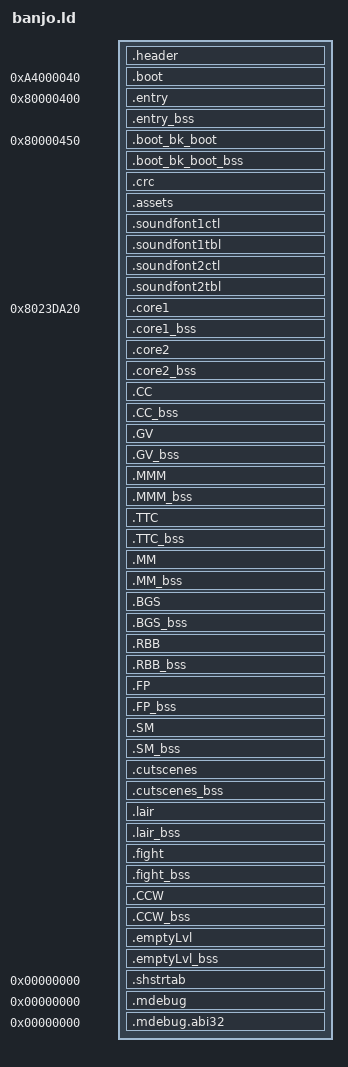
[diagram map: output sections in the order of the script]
SECTIONS
{
    __romPos = 0;
    header_ROM_START = __romPos;
    header_VRAM = ADDR(.header);
    .header : AT(header_ROM_START) SUBALIGN(16)
    {
        FILL(0x00000000);
        header_DATA_START = .;
        build/us.v10/asm/header.s.o(.data);
        header_DATA_END = .;
        header_DATA_SIZE = ABSOLUTE(header_DATA_END - header_DATA_START);
    }
    __romPos += SIZEOF(.header);
    header_ROM_END = __romPos;
    header_VRAM_END = .;

    boot_ROM_START = __romPos;
    boot_VRAM = ADDR(.boot);
    .boot 0xA4000040 : AT(boot_ROM_START) SUBALIGN(16)
    {
        FILL(0x00000000);
        boot_DATA_START = .;
        build/us.v10/bin/ipl3.bin.o(.data);
        build/us.v10/bin/ipl3font.bin.o(.data);
        . = ALIGN(., 16);
        boot_DATA_END = .;
        boot_DATA_SIZE = ABSOLUTE(boot_DATA_END - boot_DATA_START);
    }
    __romPos += SIZEOF(.boot);
    __romPos = ALIGN(__romPos, 16);
    . = ALIGN(., 16);
    boot_ROM_END = __romPos;
    boot_VRAM_END = .;

    entry_ROM_START = __romPos;
    entry_VRAM = ADDR(.entry);
    .entry 0x80000400 : AT(entry_ROM_START) SUBALIGN(16)
    {
        FILL(0x00000000);
        entry_TEXT_START = .;
        build/us.v10/asm/entry.s.o(.text);
        . = ALIGN(., 16);
        entry_TEXT_END = .;
        entry_TEXT_SIZE = ABSOLUTE(entry_TEXT_END - entry_TEXT_START);
        entry_DATA_START = .;
        build/us.v10/asm/entry.s.o(.data);
        . = ALIGN(., 16);
        entry_DATA_END = .;
        entry_DATA_SIZE = ABSOLUTE(entry_DATA_END - entry_DATA_START);
        entry_RODATA_START = .;
        build/us.v10/asm/entry.s.o(.rodata);
        . = ALIGN(., 16);
        entry_RODATA_END = .;
        entry_RODATA_SIZE = ABSOLUTE(entry_RODATA_END - entry_RODATA_START);
    }
    entry_bss_VRAM = ADDR(.entry_bss);
    .entry_bss (NOLOAD) : SUBALIGN(16)
    {
        FILL(0x00000000);
        entry_BSS_START = .;
        build/us.v10/asm/entry.s.o(.bss);
        . = ALIGN(., 16);
        entry_BSS_END = .;
        entry_BSS_SIZE = ABSOLUTE(entry_BSS_END - entry_BSS_START);
    }
    __romPos += SIZEOF(.entry);
    __romPos = ALIGN(__romPos, 16);
    . = ALIGN(., 16);
    entry_ROM_END = __romPos;
    entry_VRAM_END = .;

    boot_bk_boot_ROM_START = __romPos;
    boot_bk_boot_VRAM = ADDR(.boot_bk_boot);
    .boot_bk_boot 0x80000450 : AT(boot_bk_boot_ROM_START) SUBALIGN(16)
    {
        FILL(0x00000000);
        boot_bk_boot_TEXT_START = .;
        build/us.v10/src/boot/bk_boot_1050.c.o(.text);
        build/us.v10/src/boot/rarezip.c.o(.text);
        build/us.v10/src/boot/inflate.c.o(.text);
        build/us.v10/src/boot/overlaytable.c.o(.text);
        build/us.v10/libultra_rom_boot.a:initialize.o(.text);
        build/us.v10/libultra_rom_boot.a:pirawdma.o(.text);
        build/us.v10/libultra_rom_boot.a:pigetstat.o(.text);
        build/us.v10/libultra_rom_boot.a:bzero.o(.text);
        build/us.v10/libultra_rom_boot.a:setsr.o(.text);
        build/us.v10/libultra_rom_boot.a:getsr.o(.text);
        build/us.v10/libultra_rom_boot.a:setfpccsr.o(.text);
        build/us.v10/libultra_rom_boot.a:sirawread.o(.text);
        build/us.v10/libultra_rom_boot.a:sirawwrite.o(.text);
        build/us.v10/libultra_rom_boot.a:exceptasm.o(.text);
        build/us.v10/libultra_rom_boot.a:writebackdcache.o(.text);
        build/us.v10/libultra_rom_boot.a:invalicache.o(.text);
        build/us.v10/libultra_rom_boot.a:maptlbrdb.o(.text);
        build/us.v10/libultra_rom_boot.a:pirawread.o(.text);
        build/us.v10/libultra_rom_boot.a:ll.o(.text);
        build/us.v10/libultra_rom_boot.a:parameters.o(.text);
        build/us.v10/libultra_rom_boot.a:virtualtophysical.o(.text);
        build/us.v10/libultra_rom_boot.a:si.o(.text);
        build/us.v10/libultra_rom_boot.a:thread.o(.text);
        build/us.v10/libultra_rom_boot.a:leointerrupt.o(.text);
        build/us.v10/libultra_rom_boot.a:seteventmesg.o(.text);
        build/us.v10/libultra_rom_boot.a:setintmask.o(.text);
        build/us.v10/libultra_rom_boot.a:destroythread.o(.text);
        build/us.v10/libultra_rom_boot.a:probetlb.o(.text);
        build/us.v10/libultra_rom_boot.a:leodiskinit.o(.text);
        build/us.v10/libultra_rom_boot.a:epirawdma.o(.text);
        build/us.v10/libultra_rom_boot.a:interrupt.o(.text);
        build/us.v10/libultra_rom_boot.a:pimgr.o(.text);
        build/us.v10/libultra_rom_boot.a:cartrominit.o(.text);
        build/us.v10/libultra_rom_boot.a:createmesgqueue.o(.text);
        build/us.v10/libultra_rom_boot.a:piacs.o(.text);
        build/us.v10/libultra_rom_boot.a:getthreadpri.o(.text);
        build/us.v10/libultra_rom_boot.a:setthreadpri.o(.text);
        build/us.v10/libultra_rom_boot.a:createthread.o(.text);
        build/us.v10/libultra_rom_boot.a:devmgr.o(.text);
        build/us.v10/libultra_rom_boot.a:startthread.o(.text);
        build/us.v10/libultra_rom_boot.a:sendmesg.o(.text);
        build/us.v10/libultra_rom_boot.a:recvmesg.o(.text);
        build/us.v10/libultra_rom_boot.a:resetglobalintmask.o(.text);
        build/us.v10/libultra_rom_boot.a:epirawwrite.o(.text);
        build/us.v10/libultra_rom_boot.a:epirawread.o(.text);
        build/us.v10/libultra_rom_boot.a:setglobalintmask.o(.text);
        build/us.v10/libultra_rom_boot.a:yieldthread.o(.text);
        build/us.v10/libultra_rom_boot.a:kdebugserver.o(.text);
        . = ALIGN(., 16);
        boot_bk_boot_TEXT_END = .;
        boot_bk_boot_TEXT_SIZE = ABSOLUTE(boot_bk_boot_TEXT_END - boot_bk_boot_TEXT_START);
        boot_bk_boot_DATA_START = .;
        build/us.v10/src/boot/bk_boot_1050.c.o(.data);
        build/us.v10/src/boot/rarezip.c.o(.data);
        build/us.v10/src/boot/inflate.c.o(.data);
        build/us.v10/src/boot/overlaytable.c.o(.data);
        build/us.v10/libultra_rom_boot.a:initialize.o(.data);
        build/us.v10/libultra_rom_boot.a:exceptasm.o(.data);
        build/us.v10/libultra_rom_boot.a:thread.o(.data);
        build/us.v10/libultra_rom_boot.a:pimgr.o(.data);
        build/us.v10/libultra_rom_boot.a:piacs.o(.data);
        . = ALIGN(., 16);
        boot_bk_boot_DATA_END = .;
        boot_bk_boot_DATA_SIZE = ABSOLUTE(boot_bk_boot_DATA_END - boot_bk_boot_DATA_START);
        boot_bk_boot_RODATA_START = .;
        build/us.v10/src/boot/bk_boot_1050.c.o(.rodata);
        build/us.v10/src/boot/rarezip.c.o(.rodata);
        build/us.v10/src/boot/inflate.c.o(.rodata);
        build/us.v10/src/boot/overlaytable.c.o(.rodata);
        build/us.v10/libultra_rom_boot.a:exceptasm.o(.rodata);
        build/us.v10/libultra_rom_boot.a:setintmask.o(.rodata);
        build/us.v10/libultra_rom_boot.a:devmgr.o(.rodata);
        . = ALIGN(., 16);
        boot_bk_boot_RODATA_END = .;
        boot_bk_boot_RODATA_SIZE = ABSOLUTE(boot_bk_boot_RODATA_END - boot_bk_boot_RODATA_START);
    }
    boot_bk_boot_bss_VRAM = ADDR(.boot_bk_boot_bss);
    .boot_bk_boot_bss (NOLOAD) : SUBALIGN(16)
    {
        FILL(0x00000000);
        boot_bk_boot_BSS_START = .;
        build/us.v10/src/boot/bk_boot_1050.c.o(.bss);
        build/us.v10/src/boot/rarezip.c.o(.bss);
        build/us.v10/src/boot/inflate.c.o(.bss);
        build/us.v10/src/boot/overlaytable.c.o(.bss);
        build/us.v10/libultra_rom_boot.a:initialize.o(.bss);
        build/us.v10/libultra_rom_boot.a:kdebugserver.o(.bss);
        build/us.v10/libultra_rom_boot.a:leointerrupt.o(.bss);
        build/us.v10/libultra_rom_boot.a:seteventmesg.o(.bss);
        build/us.v10/libultra_rom_boot.a:leodiskinit.o(.bss);
        build/us.v10/libultra_rom_boot.a:pimgr.o(.bss);
        build/us.v10/libultra_rom_boot.a:cartrominit.o(.bss);
        build/us.v10/libultra_rom_boot.a:piacs.o(.bss);
        . = ALIGN(., 16);
        boot_bk_boot_BSS_END = .;
        boot_bk_boot_BSS_SIZE = ABSOLUTE(boot_bk_boot_BSS_END - boot_bk_boot_BSS_START);
    }
    __romPos += SIZEOF(.boot_bk_boot);
    __romPos = ALIGN(__romPos, 16);
    . = ALIGN(., 16);
    boot_bk_boot_ROM_END = __romPos;
    boot_bk_boot_VRAM_END = .;

    crc_ROM_START = __romPos;
    crc_VRAM = ADDR(.crc);
    .crc : AT(crc_ROM_START) SUBALIGN(16)
    {
        FILL(0x00000000);
        crc_DATA_START = .;
        build/us.v10/bin/crc.bin.o(.data);
        . = ALIGN(., 16);
        crc_DATA_END = .;
        crc_DATA_SIZE = ABSOLUTE(crc_DATA_END - crc_DATA_START);
    }
    __romPos += SIZEOF(.crc);
    __romPos = ALIGN(__romPos, 16);
    . = ALIGN(., 16);
    crc_ROM_END = __romPos;
    crc_VRAM_END = .;

    assets_ROM_START = __romPos;
    assets_VRAM = ADDR(.assets);
    .assets : AT(assets_ROM_START) SUBALIGN(16)
    {
        FILL(0x00000000);
        assets_DATA_START = .;
        build/us.v10/bin/assets.bin.o(.data);
        assets_DATA_END = .;
        assets_DATA_SIZE = ABSOLUTE(assets_DATA_END - assets_DATA_START);
    }
    __romPos += SIZEOF(.assets);
    assets_ROM_END = __romPos;
    assets_VRAM_END = .;

    soundfont1ctl_ROM_START = __romPos;
    soundfont1ctl_VRAM = ADDR(.soundfont1ctl);
    .soundfont1ctl : AT(soundfont1ctl_ROM_START) SUBALIGN(16)
    {
        FILL(0x00000000);
        soundfont1ctl_DATA_START = .;
        build/us.v10/bin/soundfont1ctl.bin.o(.data);
        soundfont1ctl_DATA_END = .;
        soundfont1ctl_DATA_SIZE = ABSOLUTE(soundfont1ctl_DATA_END - soundfont1ctl_DATA_START);
    }
    __romPos += SIZEOF(.soundfont1ctl);
    soundfont1ctl_ROM_END = __romPos;
    soundfont1ctl_VRAM_END = .;

    soundfont1tbl_ROM_START = __romPos;
    soundfont1tbl_VRAM = ADDR(.soundfont1tbl);
    .soundfont1tbl : AT(soundfont1tbl_ROM_START) SUBALIGN(16)
    {
        FILL(0x00000000);
        soundfont1tbl_DATA_START = .;
        build/us.v10/bin/soundfont1tbl.bin.o(.data);
        soundfont1tbl_DATA_END = .;
        soundfont1tbl_DATA_SIZE = ABSOLUTE(soundfont1tbl_DATA_END - soundfont1tbl_DATA_START);
    }
    __romPos += SIZEOF(.soundfont1tbl);
    soundfont1tbl_ROM_END = __romPos;
    soundfont1tbl_VRAM_END = .;

    soundfont2ctl_ROM_START = __romPos;
    soundfont2ctl_VRAM = ADDR(.soundfont2ctl);
    .soundfont2ctl : AT(soundfont2ctl_ROM_START) SUBALIGN(16)
    {
        FILL(0x00000000);
        soundfont2ctl_DATA_START = .;
        build/us.v10/bin/soundfont2ctl.bin.o(.data);
        soundfont2ctl_DATA_END = .;
        soundfont2ctl_DATA_SIZE = ABSOLUTE(soundfont2ctl_DATA_END - soundfont2ctl_DATA_START);
    }
    __romPos += SIZEOF(.soundfont2ctl);
    soundfont2ctl_ROM_END = __romPos;
    soundfont2ctl_VRAM_END = .;

    soundfont2tbl_ROM_START = __romPos;
    soundfont2tbl_VRAM = ADDR(.soundfont2tbl);
    .soundfont2tbl : AT(soundfont2tbl_ROM_START) SUBALIGN(16)
    {
        FILL(0x00000000);
        soundfont2tbl_DATA_START = .;
        build/us.v10/bin/soundfont2tbl.bin.o(.data);
        soundfont2tbl_DATA_END = .;
        soundfont2tbl_DATA_SIZE = ABSOLUTE(soundfont2tbl_DATA_END - soundfont2tbl_DATA_START);
    }
    __romPos += SIZEOF(.soundfont2tbl);
    soundfont2tbl_ROM_END = __romPos;
    soundfont2tbl_VRAM_END = .;

    core1_ROM_START = __romPos;
    core1_VRAM = ADDR(.core1);
    .core1 0x8023DA20 : AT(core1_ROM_START) SUBALIGN(4)
    {
        FILL(0x00000000);
        core1_TEXT_START = .;
        build/us.v10/src/core1/code_0.c.o(.text);
        build/us.v10/src/core1/code_660.c.o(.text);
        build/us.v10/src/core1/inflate.c.o(.text);
        build/us.v10/src/core1/code_1D00.c.o(.text);
        build/us.v10/src/core1/pimanager.c.o(.text);
        build/us.v10/src/core1/defragmanager.c.o(.text);
        build/us.v10/src/core1/stub_2FA0.c.o(.text);
        build/us.v10/src/core1/initthread.c.o(.text);
        build/us.v10/src/core1/code_3250.c.o(.text);
        build/us.v10/src/core1/stub_3A70.c.o(.text);
        build/us.v10/src/core1/code_5650.c.o(.text);
        build/us.v10/src/core1/code_7090.c.o(.text);
        build/us.v10/src/core1/code_72B0.c.o(.text);
        build/us.v10/src/core1/code_7F60.c.o(.text);
        build/us.v10/src/core1/code_8C50.c.o(.text);
        build/us.v10/src/core1/debugtext.c.o(.text);
        build/us.v10/src/core1/framebufferdraw.c.o(.text);
        build/us.v10/src/core1/code_CE60.c.o(.text);
        build/us.v10/src/core1/vimgr.c.o(.text);
        build/us.v10/src/core1/viewport.c.o(.text);
        build/us.v10/src/core1/joy.c.o(.text);
        build/us.v10/src/core1/code_11AC0.c.o(.text);
        build/us.v10/src/core1/bamotor.c.o(.text);
        build/us.v10/src/core1/stub_13640.c.o(.text);
        build/us.v10/src/core1/sprite.c.o(.text);
        build/us.v10/src/core1/overlaymanager.c.o(.text);
        build/us.v10/src/core1/mlmtx.c.o(.text);
        build/us.v10/asm/core1/bkmemops64.s.o(.text);
        build/us.v10/src/core1/overlay.c.o(.text);
        build/us.v10/src/core1/depthbuffer.c.o(.text);
        build/us.v10/src/core1/code_15B30.c.o(.text);
        build/us.v10/src/core1/memory.c.o(.text);
        build/us.v10/src/core1/eeprom.c.o(.text);
        build/us.v10/src/core1/ucode.c.o(.text);
        build/us.v10/src/core1/lookup.c.o(.text);
        build/us.v10/src/core1/ml.c.o(.text);
        build/us.v10/src/core1/musicplayer.c.o(.text);
        build/us.v10/src/core1/stub_1D590.c.o(.text);
        build/us.v10/asm/core1/bkgetsr.s.o(.text);
        build/us.v10/src/core1/code_1D5D0.c.o(.text);
        build/us.v10/src/core1/sns.c.o(.text);
        build/us.v10/src/core1/glcrc.c.o(.text);
        build/us.v10/asm/core1/code_1E820.s.o(.text);
        build/us.v10/src/core1/n_audio/n_sl.c.o(.text);
        build/us.v10/src/core1/n_audio/n_synthesizer.c.o(.text);
        build/us.v10/libultra_rom.a:event.o(.text);
        build/us.v10/src/core1/n_audio/n_synaddplayer.c.o(.text);
        build/us.v10/src/core1/n_audio/n_synallocvoice.c.o(.text);
        build/us.v10/src/core1/n_audio/n_synsetvol.c.o(.text);
        build/us.v10/src/core1/n_audio/n_synstartvoice.c.o(.text);
        build/us.v10/src/core1/n_audio/n_synsetpan.c.o(.text);
        build/us.v10/src/core1/n_audio/n_synsetpitch.c.o(.text);
        build/us.v10/src/core1/n_audio/n_synsetfxmix.c.o(.text);
        build/us.v10/src/core1/n_audio/n_synstopvoice.c.o(.text);
        build/us.v10/src/core1/n_audio/n_synfreevoice.c.o(.text);
        build/us.v10/src/core1/n_audio/n_csplayer.c.o(.text);
        build/us.v10/libultra_rom.a:cspsetbank.o(.text);
        build/us.v10/libultra_rom.a:cspstop.o(.text);
        build/us.v10/src/core1/n_audio/n_csq.c.o(.text);
        build/us.v10/libultra_rom.a:cspsetseq.o(.text);
        build/us.v10/libultra_rom.a:cspplay.o(.text);
        build/us.v10/libultra_rom.a:cspsetvol.o(.text);
        build/us.v10/src/core1/ultra/audio/code_219D0.c.o(.text);
        build/us.v10/libultra_rom.a:cspsettempo.o(.text);
        build/us.v10/src/core1/n_audio/code_21A80.c.o(.text);
        build/us.v10/libultra_rom.a:cspgettempo.o(.text);
        build/us.v10/src/core1/ultra/audio/code_21AF0.c.o(.text);
        build/us.v10/src/core1/n_audio/code_21B50.c.o(.text);
        build/us.v10/src/core1/n_audio/n_syndelete.c.o(.text);
        build/us.v10/src/core1/n_audio/n_synallocfx.c.o(.text);
        build/us.v10/src/core1/n_audio/n_reverb.c.o(.text);
        build/us.v10/src/core1/n_audio/n_auxbus.c.o(.text);
        build/us.v10/src/core1/n_audio/n_drvrNew.c.o(.text);
        build/us.v10/src/core1/n_audio/n_save.c.o(.text);
        build/us.v10/src/core1/n_audio/n_envresample.c.o(.text);
        build/us.v10/src/core1/n_audio/n_env.c.o(.text);
        build/us.v10/src/core1/n_audio/n_seqplayer.c.o(.text);
        build/us.v10/src/core1/n_audio/n_synstartvoiceparam.c.o(.text);
        build/us.v10/src/core1/n_audio/n_mainbus.c.o(.text);
        build/us.v10/src/core1/n_audio/n_load.c.o(.text);
        build/us.v10/src/core1/n_audio/n_adpcm.c.o(.text);
        build/us.v10/src/core1/n_audio/n_resample.c.o(.text);
        build/us.v10/src/core1/n_audio/n_seq.c.o(.text);
        build/us.v10/src/core1/n_audio/n_synsetpriority.c.o(.text);
        build/us.v10/libultra_rom.a:bzero.o(.text);
        build/us.v10/libultra_rom.a:writebackdcacheall.o(.text);
        build/us.v10/libultra_rom.a:initialize.o(.text);
        build/us.v10/libultra_rom.a:createthread.o(.text);
        build/us.v10/libultra_rom.a:sinf.o(.text);
        build/us.v10/libultra_rom.a:cents2ratio.o(.text);
        build/us.v10/libultra_rom.a:heapinit.o(.text);
        build/us.v10/libultra_rom.a:parameters.o(.text);
        build/us.v10/libultra_rom.a:createmesgqueue.o(.text);
        build/us.v10/libultra_rom.a:aisetfreq.o(.text);
        build/us.v10/libultra_rom.a:sl.o(.text);
        build/us.v10/libultra_rom.a:heapalloc.o(.text);
        build/us.v10/libultra_rom.a:recvmesg.o(.text);
        build/us.v10/libultra_rom.a:aigetlen.o(.text);
        build/us.v10/libultra_rom.a:virtualtophysical.o(.text);
        build/us.v10/libultra_rom.a:aisetnextbuf.o(.text);
        build/us.v10/libultra_rom.a:pidma.o(.text);
        build/us.v10/libultra_rom.a:stopthread.o(.text);
        build/us.v10/libultra_rom.a:startthread.o(.text);
        build/us.v10/libultra_rom.a:writebackdcache.o(.text);
        build/us.v10/libultra_rom.a:invaldcache.o(.text);
        build/us.v10/libultra_rom.a:pimgr.o(.text);
        build/us.v10/libultra_rom.a:destroythread.o(.text);
        build/us.v10/libultra_rom.a:sendmesg.o(.text);
        build/us.v10/libultra_rom.a:setthreadpri.o(.text);
        build/us.v10/libultra_rom.a:mtxutil.o(.text);
        build/us.v10/libultra_rom.a:sqrtf.o(.text);
        build/us.v10/libultra_rom.a:cosf.o(.text);
        build/us.v10/libultra_rom.a:setintmask.o(.text);
        build/us.v10/libultra_rom.a:dpsetstat.o(.text);
        build/us.v10/libultra_rom.a:sptask.o(.text);
        build/us.v10/libultra_rom.a:dpgetstat.o(.text);
        build/us.v10/libultra_rom.a:vigetcurrframebuf.o(.text);
        build/us.v10/libultra_rom.a:stoptimer.o(.text);
        build/us.v10/libultra_rom.a:settimer.o(.text);
        build/us.v10/libultra_rom.a:ll.o(.text);
        build/us.v10/libultra_rom.a:sptaskyielded.o(.text);
        build/us.v10/libultra_rom.a:sptaskyield.o(.text);
        build/us.v10/libultra_rom.a:visetmode.o(.text);
        build/us.v10/libultra_rom.a:seteventmesg.o(.text);
        build/us.v10/libultra_rom.a:vimgr.o(.text);
        build/us.v10/libultra_rom.a:visetspecial.o(.text);
        build/us.v10/libultra_rom.a:viswapbuf.o(.text);
        build/us.v10/libultra_rom.a:visetevent.o(.text);
        build/us.v10/libultra_rom.a:vigetnextframebuf.o(.text);
        build/us.v10/libultra_rom.a:viblack.o(.text);
        build/us.v10/libultra_rom.a:ortho.o(.text);
        build/us.v10/libultra_rom.a:translate.o(.text);
        build/us.v10/libultra_rom.a:rotate.o(.text);
        build/us.v10/libultra_rom.a:contreaddata.o(.text);
        build/us.v10/libultra_rom.a:controller.o(.text);
        build/us.v10/libultra_rom.a:contsetch.o(.text);
        build/us.v10/libultra_rom.a:bnkf.o(.text);
        build/us.v10/libultra_rom.a:gettime.o(.text);
        build/us.v10/libultra_rom.a:cseq.o(.text);
        build/us.v10/libultra_rom.a:motor.o(.text);
        build/us.v10/libultra_rom.a:pfsinit.o(.text);
        build/us.v10/libultra_rom.a:invalicache.o(.text);
        build/us.v10/libultra_rom.a:conteeplongwrite.o(.text);
        build/us.v10/libultra_rom.a:conteeplongread.o(.text);
        build/us.v10/libultra_rom.a:piread.o(.text);
        build/us.v10/libultra_rom.a:copy.o(.text);
        build/us.v10/libultra_rom.a:drvrnew.o(.text);
        build/us.v10/libultra_rom.a:reverb.o(.text);
        build/us.v10/libultra_rom.a:syncprintf.o(.text);
        build/us.v10/libultra_rom.a:seq.o(.text);
        build/us.v10/libultra_rom.a:setsr.o(.text);
        build/us.v10/libultra_rom.a:getsr.o(.text);
        build/us.v10/libultra_rom.a:setfpccsr.o(.text);
        build/us.v10/libultra_rom.a:sirawread.o(.text);
        build/us.v10/libultra_rom.a:sirawwrite.o(.text);
        build/us.v10/libultra_rom.a:exceptasm.o(.text);
        build/us.v10/libultra_rom.a:maptlbrdb.o(.text);
        build/us.v10/libultra_rom.a:pirawread.o(.text);
        build/us.v10/libultra_rom.a:interrupt.o(.text);
        build/us.v10/libultra_rom.a:thread.o(.text);
        build/us.v10/libultra_rom.a:synthesizer.o(.text);
        build/us.v10/libultra_rom.a:syndelete.o(.text);
        build/us.v10/libultra_rom.a:probetlb.o(.text);
        build/us.v10/libultra_rom.a:ai.o(.text);
        build/us.v10/libultra_rom.a:jammesg.o(.text);
        build/us.v10/libultra_rom.a:pigetcmdq.o(.text);
        build/us.v10/libultra_rom.a:cartrominit.o(.text);
        build/us.v10/libultra_rom.a:leodiskinit.o(.text);
        build/us.v10/libultra_rom.a:piacs.o(.text);
        build/us.v10/libultra_rom.a:getthreadpri.o(.text);
        build/us.v10/libultra_rom.a:pirawdma.o(.text);
        build/us.v10/libultra_rom.a:epirawdma.o(.text);
        build/us.v10/libultra_rom.a:devmgr.o(.text);
        build/us.v10/libultra_rom.a:bcopy.o(.text);
        build/us.v10/libultra_rom.a:spsetstat.o(.text);
        build/us.v10/libultra_rom.a:spsetpc.o(.text);
        build/us.v10/libultra_rom.a:sprawdma.o(.text);
        build/us.v10/libultra_rom.a:sp.o(.text);
        build/us.v10/libultra_rom.a:vi.o(.text);
        build/us.v10/libultra_rom.a:timerintr.o(.text);
        build/us.v10/libultra_rom.a:setcompare.o(.text);
        build/us.v10/libultra_rom.a:spgetstat.o(.text);
        build/us.v10/libultra_rom.a:vigetcurrcontext.o(.text);
        build/us.v10/libultra_rom.a:viswapcontext.o(.text);
        build/us.v10/libultra_rom.a:getcount.o(.text);
        build/us.v10/libultra_rom.a:normalize.o(.text);
        build/us.v10/libultra_rom.a:siacs.o(.text);
        build/us.v10/libultra_rom.a:sirawdma.o(.text);
        build/us.v10/libultra_rom.a:pfsisplug.o(.text);
        build/us.v10/libultra_rom.a:crc.o(.text);
        build/us.v10/libultra_rom.a:contramwrite.o(.text);
        build/us.v10/libultra_rom.a:contramread.o(.text);
        build/us.v10/libultra_rom.a:pfsgetstatus.o(.text);
        build/us.v10/libultra_rom.a:contpfs.o(.text);
        build/us.v10/libultra_rom.a:pfschecker.o(.text);
        build/us.v10/libultra_rom.a:conteepwrite.o(.text);
        build/us.v10/libultra_rom.a:conteepread.o(.text);
        build/us.v10/libultra_rom.a:filter.o(.text);
        build/us.v10/libultra_rom.a:env.o(.text);
        build/us.v10/libultra_rom.a:load.o(.text);
        build/us.v10/libultra_rom.a:resample.o(.text);
        build/us.v10/libultra_rom.a:auxbus.o(.text);
        build/us.v10/libultra_rom.a:mainbus.o(.text);
        build/us.v10/libultra_rom.a:save.o(.text);
        build/us.v10/libultra_rom.a:si.o(.text);
        build/us.v10/libultra_rom.a:leointerrupt.o(.text);
        build/us.v10/libultra_rom.a:synallocfx.o(.text);
        build/us.v10/libultra_rom.a:resetglobalintmask.o(.text);
        build/us.v10/libultra_rom.a:epirawwrite.o(.text);
        build/us.v10/libultra_rom.a:epirawread.o(.text);
        build/us.v10/libultra_rom.a:setglobalintmask.o(.text);
        build/us.v10/libultra_rom.a:yieldthread.o(.text);
        build/us.v10/asm/data/core1/n_aspMain.s.o(.text);
        build/us.v10/asm/data/core1/gSPF3DEX_fifo.s.o(.text);
        build/us.v10/asm/data/core1/gSPL3DEX_fifo.s.o(.text);
        core1_DATA_START_OFFSET = .;
        . = ALIGN(., 16);
        core1_TEXT_END = .;
        core1_TEXT_SIZE = ABSOLUTE(core1_TEXT_END - core1_TEXT_START);
        core1_DATA_START = .;
        build/us.v10/src/core1/code_0.c.o(.data);
        build/us.v10/src/core1/code_660.c.o(.data);
        build/us.v10/src/core1/inflate.c.o(.data);
        build/us.v10/src/core1/code_1D00.c.o(.data);
        build/us.v10/src/core1/pimanager.c.o(.data);
        build/us.v10/src/core1/defragmanager.c.o(.data);
        build/us.v10/src/core1/stub_2FA0.c.o(.data);
        build/us.v10/src/core1/initthread.c.o(.data);
        build/us.v10/src/core1/code_3250.c.o(.data);
        build/us.v10/src/core1/stub_3A70.c.o(.data);
        build/us.v10/src/core1/code_5650.c.o(.data);
        build/us.v10/src/core1/code_7090.c.o(.data);
        build/us.v10/src/core1/code_72B0.c.o(.data);
        build/us.v10/src/core1/code_7F60.c.o(.data);
        build/us.v10/src/core1/code_8C50.c.o(.data);
        build/us.v10/src/core1/debugtext.c.o(.data);
        build/us.v10/src/core1/framebufferdraw.c.o(.data);
        build/us.v10/src/core1/code_CE60.c.o(.data);
        build/us.v10/src/core1/vimgr.c.o(.data);
        build/us.v10/src/core1/viewport.c.o(.data);
        build/us.v10/src/core1/joy.c.o(.data);
        build/us.v10/src/core1/code_11AC0.c.o(.data);
        build/us.v10/src/core1/bamotor.c.o(.data);
        build/us.v10/src/core1/stub_13640.c.o(.data);
        build/us.v10/src/core1/sprite.c.o(.data);
        build/us.v10/src/core1/overlaymanager.c.o(.data);
        build/us.v10/src/core1/mlmtx.c.o(.data);
        build/us.v10/asm/core1/bkmemops64.s.o(.data);
        build/us.v10/src/core1/overlay.c.o(.data);
        build/us.v10/src/core1/depthbuffer.c.o(.data);
        build/us.v10/src/core1/code_15B30.c.o(.data);
        build/us.v10/src/core1/memory.c.o(.data);
        build/us.v10/src/core1/eeprom.c.o(.data);
        build/us.v10/src/core1/ucode.c.o(.data);
        build/us.v10/src/core1/lookup.c.o(.data);
        build/us.v10/src/core1/ml.c.o(.data);
        build/us.v10/src/core1/musicplayer.c.o(.data);
        build/us.v10/src/core1/stub_1D590.c.o(.data);
        build/us.v10/asm/core1/bkgetsr.s.o(.data);
        build/us.v10/src/core1/code_1D5D0.c.o(.data);
        build/us.v10/src/core1/sns.c.o(.data);
        build/us.v10/src/core1/glcrc.c.o(.data);
        build/us.v10/asm/core1/code_1E820.s.o(.data);
        build/us.v10/src/core1/data_1E820.c.o(.data);
        build/us.v10/src/core1/n_audio/n_sl.c.o(.data);
        build/us.v10/src/core1/n_audio/n_synthesizer.c.o(.data);
        build/us.v10/src/core1/n_audio/n_synaddplayer.c.o(.data);
        build/us.v10/src/core1/n_audio/n_synallocvoice.c.o(.data);
        build/us.v10/src/core1/n_audio/n_synsetvol.c.o(.data);
        build/us.v10/src/core1/n_audio/n_synstartvoice.c.o(.data);
        build/us.v10/src/core1/n_audio/n_synsetpan.c.o(.data);
        build/us.v10/src/core1/n_audio/n_synsetpitch.c.o(.data);
        build/us.v10/src/core1/n_audio/n_synsetfxmix.c.o(.data);
        build/us.v10/src/core1/n_audio/n_synstopvoice.c.o(.data);
        build/us.v10/src/core1/n_audio/n_synfreevoice.c.o(.data);
        build/us.v10/src/core1/n_audio/n_csplayer.c.o(.data);
        build/us.v10/src/core1/n_audio/n_csq.c.o(.data);
        build/us.v10/src/core1/ultra/audio/code_219D0.c.o(.data);
        build/us.v10/src/core1/n_audio/code_21A80.c.o(.data);
        build/us.v10/src/core1/ultra/audio/code_21AF0.c.o(.data);
        build/us.v10/src/core1/n_audio/code_21B50.c.o(.data);
        build/us.v10/src/core1/n_audio/n_syndelete.c.o(.data);
        build/us.v10/src/core1/n_audio/n_synallocfx.c.o(.data);
        build/us.v10/src/core1/n_audio/n_reverb.c.o(.data);
        build/us.v10/src/core1/n_audio/n_auxbus.c.o(.data);
        build/us.v10/src/core1/n_audio/n_drvrNew.c.o(.data);
        build/us.v10/src/core1/n_audio/n_save.c.o(.data);
        build/us.v10/src/core1/n_audio/n_envresample.c.o(.data);
        build/us.v10/src/core1/n_audio/n_env.c.o(.data);
        build/us.v10/src/core1/n_audio/n_seqplayer.c.o(.data);
        build/us.v10/src/core1/n_audio/n_synstartvoiceparam.c.o(.data);
        build/us.v10/src/core1/n_audio/n_mainbus.c.o(.data);
        build/us.v10/src/core1/n_audio/n_load.c.o(.data);
        build/us.v10/src/core1/n_audio/n_adpcm.c.o(.data);
        build/us.v10/src/core1/n_audio/n_resample.c.o(.data);
        build/us.v10/src/core1/n_audio/n_seq.c.o(.data);
        build/us.v10/src/core1/n_audio/n_synsetpriority.c.o(.data);
        build/us.v10/asm/data/core1/n_aspMain.s.o(.data);
        build/us.v10/asm/data/core1/gSPF3DEX_fifo.s.o(.data);
        build/us.v10/asm/data/core1/gSPL3DEX_fifo.s.o(.data);
        build/us.v10/libultra_rom.a:initialize.o(.data);
        build/us.v10/libultra_rom.a:sl.o(.data);
        build/us.v10/libultra_rom.a:aisetnextbuf.o(.data);
        build/us.v10/libultra_rom.a:pimgr.o(.data);
        build/us.v10/libultra_rom.a:vimgr.o(.data);
        build/us.v10/libultra_rom.a:controller.o(.data);
        build/us.v10/libultra_rom.a:drvrnew.o(.data);
        build/us.v10/libultra_rom.a:exceptasm.o(.data);
        build/us.v10/libultra_rom.a:thread.o(.data);
        build/us.v10/libultra_rom.a:piacs.o(.data);
        build/us.v10/libultra_rom.a:vi.o(.data);
        build/us.v10/libultra_rom.a:timerintr.o(.data);
        build/us.v10/libultra_rom.a:siacs.o(.data);
        build/us.v10/libultra_rom.a:env.o(.data);
        build/us.v10/libultra_rom.a:vimodepallan1.o(.data);
        build/us.v10/libultra_rom.a:vimodempallan1.o(.data);
        build/us.v10/libultra_rom.a:vimodentsclan1.o(.data);
        . = ALIGN(., 16);
        core1_DATA_END = .;
        core1_DATA_SIZE = ABSOLUTE(core1_DATA_END - core1_DATA_START);
        core1_RODATA_START = .;
        build/us.v10/src/core1/code_0.c.o(.rodata);
        build/us.v10/src/core1/code_660.c.o(.rodata);
        build/us.v10/src/core1/inflate.c.o(.rodata);
        build/us.v10/src/core1/code_1D00.c.o(.rodata);
        build/us.v10/src/core1/pimanager.c.o(.rodata);
        build/us.v10/src/core1/defragmanager.c.o(.rodata);
        build/us.v10/src/core1/stub_2FA0.c.o(.rodata);
        build/us.v10/src/core1/initthread.c.o(.rodata);
        build/us.v10/src/core1/code_3250.c.o(.rodata);
        build/us.v10/src/core1/stub_3A70.c.o(.rodata);
        build/us.v10/src/core1/code_5650.c.o(.rodata);
        build/us.v10/src/core1/code_7090.c.o(.rodata);
        build/us.v10/src/core1/code_72B0.c.o(.rodata);
        build/us.v10/src/core1/code_7F60.c.o(.rodata);
        build/us.v10/src/core1/code_8C50.c.o(.rodata);
        build/us.v10/src/core1/debugtext.c.o(.rodata);
        build/us.v10/src/core1/framebufferdraw.c.o(.rodata);
        build/us.v10/src/core1/code_CE60.c.o(.rodata);
        build/us.v10/src/core1/vimgr.c.o(.rodata);
        build/us.v10/src/core1/viewport.c.o(.rodata);
        build/us.v10/src/core1/joy.c.o(.rodata);
        build/us.v10/src/core1/code_11AC0.c.o(.rodata);
        build/us.v10/src/core1/bamotor.c.o(.rodata);
        build/us.v10/src/core1/stub_13640.c.o(.rodata);
        build/us.v10/src/core1/sprite.c.o(.rodata);
        build/us.v10/src/core1/overlaymanager.c.o(.rodata);
        build/us.v10/src/core1/mlmtx.c.o(.rodata);
        build/us.v10/asm/core1/bkmemops64.s.o(.rodata);
        build/us.v10/src/core1/overlay.c.o(.rodata);
        build/us.v10/src/core1/depthbuffer.c.o(.rodata);
        build/us.v10/src/core1/code_15B30.c.o(.rodata);
        build/us.v10/src/core1/memory.c.o(.rodata);
        build/us.v10/src/core1/eeprom.c.o(.rodata);
        build/us.v10/src/core1/ucode.c.o(.rodata);
        build/us.v10/src/core1/lookup.c.o(.rodata);
        build/us.v10/src/core1/ml.c.o(.rodata);
        build/us.v10/src/core1/musicplayer.c.o(.rodata);
        build/us.v10/src/core1/stub_1D590.c.o(.rodata);
        build/us.v10/asm/core1/bkgetsr.s.o(.rodata);
        build/us.v10/src/core1/code_1D5D0.c.o(.rodata);
        build/us.v10/src/core1/sns.c.o(.rodata);
        build/us.v10/src/core1/glcrc.c.o(.rodata);
        build/us.v10/asm/core1/code_1E820.s.o(.rodata);
        build/us.v10/src/core1/n_audio/n_sl.c.o(.rodata);
        build/us.v10/src/core1/n_audio/n_synthesizer.c.o(.rodata);
        build/us.v10/src/core1/n_audio/n_synaddplayer.c.o(.rodata);
        build/us.v10/src/core1/n_audio/n_synallocvoice.c.o(.rodata);
        build/us.v10/src/core1/n_audio/n_synsetvol.c.o(.rodata);
        build/us.v10/src/core1/n_audio/n_synstartvoice.c.o(.rodata);
        build/us.v10/src/core1/n_audio/n_synsetpan.c.o(.rodata);
        build/us.v10/src/core1/n_audio/n_synsetpitch.c.o(.rodata);
        build/us.v10/src/core1/n_audio/n_synsetfxmix.c.o(.rodata);
        build/us.v10/src/core1/n_audio/n_synstopvoice.c.o(.rodata);
        build/us.v10/src/core1/n_audio/n_synfreevoice.c.o(.rodata);
        build/us.v10/src/core1/n_audio/n_csplayer.c.o(.rodata);
        build/us.v10/src/core1/n_audio/n_csq.c.o(.rodata);
        build/us.v10/src/core1/ultra/audio/code_219D0.c.o(.rodata);
        build/us.v10/src/core1/n_audio/code_21A80.c.o(.rodata);
        build/us.v10/src/core1/ultra/audio/code_21AF0.c.o(.rodata);
        build/us.v10/src/core1/n_audio/code_21B50.c.o(.rodata);
        build/us.v10/src/core1/n_audio/n_syndelete.c.o(.rodata);
        build/us.v10/src/core1/n_audio/n_synallocfx.c.o(.rodata);
        build/us.v10/src/core1/n_audio/n_reverb.c.o(.rodata);
        build/us.v10/src/core1/n_audio/n_auxbus.c.o(.rodata);
        build/us.v10/src/core1/n_audio/n_drvrNew.c.o(.rodata);
        build/us.v10/src/core1/n_audio/n_save.c.o(.rodata);
        build/us.v10/src/core1/n_audio/n_envresample.c.o(.rodata);
        build/us.v10/src/core1/n_audio/n_env.c.o(.rodata);
        build/us.v10/src/core1/n_audio/n_seqplayer.c.o(.rodata);
        build/us.v10/src/core1/n_audio/n_synstartvoiceparam.c.o(.rodata);
        build/us.v10/src/core1/n_audio/n_mainbus.c.o(.rodata);
        build/us.v10/src/core1/n_audio/n_load.c.o(.rodata);
        build/us.v10/src/core1/n_audio/n_adpcm.c.o(.rodata);
        build/us.v10/src/core1/n_audio/n_resample.c.o(.rodata);
        build/us.v10/src/core1/n_audio/n_seq.c.o(.rodata);
        build/us.v10/src/core1/n_audio/n_synsetpriority.c.o(.rodata);
        build/us.v10/libultra_rom.a:sinf.o(.rodata);
        build/us.v10/libultra_rom.a:cents2ratio.o(.rodata);
        build/us.v10/libultra_rom.a:cosf.o(.rodata);
        build/us.v10/libultra_rom.a:setintmask.o(.rodata);
        build/us.v10/libultra_rom.a:rotate.o(.rodata);
        build/us.v10/libultra_rom.a:cseq.o(.rodata);
        build/us.v10/libultra_rom.a:drvrnew.o(.rodata);
        build/us.v10/libultra_rom.a:reverb.o(.rodata);
        build/us.v10/libultra_rom.a:seq.o(.rodata);
        build/us.v10/libultra_rom.a:exceptasm.o(.rodata);
        build/us.v10/libultra_rom.a:libm_vals.o(.rodata);
        build/us.v10/libultra_rom.a:synthesizer.o(.rodata);
        build/us.v10/libultra_rom.a:devmgr.o(.rodata);
        build/us.v10/libultra_rom.a:env.o(.rodata);
        build/us.v10/libultra_rom.a:resample.o(.rodata);
        build/us.v10/asm/data/core1/n_aspMain.s.o(.rodata);
        build/us.v10/asm/data/core1/gSPF3DEX_fifo.s.o(.rodata);
        build/us.v10/asm/data/core1/gSPL3DEX_fifo.s.o(.rodata);
        . = ALIGN(., 16);
        core1_RODATA_END = .;
        core1_RODATA_SIZE = ABSOLUTE(core1_RODATA_END - core1_RODATA_START);
    }
    core1_bss_VRAM = ADDR(.core1_bss);
    .core1_bss (NOLOAD) : SUBALIGN(4)
    {
        FILL(0x00000000);
        core1_BSS_START = .;
        build/us.v10/src/core1/code_0.c.o(.bss);
        build/us.v10/src/core1/code_660.c.o(.bss);
        build/us.v10/src/core1/inflate.c.o(.bss);
        build/us.v10/src/core1/code_1D00.c.o(.bss);
        build/us.v10/src/core1/pimanager.c.o(.bss);
        build/us.v10/src/core1/defragmanager.c.o(.bss);
        build/us.v10/src/core1/stub_2FA0.c.o(.bss);
        build/us.v10/src/core1/initthread.c.o(.bss);
        build/us.v10/src/core1/code_3250.c.o(.bss);
        build/us.v10/src/core1/stub_3A70.c.o(.bss);
        build/us.v10/src/core1/code_5650.c.o(.bss);
        build/us.v10/src/core1/code_7090.c.o(.bss);
        build/us.v10/src/core1/code_72B0.c.o(.bss);
        build/us.v10/src/core1/code_7F60.c.o(.bss);
        build/us.v10/src/core1/code_8C50.c.o(.bss);
        build/us.v10/src/core1/debugtext.c.o(.bss);
        build/us.v10/src/core1/framebufferdraw.c.o(.bss);
        build/us.v10/src/core1/code_CE60.c.o(.bss);
        build/us.v10/src/core1/vimgr.c.o(.bss);
        build/us.v10/src/core1/viewport.c.o(.bss);
        build/us.v10/src/core1/joy.c.o(.bss);
        build/us.v10/src/core1/code_11AC0.c.o(.bss);
        build/us.v10/src/core1/bamotor.c.o(.bss);
        build/us.v10/src/core1/stub_13640.c.o(.bss);
        build/us.v10/src/core1/sprite.c.o(.bss);
        build/us.v10/src/core1/overlaymanager.c.o(.bss);
        build/us.v10/src/core1/mlmtx.c.o(.bss);
        build/us.v10/asm/core1/bkmemops64.s.o(.bss);
        build/us.v10/src/core1/overlay.c.o(.bss);
        build/us.v10/src/core1/depthbuffer.c.o(.bss);
        build/us.v10/src/core1/code_15B30.c.o(.bss);
        build/us.v10/src/core1/memory.c.o(.bss);
        build/us.v10/src/core1/eeprom.c.o(.bss);
        build/us.v10/src/core1/ucode.c.o(.bss);
        build/us.v10/src/core1/lookup.c.o(.bss);
        build/us.v10/src/core1/ml.c.o(.bss);
        build/us.v10/src/core1/musicplayer.c.o(.bss);
        build/us.v10/src/core1/stub_1D590.c.o(.bss);
        build/us.v10/asm/core1/bkgetsr.s.o(.bss);
        build/us.v10/src/core1/code_1D5D0.c.o(.bss);
        build/us.v10/src/core1/sns.c.o(.bss);
        build/us.v10/src/core1/glcrc.c.o(.bss);
        build/us.v10/asm/core1/code_1E820.s.o(.bss);
        build/us.v10/src/core1/n_audio/n_sl.c.o(.bss);
        build/us.v10/src/core1/n_audio/n_synthesizer.c.o(.bss);
        build/us.v10/src/core1/n_audio/n_synaddplayer.c.o(.bss);
        build/us.v10/src/core1/n_audio/n_synallocvoice.c.o(.bss);
        build/us.v10/src/core1/n_audio/n_synsetvol.c.o(.bss);
        build/us.v10/src/core1/n_audio/n_synstartvoice.c.o(.bss);
        build/us.v10/src/core1/n_audio/n_synsetpan.c.o(.bss);
        build/us.v10/src/core1/n_audio/n_synsetpitch.c.o(.bss);
        build/us.v10/src/core1/n_audio/n_synsetfxmix.c.o(.bss);
        build/us.v10/src/core1/n_audio/n_synstopvoice.c.o(.bss);
        build/us.v10/src/core1/n_audio/n_synfreevoice.c.o(.bss);
        build/us.v10/src/core1/n_audio/n_csplayer.c.o(.bss);
        build/us.v10/src/core1/n_audio/n_csq.c.o(.bss);
        build/us.v10/src/core1/ultra/audio/code_219D0.c.o(.bss);
        build/us.v10/src/core1/n_audio/code_21A80.c.o(.bss);
        build/us.v10/src/core1/ultra/audio/code_21AF0.c.o(.bss);
        build/us.v10/src/core1/n_audio/code_21B50.c.o(.bss);
        build/us.v10/src/core1/n_audio/n_syndelete.c.o(.bss);
        build/us.v10/src/core1/n_audio/n_synallocfx.c.o(.bss);
        build/us.v10/src/core1/n_audio/n_reverb.c.o(.bss);
        build/us.v10/src/core1/n_audio/n_auxbus.c.o(.bss);
        build/us.v10/src/core1/n_audio/n_drvrNew.c.o(.bss);
        build/us.v10/src/core1/n_audio/n_save.c.o(.bss);
        build/us.v10/src/core1/n_audio/n_envresample.c.o(.bss);
        build/us.v10/src/core1/n_audio/n_env.c.o(.bss);
        build/us.v10/src/core1/n_audio/n_seqplayer.c.o(.bss);
        build/us.v10/src/core1/n_audio/n_synstartvoiceparam.c.o(.bss);
        build/us.v10/src/core1/n_audio/n_mainbus.c.o(.bss);
        build/us.v10/src/core1/n_audio/n_load.c.o(.bss);
        build/us.v10/src/core1/n_audio/n_adpcm.c.o(.bss);
        build/us.v10/src/core1/n_audio/n_resample.c.o(.bss);
        build/us.v10/src/core1/n_audio/n_seq.c.o(.bss);
        build/us.v10/src/core1/n_audio/n_synsetpriority.c.o(.bss);
        build/us.v10/asm/data/core1/n_aspMain.s.o(.bss);
        build/us.v10/asm/data/core1/gSPF3DEX_fifo.s.o(.bss);
        build/us.v10/asm/data/core1/gSPL3DEX_fifo.s.o(.bss);
        build/us.v10/libultra_rom.a:initialize.o(.bss);
        build/us.v10/libultra_rom.a:pimgr.o(.bss);
        build/us.v10/libultra_rom.a:sptask.o(.bss);
        build/us.v10/libultra_rom.a:seteventmesg.o(.bss);
        build/us.v10/libultra_rom.a:vimgr.o(.bss);
        build/us.v10/libultra_rom.a:rotate.o(.bss);
        build/us.v10/libultra_rom.a:controller.o(.bss);
        build/us.v10/libultra_rom.a:motor.o(.bss);
        build/us.v10/libultra_rom.a:cartrominit.o(.bss);
        build/us.v10/libultra_rom.a:leodiskinit.o(.bss);
        build/us.v10/libultra_rom.a:piacs.o(.bss);
        build/us.v10/libultra_rom.a:timerintr.o(.bss);
        build/us.v10/libultra_rom.a:siacs.o(.bss);
        build/us.v10/libultra_rom.a:pfsisplug.o(.bss);
        build/us.v10/libultra_rom.a:conteepread.o(.bss);
        build/us.v10/libultra_rom.a:kdebugserver.o(.bss);
        build/us.v10/libultra_rom.a:leointerrupt.o(.bss);
        . = ALIGN(., 16);
        core1_BSS_END = .;
        core1_BSS_SIZE = ABSOLUTE(core1_BSS_END - core1_BSS_START);
    }
    __romPos += SIZEOF(.core1);
    __romPos = ALIGN(__romPos, 16);
    . = ALIGN(., 16);
    core1_ROM_END = __romPos;
    core1_VRAM_END = .;

    core2_ROM_START = __romPos;
    core2_VRAM = ADDR(.core2);
    .core2 core1_VRAM_END : AT(core2_ROM_START) SUBALIGN(16)
    {
        FILL(0x00000000);
        core2_TEXT_START = .;
        build/us.v10/src/core2/anctrl.c.o(.text);
        build/us.v10/src/core2/anim/sprite.c.o(.text);
        build/us.v10/src/core2/animcache.c.o(.text);
        build/us.v10/src/core2/code_1550.c.o(.text);
        build/us.v10/src/core2/anseq.c.o(.text);
        build/us.v10/src/core2/code_2240.c.o(.text);
        build/us.v10/src/core2/ba/anim.c.o(.text);
        build/us.v10/src/core2/snackerctl.c.o(.text);
        build/us.v10/src/core2/playerutils.c.o(.text);
        build/us.v10/src/core2/ba/marker.c.o(.text);
        build/us.v10/src/core2/code_6B30.c.o(.text);
        build/us.v10/src/core2/ba/carriedobj.c.o(.text);
        build/us.v10/src/core2/code_7060.c.o(.text);
        build/us.v10/src/core2/ba/flap.c.o(.text);
        build/us.v10/src/core2/code_90E0.c.o(.text);
        build/us.v10/src/core2/code_9290.c.o(.text);
        build/us.v10/src/core2/code_9450.c.o(.text);
        build/us.v10/src/core2/babuzz.c.o(.text);
        build/us.v10/src/core2/code_9BD0.c.o(.text);
        build/us.v10/src/core2/code_A600.c.o(.text);
        build/us.v10/src/core2/statetimer.c.o(.text);
        build/us.v10/src/core2/code_A960.c.o(.text);
        build/us.v10/src/core2/ba/model.c.o(.text);
        build/us.v10/src/core2/ba/drone.c.o(.text);
        build/us.v10/src/core2/code_B850.c.o(.text);
        build/us.v10/src/core2/eggshatter.c.o(.text);
        build/us.v10/src/core2/baeyes.c.o(.text);
        build/us.v10/src/core2/ba/falldamage.c.o(.text);
        build/us.v10/src/core2/baflag.c.o(.text);
        build/us.v10/src/core2/code_C4B0.c.o(.text);
        build/us.v10/src/core2/ba/carry.c.o(.text);
        build/us.v10/src/core2/code_D9B0.c.o(.text);
        build/us.v10/src/core2/bainput.c.o(.text);
        build/us.v10/src/core2/bakey.c.o(.text);
        build/us.v10/src/core2/abilityprogress.c.o(.text);
        build/us.v10/src/core2/bsmethods.c.o(.text);
        build/us.v10/src/core2/babounds.c.o(.text);
        build/us.v10/src/core2/code_EF50.c.o(.text);
        build/us.v10/src/core2/ba/physics.c.o(.text);
        build/us.v10/src/core2/ba/iFrame.c.o(.text);
        build/us.v10/src/core2/pitch.c.o(.text);
        build/us.v10/src/core2/code_11040.c.o(.text);
        build/us.v10/src/core2/climb.c.o(.text);
        build/us.v10/src/core2/playerposition.c.o(.text);
        build/us.v10/src/core2/playermodel.c.o(.text);
        build/us.v10/src/core2/code_117D0.c.o(.text);
        build/us.v10/src/core2/balookat.c.o(.text);
        build/us.v10/src/core2/roll.c.o(.text);
        build/us.v10/src/core2/yaw.c.o(.text);
        build/us.v10/src/core2/code_12360.c.o(.text);
        build/us.v10/src/core2/basfx.c.o(.text);
        build/us.v10/src/core2/code_12F30.c.o(.text);
        build/us.v10/src/core2/bsList.c.o(.text);
        build/us.v10/src/core2/code_13780.c.o(.text);
        build/us.v10/src/core2/bsStoredState.c.o(.text);
        build/us.v10/src/core2/code_13A00.c.o(.text);
        build/us.v10/src/core2/bastick.c.o(.text);
        build/us.v10/src/core2/code_14420.c.o(.text);
        build/us.v10/src/core2/code_15F20.c.o(.text);
        build/us.v10/src/core2/hazards.c.o(.text);
        build/us.v10/src/core2/modelappendages.c.o(.text);
        build/us.v10/src/core2/batimer.c.o(.text);
        build/us.v10/src/core2/bs/ant.c.o(.text);
        build/us.v10/src/core2/bs/bBarge.c.o(.text);
        build/us.v10/src/core2/bs/bbuster.c.o(.text);
        build/us.v10/src/core2/bs/bee.c.o(.text);
        build/us.v10/src/core2/bs/beeFly.c.o(.text);
        build/us.v10/src/core2/bs/beeMain.c.o(.text);
        build/us.v10/src/core2/bs/bEggAss.c.o(.text);
        build/us.v10/src/core2/bs/bEggHead.c.o(.text);
        build/us.v10/src/core2/bs/bFlap.c.o(.text);
        build/us.v10/src/core2/bs/bFlip.c.o(.text);
        build/us.v10/src/core2/bs/bFly.c.o(.text);
        build/us.v10/src/core2/bs/bLongLeg.c.o(.text);
        build/us.v10/src/core2/bs/bPeck.c.o(.text);
        build/us.v10/src/core2/bs/bShock.c.o(.text);
        build/us.v10/src/core2/bs/bSwim.c.o(.text);
        build/us.v10/src/core2/bs/bTrot.c.o(.text);
        build/us.v10/src/core2/bs/bWhirl.c.o(.text);
        build/us.v10/src/core2/bs/carry.c.o(.text);
        build/us.v10/src/core2/bs/claw.c.o(.text);
        build/us.v10/src/core2/bs/climb.c.o(.text);
        build/us.v10/src/core2/bs/croc.c.o(.text);
        build/us.v10/src/core2/bs/crouch.c.o(.text);
        build/us.v10/src/core2/bs/die.c.o(.text);
        build/us.v10/src/core2/bs/drone.c.o(.text);
        build/us.v10/src/core2/bs/droneenter.c.o(.text);
        build/us.v10/src/core2/bs/dronegoto.c.o(.text);
        build/us.v10/src/core2/bs/dronelook.c.o(.text);
        build/us.v10/src/core2/bs/dronevanish.c.o(.text);
        build/us.v10/src/core2/bs/dronexform.c.o(.text);
        build/us.v10/src/core2/bs/jig.c.o(.text);
        build/us.v10/src/core2/bs/jump.c.o(.text);
        build/us.v10/src/core2/bs/ow.c.o(.text);
        build/us.v10/src/core2/bs/pumpkin.c.o(.text);
        build/us.v10/src/core2/bs/rebound.c.o(.text);
        build/us.v10/src/core2/bs/rest.c.o(.text);
        build/us.v10/src/core2/bs/sled.c.o(.text);
        build/us.v10/src/core2/bs/slide.c.o(.text);
        build/us.v10/src/core2/bs/splat.c.o(.text);
        build/us.v10/src/core2/bs/stand.c.o(.text);
        build/us.v10/src/core2/bs/swim.c.o(.text);
        build/us.v10/src/core2/bs/surf.c.o(.text);
        build/us.v10/src/core2/bs/talk.c.o(.text);
        build/us.v10/src/core2/bs/timeout.c.o(.text);
        build/us.v10/src/core2/bs/throw.c.o(.text);
        build/us.v10/src/core2/bs/turn.c.o(.text);
        build/us.v10/src/core2/bs/twirl.c.o(.text);
        build/us.v10/src/core2/bs/walk.c.o(.text);
        build/us.v10/src/core2/bs/walrus.c.o(.text);
        build/us.v10/src/core2/bs/washy.c.o(.text);
        build/us.v10/src/core2/nc/cameranodelist.c.o(.text);
        build/us.v10/src/core2/code_33250.c.o(.text);
        build/us.v10/src/core2/code_33310.c.o(.text);
        build/us.v10/src/core2/code_336F0.c.o(.text);
        build/us.v10/src/core2/code_33AB0.c.o(.text);
        build/us.v10/src/core2/code_33C30.c.o(.text);
        build/us.v10/src/core2/nc/staticCamera.c.o(.text);
        build/us.v10/src/core2/code_33F90.c.o(.text);
        build/us.v10/src/core2/code_34310.c.o(.text);
        build/us.v10/src/core2/code_34790.c.o(.text);
        build/us.v10/src/core2/code_35520.c.o(.text);
        build/us.v10/src/core2/nc/dynamicCamera.c.o(.text);
        build/us.v10/src/core2/code_379B0.c.o(.text);
        build/us.v10/src/core2/nc/randomCamera.c.o(.text);
        build/us.v10/src/core2/code_37E50.c.o(.text);
        build/us.v10/src/core2/nc/dynamicCam10.c.o(.text);
        build/us.v10/src/core2/nc/ba/die.c.o(.text);
        build/us.v10/src/core2/nc/dynamicCam5.c.o(.text);
        build/us.v10/src/core2/nc/dynamicCam11.c.o(.text);
        build/us.v10/src/core2/nc/dynamicCam8.c.o(.text);
        build/us.v10/src/core2/nc/ba/fly.c.o(.text);
        build/us.v10/src/core2/nc/dynamicCamC.c.o(.text);
        build/us.v10/src/core2/code_F8EAF0.c.o(.text);
        build/us.v10/src/core2/nc/dynamicCamB.c.o(.text);
        build/us.v10/src/core2/nc/dynamicCam13.c.o(.text);
        build/us.v10/src/core2/nc/dynamicCam9.c.o(.text);
        build/us.v10/src/core2/nc/dynamicCam12.c.o(.text);
        build/us.v10/src/core2/nc/dynamicCam1.c.o(.text);
        build/us.v10/src/core2/nc/dynamicCam3.c.o(.text);
        build/us.v10/src/core2/nc/dynamicCamA.c.o(.text);
        build/us.v10/src/core2/code_3B2C0.c.o(.text);
        build/us.v10/src/core2/nc/dynamicCamF.c.o(.text);
        build/us.v10/src/core2/nc/ba/1p.c.o(.text);
        build/us.v10/src/core2/spawnqueue.c.o(.text);
        build/us.v10/src/core2/ch/gameSelect.c.o(.text);
        build/us.v10/src/core2/fx/shoesparkle.c.o(.text);
        build/us.v10/src/core2/ch/explosionripple.c.o(.text);
        build/us.v10/src/core2/ch/bubble.c.o(.text);
        build/us.v10/src/core2/ch/bigbutt.c.o(.text);
        build/us.v10/src/core2/code_400F0.c.o(.text);
        build/us.v10/src/core2/ch/jiggy.c.o(.text);
        build/us.v10/src/core2/ch/jigsawdance.c.o(.text);
        build/us.v10/src/core2/code_41460.c.o(.text);
        build/us.v10/src/core2/code_41F30.c.o(.text);
        build/us.v10/src/core2/code_41FB0.c.o(.text);
        build/us.v10/src/core2/ch/musicnote.c.o(.text);
        build/us.v10/src/core2/code_42CB0.c.o(.text);
        build/us.v10/src/core2/code_43250.c.o(.text);
        build/us.v10/src/core2/ch/trainers.c.o(.text);
        build/us.v10/src/core2/code_43800.c.o(.text);
        build/us.v10/src/core2/code_43A40.c.o(.text);
        build/us.v10/src/core2/mapspecificflags.c.o(.text);
        build/us.v10/src/core2/ch/crab.c.o(.text);
        build/us.v10/src/core2/code_45310.c.o(.text);
        build/us.v10/src/core2/ch/code_468E0.c.o(.text);
        build/us.v10/src/core2/ch/jinjo.c.o(.text);
        build/us.v10/src/core2/ch/beehive.c.o(.text);
        build/us.v10/src/core2/ch/beeswarm.c.o(.text);
        build/us.v10/src/core2/ch/soundsource.c.o(.text);
        build/us.v10/src/core2/ch/shrapnel.c.o(.text);
        build/us.v10/src/core2/ch/gloop.c.o(.text);
        build/us.v10/src/core2/ch/mumbo.c.o(.text);
        build/us.v10/src/core2/mumbosign.c.o(.text);
        build/us.v10/src/core2/code_4BE10.c.o(.text);
        build/us.v10/src/core2/code_4C020.c.o(.text);
        build/us.v10/src/core2/ch/wadingboots.c.o(.text);
        build/us.v10/src/core2/ch/badShad.c.o(.text);
        build/us.v10/src/core2/code_50490.c.o(.text);
        build/us.v10/src/core2/ch/climbBase.c.o(.text);
        build/us.v10/src/core2/levelcollectible.c.o(.text);
        build/us.v10/src/core2/ch/piranhaWaterParticles.c.o(.text);
        build/us.v10/src/core2/code_51950.c.o(.text);
        build/us.v10/src/core2/ch/collectible.c.o(.text);
        build/us.v10/src/core2/ch/mole.c.o(.text);
        build/us.v10/src/core2/ch/molehill.c.o(.text);
        build/us.v10/src/core2/code_53A10.c.o(.text);
        build/us.v10/src/core2/code_53C10.c.o(.text);
        build/us.v10/src/core2/code_54D50.c.o(.text);
        build/us.v10/src/core2/code_55180.c.o(.text);
        build/us.v10/src/core2/gc/gameoversign.c.o(.text);
        build/us.v10/src/core2/gc/theendsign.c.o(.text);
        build/us.v10/src/core2/gc/banjokazooiesign.c.o(.text);
        build/us.v10/src/core2/ch/overlaycopyright.c.o(.text);
        build/us.v10/src/core2/ch/overlaypressstart.c.o(.text);
        build/us.v10/src/core2/ch/overlaynocontroller.c.o(.text);
        build/us.v10/src/core2/ch/bottlesbonus.c.o(.text);
        build/us.v10/src/core2/ch/mumboshandwithpicture.c.o(.text);
        build/us.v10/src/core2/code_581D0.c.o(.text);
        build/us.v10/src/core2/ch/bottlesbonuscursor.c.o(.text);
        build/us.v10/src/core2/code_59780.c.o(.text);
        build/us.v10/src/core2/code_599E0.c.o(.text);
        build/us.v10/src/core2/ch/mumbotoken.c.o(.text);
        build/us.v10/src/core2/ch/snacker.c.o(.text);
        build/us.v10/src/core2/ch/snowman.c.o(.text);
        build/us.v10/src/core2/ch/snowball.c.o(.text);
        build/us.v10/src/core2/ch/snowmanhat.c.o(.text);
        build/us.v10/src/core2/mapsavestate.c.o(.text);
        build/us.v10/src/core2/code_5C240.c.o(.text);
        build/us.v10/src/core2/code_5C870.c.o(.text);
        build/us.v10/src/core2/code_5DBC0.c.o(.text);
        build/us.v10/src/core2/code_5FB00.c.o(.text);
        build/us.v10/src/core2/code_5FD80.c.o(.text);
        build/us.v10/src/core2/code_5FD90.c.o(.text);
        build/us.v10/src/core2/code_62FD0.c.o(.text);
        build/us.v10/src/core2/code_630D0.c.o(.text);
        build/us.v10/src/core2/code_63410.c.o(.text);
        build/us.v10/src/core2/code_63690.c.o(.text);
        build/us.v10/src/core2/code_637D0.c.o(.text);
        build/us.v10/src/core2/code_654C0.c.o(.text);
        build/us.v10/src/core2/code_66490.c.o(.text);
        build/us.v10/src/core2/vla.c.o(.text);
        build/us.v10/src/core2/fla.c.o(.text);
        build/us.v10/src/core2/code_66D90.c.o(.text);
        build/us.v10/src/core2/code_66FB0.c.o(.text);
        build/us.v10/src/core2/gc/bound.c.o(.text);
        build/us.v10/src/core2/dustemitter.c.o(.text);
        build/us.v10/src/core2/particle.c.o(.text);
        build/us.v10/src/core2/particleemittermanager.c.o(.text);
        build/us.v10/src/core2/code_6A4B0.c.o(.text);
        build/us.v10/src/core2/code_6AEF0.c.o(.text);
        build/us.v10/src/core2/code_6B030.c.o(.text);
        build/us.v10/src/core2/fx/ripple.c.o(.text);
        build/us.v10/src/core2/fx/sparkle.c.o(.text);
        build/us.v10/src/core2/code_6CD20.c.o(.text);
        build/us.v10/src/core2/code_6CEC0.c.o(.text);
        build/us.v10/src/core2/code_6D030.c.o(.text);
        build/us.v10/src/core2/code_6D270.c.o(.text);
        build/us.v10/src/core2/code_6D490.c.o(.text);
        build/us.v10/src/core2/print.c.o(.text);
        build/us.v10/src/core2/code_70C30.c.o(.text);
        build/us.v10/src/core2/code_70F20.c.o(.text);
        build/us.v10/src/core2/code_71820.c.o(.text);
        build/us.v10/src/core2/code_72060.c.o(.text);
        build/us.v10/src/core2/code_72B10.c.o(.text);
        build/us.v10/src/core2/code_73640.c.o(.text);
        build/us.v10/src/core2/code_74090.c.o(.text);
        build/us.v10/src/core2/code_74290.c.o(.text);
        build/us.v10/src/core2/code_74420.c.o(.text);
        build/us.v10/src/core2/code_74910.c.o(.text);
        build/us.v10/src/core2/code_74ED0.c.o(.text);
        build/us.v10/src/core2/code_75480.c.o(.text);
        build/us.v10/src/core2/code_75930.c.o(.text);
        build/us.v10/src/core2/code_75E90.c.o(.text);
        build/us.v10/src/core2/fx/common1score.c.o(.text);
        build/us.v10/src/core2/fx/common2score.c.o(.text);
        build/us.v10/src/core2/fx/honeycarrierscore.c.o(.text);
        build/us.v10/src/core2/code_77E50.c.o(.text);
        build/us.v10/src/core2/fx/jinjoscore.c.o(.text);
        build/us.v10/src/core2/fx/lifescore.c.o(.text);
        build/us.v10/src/core2/fx/common3score.c.o(.text);
        build/us.v10/src/core2/fx/healthscore.c.o(.text);
        build/us.v10/src/core2/fx/airscore.c.o(.text);
        build/us.v10/src/core2/gccube.c.o(.text);
        build/us.v10/src/core2/mapModel.c.o(.text);
        build/us.v10/src/core2/propModelList.c.o(.text);
        build/us.v10/src/core2/gc/section.c.o(.text);
        build/us.v10/src/core2/gc/sky.c.o(.text);
        build/us.v10/src/core2/gc/transition.c.o(.text);
        build/us.v10/src/core2/code_851D0.c.o(.text);
        build/us.v10/src/core2/code_857B0.c.o(.text);
        build/us.v10/src/core2/code_85800.c.o(.text);
        build/us.v10/src/core2/gc/dialog.c.o(.text);
        build/us.v10/src/core2/gc/pauseMenu.c.o(.text);
        build/us.v10/src/core2/code_8DC20.c.o(.text);
        build/us.v10/src/core2/gc/zoombox.c.o(.text);
        build/us.v10/src/core2/code_91E10.c.o(.text);
        build/us.v10/src/core2/minigame.c.o(.text);
        build/us.v10/src/core2/gc/parade.c.o(.text);
        build/us.v10/src/core2/code_94620.c.o(.text);
        build/us.v10/src/core2/code_94780.c.o(.text);
        build/us.v10/src/core2/code_94A20.c.o(.text);
        build/us.v10/src/core2/code_956B0.c.o(.text);
        build/us.v10/src/core2/code_98CB0.c.o(.text);
        build/us.v10/src/core2/quizquestionaskedbitfield.c.o(.text);
        build/us.v10/src/core2/code_999A0.c.o(.text);
        build/us.v10/src/core2/jiggyscore.c.o(.text);
        build/us.v10/src/core2/honeycombscore.c.o(.text);
        build/us.v10/src/core2/mumboscore.c.o(.text);
        build/us.v10/src/core2/code_9A740.c.o(.text);
        build/us.v10/src/core2/code_9A9D0.c.o(.text);
        build/us.v10/src/core2/levelspecificflags.c.o(.text);
        build/us.v10/src/core2/code_9B180.c.o(.text);
        build/us.v10/src/core2/code_9B650.c.o(.text);
        build/us.v10/src/core2/code_9B990.c.o(.text);
        build/us.v10/src/core2/code_9C170.c.o(.text);
        build/us.v10/src/core2/code_9D640.c.o(.text);
        build/us.v10/src/core2/code_9D760.c.o(.text);
        build/us.v10/src/core2/timedfuncqueue.c.o(.text);
        build/us.v10/src/core2/code_9E370.c.o(.text);
        build/us.v10/src/core2/code_A4D00.c.o(.text);
        build/us.v10/src/core2/code_A5BC0.c.o(.text);
        build/us.v10/src/core2/code_ABC00.c.o(.text);
        build/us.v10/src/core2/gclights.c.o(.text);
        build/us.v10/src/core2/code_AD110.c.o(.text);
        build/us.v10/src/core2/gsworld.c.o(.text);
        build/us.v10/src/core2/code_AE290.c.o(.text);
        build/us.v10/src/core2/skeletalanim.c.o(.text);
        build/us.v10/src/core2/code_AEDA0.c.o(.text);
        build/us.v10/src/core2/modelRender.c.o(.text);
        build/us.v10/src/core2/code_B3580.c.o(.text);
        build/us.v10/src/core2/animationfile.c.o(.text);
        build/us.v10/src/core2/code_B3A80.c.o(.text);
        build/us.v10/src/core2/code_B5040.c.o(.text);
        build/us.v10/src/core2/code_B5E00.c.o(.text);
        build/us.v10/src/core2/code_B62B0.c.o(.text);
        build/us.v10/src/core2/code_B6640.c.o(.text);
        build/us.v10/src/core2/string.c.o(.text);
        build/us.v10/src/core2/code_B6C60.c.o(.text);
        build/us.v10/src/core2/time.c.o(.text);
        build/us.v10/src/core2/commonParticle.c.o(.text);
        build/us.v10/src/core2/coords.c.o(.text);
        build/us.v10/src/core2/code_B7F40.c.o(.text);
        build/us.v10/src/core2/code_B8020.c.o(.text);
        build/us.v10/src/core2/ultra/debug/assert.c.o(.text);
        build/us.v10/src/core2/code_B8080.c.o(.text);
        build/us.v10/src/core2/code_B8860.c.o(.text);
        build/us.v10/src/core2/code_B9090.c.o(.text);
        build/us.v10/src/core2/code_B9770.c.o(.text);
        build/us.v10/src/core2/code_BD100.c.o(.text);
        build/us.v10/src/core2/code_BDCC0.c.o(.text);
        build/us.v10/src/core2/code_BE2C0.c.o(.text);
        build/us.v10/src/core2/code_BEF20.c.o(.text);
        build/us.v10/src/core2/code_C0B80.c.o(.text);
        build/us.v10/src/core2/code_C0CF0.c.o(.text);
        build/us.v10/src/core2/code_C0E60.c.o(.text);
        build/us.v10/src/core2/animtexturecache.c.o(.text);
        build/us.v10/src/core2/demo.c.o(.text);
        build/us.v10/src/core2/code_C31A0.c.o(.text);
        build/us.v10/src/core2/rand.c.o(.text);
        build/us.v10/src/core2/code_C3A40.c.o(.text);
        build/us.v10/src/core2/file.c.o(.text);
        build/us.v10/src/core2/code_C4320.c.o(.text);
        build/us.v10/src/core2/code_C4F40.c.o(.text);
        build/us.v10/src/core2/code_C5440.c.o(.text);
        build/us.v10/src/core2/code_C5AF0.c.o(.text);
        build/us.v10/src/core2/code_C5CC0.c.o(.text);
        build/us.v10/src/core2/code_C5F00.c.o(.text);
        build/us.v10/src/core2/code_C61C0.c.o(.text);
        build/us.v10/src/core2/code_C62B0.c.o(.text);
        build/us.v10/src/core2/code_C76D0.c.o(.text);
        build/us.v10/src/core2/code_C7CC0.c.o(.text);
        build/us.v10/src/core2/code_C8230.c.o(.text);
        build/us.v10/src/core2/code_C8360.c.o(.text);
        build/us.v10/src/core2/code_C8490.c.o(.text);
        build/us.v10/src/core2/code_C8760.c.o(.text);
        build/us.v10/src/core2/code_C89C0.c.o(.text);
        build/us.v10/src/core2/lensflare.c.o(.text);
        build/us.v10/src/core2/code_C9E70.c.o(.text);
        build/us.v10/src/core2/code_C9F00.c.o(.text);
        build/us.v10/src/core2/code_CB050.c.o(.text);
        build/us.v10/src/core2/code_CB610.c.o(.text);
        build/us.v10/src/core2/commonParticleTypeMap.c.o(.text);
        build/us.v10/src/core2/code_CBBF0.c.o(.text);
        build/us.v10/src/core2/code_CBD10.c.o(.text);
        build/us.v10/src/core2/code_CC1E0.c.o(.text);
        build/us.v10/src/core2/code_CD0A0.c.o(.text);
        build/us.v10/src/core2/code_CD3F0.c.o(.text);
        build/us.v10/src/core2/code_CD6E0.c.o(.text);
        build/us.v10/src/core2/code_CECD0.c.o(.text);
        build/us.v10/src/core2/code_CF090.c.o(.text);
        build/us.v10/src/core2/progressDialog.c.o(.text);
        build/us.v10/src/core2/code_CF5F0.c.o(.text);
        build/us.v10/src/core2/ch/clankerwhipcrack.c.o(.text);
        build/us.v10/src/core2/ch/grillechompa.c.o(.text);
        build/us.v10/src/core2/ch/clucker.c.o(.text);
        build/us.v10/src/core2/ch/scarabbeetle.c.o(.text);
        build/us.v10/src/core2/code_D2180.c.o(.text);
        build/us.v10/src/core2/ch/firefx.c.o(.text);
        build/us.v10/src/core2/ch/drips.c.o(.text);
        build/us.v10/src/core2/ch/icecube.c.o(.text);
        build/us.v10/src/core2/ch/ghost.c.o(.text);
        build/us.v10/src/core2/ch/flotsam.c.o(.text);
        build/us.v10/src/core2/ch/skeleton.c.o(.text);
        build/us.v10/src/core2/ch/seamangrublin.c.o(.text);
        build/us.v10/src/core2/ch/mummum.c.o(.text);
        build/us.v10/src/core2/ch/chumpfish.c.o(.text);
        build/us.v10/src/core2/ch/termite.c.o(.text);
        build/us.v10/src/core2/ch/gravestone.c.o(.text);
        build/us.v10/src/core2/ch/bat.c.o(.text);
        build/us.v10/src/core2/ch/whipcrack.c.o(.text);
        build/us.v10/src/core2/ch/betavent.c.o(.text);
        build/us.v10/src/core2/code_DA760.c.o(.text);
        build/us.v10/src/core2/code_DAAA0.c.o(.text);
        build/us.v10/src/core2/code_DB010.c.o(.text);
        build/us.v10/src/core2/code_DC4B0.c.o(.text);
        . = ALIGN(., 16);
        core2_TEXT_END = .;
        core2_TEXT_SIZE = ABSOLUTE(core2_TEXT_END - core2_TEXT_START);
        core2_DATA_START = .;
        build/us.v10/src/core2/anctrl.c.o(.data);
        build/us.v10/src/core2/anim/sprite.c.o(.data);
        build/us.v10/src/core2/animcache.c.o(.data);
        build/us.v10/bin/core2/data_DC600.bin.o(.data);
        build/us.v10/src/core2/code_1550.c.o(.data);
        build/us.v10/src/core2/anseq.c.o(.data);
        build/us.v10/src/core2/code_2240.c.o(.data);
        build/us.v10/src/core2/ba/anim.c.o(.data);
        build/us.v10/src/core2/snackerctl.c.o(.data);
        build/us.v10/src/core2/playerutils.c.o(.data);
        build/us.v10/src/core2/ba/marker.c.o(.data);
        build/us.v10/src/core2/code_6B30.c.o(.data);
        build/us.v10/src/core2/ba/carriedobj.c.o(.data);
        build/us.v10/src/core2/code_7060.c.o(.data);
        build/us.v10/src/core2/ba/flap.c.o(.data);
        build/us.v10/src/core2/code_90E0.c.o(.data);
        build/us.v10/src/core2/code_9290.c.o(.data);
        build/us.v10/src/core2/code_9450.c.o(.data);
        build/us.v10/src/core2/babuzz.c.o(.data);
        build/us.v10/src/core2/code_9BD0.c.o(.data);
        build/us.v10/src/core2/code_A600.c.o(.data);
        build/us.v10/src/core2/statetimer.c.o(.data);
        build/us.v10/src/core2/code_A960.c.o(.data);
        build/us.v10/src/core2/ba/model.c.o(.data);
        build/us.v10/src/core2/ba/drone.c.o(.data);
        build/us.v10/src/core2/code_B850.c.o(.data);
        build/us.v10/src/core2/eggshatter.c.o(.data);
        build/us.v10/src/core2/baeyes.c.o(.data);
        build/us.v10/src/core2/ba/falldamage.c.o(.data);
        build/us.v10/src/core2/baflag.c.o(.data);
        build/us.v10/src/core2/code_C4B0.c.o(.data);
        build/us.v10/src/core2/ba/carry.c.o(.data);
        build/us.v10/src/core2/code_D9B0.c.o(.data);
        build/us.v10/src/core2/bainput.c.o(.data);
        build/us.v10/src/core2/bakey.c.o(.data);
        build/us.v10/src/core2/abilityprogress.c.o(.data);
        build/us.v10/src/core2/bsmethods.c.o(.data);
        build/us.v10/src/core2/babounds.c.o(.data);
        build/us.v10/src/core2/code_EF50.c.o(.data);
        build/us.v10/src/core2/ba/physics.c.o(.data);
        build/us.v10/src/core2/ba/iFrame.c.o(.data);
        build/us.v10/src/core2/pitch.c.o(.data);
        build/us.v10/src/core2/code_11040.c.o(.data);
        build/us.v10/src/core2/climb.c.o(.data);
        build/us.v10/src/core2/playerposition.c.o(.data);
        build/us.v10/src/core2/playermodel.c.o(.data);
        build/us.v10/src/core2/code_117D0.c.o(.data);
        build/us.v10/src/core2/balookat.c.o(.data);
        build/us.v10/src/core2/roll.c.o(.data);
        build/us.v10/src/core2/yaw.c.o(.data);
        build/us.v10/src/core2/code_12360.c.o(.data);
        build/us.v10/src/core2/basfx.c.o(.data);
        build/us.v10/src/core2/code_12F30.c.o(.data);
        build/us.v10/src/core2/bsList.c.o(.data);
        build/us.v10/src/core2/code_13780.c.o(.data);
        build/us.v10/src/core2/bsStoredState.c.o(.data);
        build/us.v10/src/core2/code_13A00.c.o(.data);
        build/us.v10/src/core2/bastick.c.o(.data);
        build/us.v10/src/core2/code_14420.c.o(.data);
        build/us.v10/src/core2/code_15F20.c.o(.data);
        build/us.v10/src/core2/hazards.c.o(.data);
        build/us.v10/src/core2/modelappendages.c.o(.data);
        build/us.v10/src/core2/batimer.c.o(.data);
        build/us.v10/src/core2/bs/ant.c.o(.data);
        build/us.v10/src/core2/bs/bBarge.c.o(.data);
        build/us.v10/src/core2/bs/bbuster.c.o(.data);
        build/us.v10/src/core2/bs/bee.c.o(.data);
        build/us.v10/src/core2/bs/beeFly.c.o(.data);
        build/us.v10/src/core2/bs/beeMain.c.o(.data);
        build/us.v10/src/core2/bs/bEggAss.c.o(.data);
        build/us.v10/src/core2/bs/bEggHead.c.o(.data);
        build/us.v10/src/core2/bs/bFlap.c.o(.data);
        build/us.v10/src/core2/bs/bFlip.c.o(.data);
        build/us.v10/src/core2/bs/bFly.c.o(.data);
        build/us.v10/src/core2/bs/bLongLeg.c.o(.data);
        build/us.v10/src/core2/bs/bPeck.c.o(.data);
        build/us.v10/src/core2/bs/bShock.c.o(.data);
        build/us.v10/src/core2/bs/bSwim.c.o(.data);
        build/us.v10/bin/core2/data_DDAF0.bin.o(.data);
        build/us.v10/src/core2/bs/bTrot.c.o(.data);
        build/us.v10/src/core2/bs/bWhirl.c.o(.data);
        build/us.v10/src/core2/bs/carry.c.o(.data);
        build/us.v10/src/core2/bs/claw.c.o(.data);
        build/us.v10/src/core2/bs/climb.c.o(.data);
        build/us.v10/src/core2/bs/croc.c.o(.data);
        build/us.v10/src/core2/bs/crouch.c.o(.data);
        build/us.v10/src/core2/bs/die.c.o(.data);
        build/us.v10/src/core2/bs/drone.c.o(.data);
        build/us.v10/src/core2/bs/droneenter.c.o(.data);
        build/us.v10/src/core2/bs/dronegoto.c.o(.data);
        build/us.v10/src/core2/bs/dronelook.c.o(.data);
        build/us.v10/src/core2/bs/dronevanish.c.o(.data);
        build/us.v10/src/core2/bs/dronexform.c.o(.data);
        build/us.v10/src/core2/bs/jig.c.o(.data);
        build/us.v10/src/core2/bs/jump.c.o(.data);
        build/us.v10/src/core2/bs/ow.c.o(.data);
        build/us.v10/src/core2/bs/pumpkin.c.o(.data);
        build/us.v10/src/core2/bs/rebound.c.o(.data);
        build/us.v10/src/core2/bs/rest.c.o(.data);
        build/us.v10/src/core2/bs/sled.c.o(.data);
        build/us.v10/src/core2/bs/slide.c.o(.data);
        build/us.v10/src/core2/bs/splat.c.o(.data);
        build/us.v10/src/core2/bs/stand.c.o(.data);
        build/us.v10/src/core2/bs/swim.c.o(.data);
        build/us.v10/src/core2/bs/surf.c.o(.data);
        build/us.v10/src/core2/bs/talk.c.o(.data);
        build/us.v10/src/core2/bs/timeout.c.o(.data);
        build/us.v10/src/core2/bs/throw.c.o(.data);
        build/us.v10/src/core2/bs/turn.c.o(.data);
        build/us.v10/src/core2/bs/twirl.c.o(.data);
        build/us.v10/src/core2/bs/walk.c.o(.data);
        build/us.v10/src/core2/bs/walrus.c.o(.data);
        build/us.v10/src/core2/bs/washy.c.o(.data);
        build/us.v10/src/core2/nc/cameranodelist.c.o(.data);
        build/us.v10/src/core2/code_33250.c.o(.data);
        build/us.v10/src/core2/code_33310.c.o(.data);
        build/us.v10/src/core2/code_336F0.c.o(.data);
        build/us.v10/src/core2/code_33AB0.c.o(.data);
        build/us.v10/src/core2/code_33C30.c.o(.data);
        build/us.v10/src/core2/nc/staticCamera.c.o(.data);
        build/us.v10/src/core2/code_33F90.c.o(.data);
        build/us.v10/src/core2/code_34310.c.o(.data);
        build/us.v10/src/core2/code_34790.c.o(.data);
        build/us.v10/src/core2/code_35520.c.o(.data);
        build/us.v10/src/core2/nc/dynamicCamera.c.o(.data);
        build/us.v10/src/core2/code_379B0.c.o(.data);
        build/us.v10/src/core2/nc/randomCamera.c.o(.data);
        build/us.v10/src/core2/code_37E50.c.o(.data);
        build/us.v10/src/core2/nc/dynamicCam10.c.o(.data);
        build/us.v10/src/core2/nc/ba/die.c.o(.data);
        build/us.v10/src/core2/nc/dynamicCam5.c.o(.data);
        build/us.v10/src/core2/nc/dynamicCam11.c.o(.data);
        build/us.v10/src/core2/nc/dynamicCam8.c.o(.data);
        build/us.v10/src/core2/nc/ba/fly.c.o(.data);
        build/us.v10/src/core2/nc/dynamicCamC.c.o(.data);
        build/us.v10/src/core2/code_F8EAF0.c.o(.data);
        build/us.v10/src/core2/nc/dynamicCamB.c.o(.data);
        build/us.v10/src/core2/nc/dynamicCam13.c.o(.data);
        build/us.v10/src/core2/nc/dynamicCam9.c.o(.data);
        build/us.v10/src/core2/nc/dynamicCam12.c.o(.data);
        build/us.v10/src/core2/nc/dynamicCam1.c.o(.data);
        build/us.v10/src/core2/nc/dynamicCam3.c.o(.data);
        build/us.v10/src/core2/nc/dynamicCamA.c.o(.data);
        build/us.v10/src/core2/code_3B2C0.c.o(.data);
        build/us.v10/src/core2/nc/dynamicCamF.c.o(.data);
        build/us.v10/src/core2/nc/ba/1p.c.o(.data);
        build/us.v10/src/core2/spawnqueue.c.o(.data);
        build/us.v10/src/core2/ch/gameSelect.c.o(.data);
        build/us.v10/src/core2/fx/shoesparkle.c.o(.data);
        build/us.v10/src/core2/ch/explosionripple.c.o(.data);
        build/us.v10/src/core2/ch/bubble.c.o(.data);
        build/us.v10/src/core2/ch/bigbutt.c.o(.data);
        build/us.v10/src/core2/code_400F0.c.o(.data);
        build/us.v10/src/core2/ch/jiggy.c.o(.data);
        build/us.v10/src/core2/ch/jigsawdance.c.o(.data);
        build/us.v10/src/core2/code_41460.c.o(.data);
        build/us.v10/src/core2/code_41F30.c.o(.data);
        build/us.v10/src/core2/code_41FB0.c.o(.data);
        build/us.v10/src/core2/ch/musicnote.c.o(.data);
        build/us.v10/src/core2/code_42CB0.c.o(.data);
        build/us.v10/src/core2/code_43250.c.o(.data);
        build/us.v10/src/core2/ch/trainers.c.o(.data);
        build/us.v10/src/core2/code_43800.c.o(.data);
        build/us.v10/src/core2/code_43A40.c.o(.data);
        build/us.v10/src/core2/mapspecificflags.c.o(.data);
        build/us.v10/src/core2/ch/crab.c.o(.data);
        build/us.v10/src/core2/code_45310.c.o(.data);
        build/us.v10/src/core2/ch/code_468E0.c.o(.data);
        build/us.v10/src/core2/ch/jinjo.c.o(.data);
        build/us.v10/src/core2/ch/beehive.c.o(.data);
        build/us.v10/src/core2/ch/beeswarm.c.o(.data);
        build/us.v10/src/core2/ch/soundsource.c.o(.data);
        build/us.v10/src/core2/ch/shrapnel.c.o(.data);
        build/us.v10/src/core2/ch/gloop.c.o(.data);
        build/us.v10/src/core2/ch/mumbo.c.o(.data);
        build/us.v10/src/core2/mumbosign.c.o(.data);
        build/us.v10/src/core2/code_4BE10.c.o(.data);
        build/us.v10/src/core2/code_4C020.c.o(.data);
        build/us.v10/src/core2/ch/wadingboots.c.o(.data);
        build/us.v10/src/core2/ch/badShad.c.o(.data);
        build/us.v10/src/core2/code_50490.c.o(.data);
        build/us.v10/src/core2/ch/climbBase.c.o(.data);
        build/us.v10/src/core2/levelcollectible.c.o(.data);
        build/us.v10/src/core2/ch/piranhaWaterParticles.c.o(.data);
        build/us.v10/src/core2/code_51950.c.o(.data);
        build/us.v10/src/core2/ch/collectible.c.o(.data);
        build/us.v10/src/core2/ch/mole.c.o(.data);
        build/us.v10/src/core2/ch/molehill.c.o(.data);
        build/us.v10/src/core2/code_53A10.c.o(.data);
        build/us.v10/src/core2/code_53C10.c.o(.data);
        build/us.v10/src/core2/code_54D50.c.o(.data);
        build/us.v10/src/core2/code_55180.c.o(.data);
        build/us.v10/src/core2/gc/gameoversign.c.o(.data);
        build/us.v10/src/core2/gc/theendsign.c.o(.data);
        build/us.v10/src/core2/gc/banjokazooiesign.c.o(.data);
        build/us.v10/src/core2/ch/overlaycopyright.c.o(.data);
        build/us.v10/src/core2/ch/overlaypressstart.c.o(.data);
        build/us.v10/src/core2/ch/overlaynocontroller.c.o(.data);
        build/us.v10/src/core2/ch/bottlesbonus.c.o(.data);
        build/us.v10/src/core2/ch/mumboshandwithpicture.c.o(.data);
        build/us.v10/src/core2/code_581D0.c.o(.data);
        build/us.v10/src/core2/ch/bottlesbonuscursor.c.o(.data);
        build/us.v10/src/core2/code_59780.c.o(.data);
        build/us.v10/src/core2/code_599E0.c.o(.data);
        build/us.v10/src/core2/ch/mumbotoken.c.o(.data);
        build/us.v10/src/core2/ch/snacker.c.o(.data);
        build/us.v10/src/core2/ch/snowman.c.o(.data);
        build/us.v10/src/core2/ch/snowball.c.o(.data);
        build/us.v10/src/core2/ch/snowmanhat.c.o(.data);
        build/us.v10/src/core2/mapsavestate.c.o(.data);
        build/us.v10/src/core2/code_5C240.c.o(.data);
        build/us.v10/src/core2/code_5C870.c.o(.data);
        build/us.v10/src/core2/code_5DBC0.c.o(.data);
        build/us.v10/src/core2/code_5FB00.c.o(.data);
        build/us.v10/src/core2/code_5FD80.c.o(.data);
        build/us.v10/src/core2/code_5FD90.c.o(.data);
        build/us.v10/src/core2/code_62FD0.c.o(.data);
        build/us.v10/src/core2/code_630D0.c.o(.data);
        build/us.v10/src/core2/code_63410.c.o(.data);
        build/us.v10/src/core2/code_63690.c.o(.data);
        build/us.v10/src/core2/code_637D0.c.o(.data);
        build/us.v10/src/core2/code_654C0.c.o(.data);
        build/us.v10/src/core2/code_66490.c.o(.data);
        build/us.v10/src/core2/vla.c.o(.data);
        build/us.v10/src/core2/fla.c.o(.data);
        build/us.v10/src/core2/code_66D90.c.o(.data);
        build/us.v10/src/core2/code_66FB0.c.o(.data);
        build/us.v10/src/core2/gc/bound.c.o(.data);
        build/us.v10/src/core2/dustemitter.c.o(.data);
        build/us.v10/src/core2/particle.c.o(.data);
        build/us.v10/src/core2/particleemittermanager.c.o(.data);
        build/us.v10/src/core2/code_6A4B0.c.o(.data);
        build/us.v10/src/core2/code_6AEF0.c.o(.data);
        build/us.v10/src/core2/code_6B030.c.o(.data);
        build/us.v10/src/core2/fx/ripple.c.o(.data);
        build/us.v10/src/core2/fx/sparkle.c.o(.data);
        build/us.v10/src/core2/code_6CD20.c.o(.data);
        build/us.v10/src/core2/code_6CEC0.c.o(.data);
        build/us.v10/src/core2/code_6D030.c.o(.data);
        build/us.v10/src/core2/code_6D270.c.o(.data);
        build/us.v10/src/core2/code_6D490.c.o(.data);
        build/us.v10/src/core2/print.c.o(.data);
        build/us.v10/src/core2/code_70C30.c.o(.data);
        build/us.v10/src/core2/code_70F20.c.o(.data);
        build/us.v10/src/core2/code_71820.c.o(.data);
        build/us.v10/src/core2/code_72060.c.o(.data);
        build/us.v10/src/core2/code_72B10.c.o(.data);
        build/us.v10/src/core2/code_73640.c.o(.data);
        build/us.v10/src/core2/code_74090.c.o(.data);
        build/us.v10/src/core2/code_74290.c.o(.data);
        build/us.v10/src/core2/code_74420.c.o(.data);
        build/us.v10/src/core2/code_74910.c.o(.data);
        build/us.v10/src/core2/code_74ED0.c.o(.data);
        build/us.v10/src/core2/code_75480.c.o(.data);
        build/us.v10/src/core2/code_75930.c.o(.data);
        build/us.v10/src/core2/code_75E90.c.o(.data);
        build/us.v10/src/core2/fx/common1score.c.o(.data);
        build/us.v10/src/core2/fx/common2score.c.o(.data);
        build/us.v10/src/core2/fx/honeycarrierscore.c.o(.data);
        build/us.v10/src/core2/code_77E50.c.o(.data);
        build/us.v10/src/core2/fx/jinjoscore.c.o(.data);
        build/us.v10/src/core2/fx/lifescore.c.o(.data);
        build/us.v10/src/core2/fx/common3score.c.o(.data);
        build/us.v10/src/core2/fx/healthscore.c.o(.data);
        build/us.v10/src/core2/fx/airscore.c.o(.data);
        build/us.v10/src/core2/gccube.c.o(.data);
        build/us.v10/src/core2/mapModel.c.o(.data);
        build/us.v10/src/core2/propModelList.c.o(.data);
        build/us.v10/src/core2/gc/section.c.o(.data);
        build/us.v10/src/core2/gc/sky.c.o(.data);
        build/us.v10/src/core2/gc/transition.c.o(.data);
        build/us.v10/src/core2/code_851D0.c.o(.data);
        build/us.v10/src/core2/code_857B0.c.o(.data);
        build/us.v10/src/core2/code_85800.c.o(.data);
        build/us.v10/src/core2/gc/dialog.c.o(.data);
        build/us.v10/src/core2/gc/pauseMenu.c.o(.data);
        build/us.v10/src/core2/code_8DC20.c.o(.data);
        build/us.v10/src/core2/gc/zoombox.c.o(.data);
        build/us.v10/src/core2/code_91E10.c.o(.data);
        build/us.v10/src/core2/minigame.c.o(.data);
        build/us.v10/src/core2/gc/parade.c.o(.data);
        build/us.v10/src/core2/code_94620.c.o(.data);
        build/us.v10/src/core2/code_94780.c.o(.data);
        build/us.v10/src/core2/code_94A20.c.o(.data);
        build/us.v10/src/core2/code_956B0.c.o(.data);
        build/us.v10/src/core2/code_98CB0.c.o(.data);
        build/us.v10/src/core2/quizquestionaskedbitfield.c.o(.data);
        build/us.v10/src/core2/code_999A0.c.o(.data);
        build/us.v10/src/core2/jiggyscore.c.o(.data);
        build/us.v10/src/core2/honeycombscore.c.o(.data);
        build/us.v10/src/core2/mumboscore.c.o(.data);
        build/us.v10/src/core2/code_9A740.c.o(.data);
        build/us.v10/src/core2/code_9A9D0.c.o(.data);
        build/us.v10/src/core2/levelspecificflags.c.o(.data);
        build/us.v10/src/core2/code_9B180.c.o(.data);
        build/us.v10/src/core2/code_9B650.c.o(.data);
        build/us.v10/src/core2/code_9B990.c.o(.data);
        build/us.v10/src/core2/code_9C170.c.o(.data);
        build/us.v10/src/core2/code_9D640.c.o(.data);
        build/us.v10/src/core2/code_9D760.c.o(.data);
        build/us.v10/src/core2/timedfuncqueue.c.o(.data);
        build/us.v10/src/core2/code_9E370.c.o(.data);
        build/us.v10/src/core2/code_A4D00.c.o(.data);
        build/us.v10/src/core2/code_A5BC0.c.o(.data);
        build/us.v10/src/core2/code_A5BC0.c.o(.data);
        build/us.v10/src/core2/code_ABC00.c.o(.data);
        build/us.v10/src/core2/gclights.c.o(.data);
        build/us.v10/src/core2/code_AD110.c.o(.data);
        build/us.v10/src/core2/gsworld.c.o(.data);
        build/us.v10/src/core2/code_AE290.c.o(.data);
        build/us.v10/src/core2/skeletalanim.c.o(.data);
        build/us.v10/src/core2/code_AEDA0.c.o(.data);
        build/us.v10/src/core2/modelRender.c.o(.data);
        build/us.v10/src/core2/code_B3580.c.o(.data);
        build/us.v10/src/core2/animationfile.c.o(.data);
        build/us.v10/src/core2/code_B3A80.c.o(.data);
        build/us.v10/src/core2/code_B5040.c.o(.data);
        build/us.v10/src/core2/code_B5E00.c.o(.data);
        build/us.v10/src/core2/code_B62B0.c.o(.data);
        build/us.v10/src/core2/code_B6640.c.o(.data);
        build/us.v10/src/core2/string.c.o(.data);
        build/us.v10/src/core2/code_B6C60.c.o(.data);
        build/us.v10/src/core2/time.c.o(.data);
        build/us.v10/src/core2/commonParticle.c.o(.data);
        build/us.v10/src/core2/coords.c.o(.data);
        build/us.v10/src/core2/code_B7F40.c.o(.data);
        build/us.v10/src/core2/code_B8020.c.o(.data);
        build/us.v10/src/core2/ultra/debug/assert.c.o(.data);
        build/us.v10/src/core2/code_B8080.c.o(.data);
        build/us.v10/src/core2/code_B8860.c.o(.data);
        build/us.v10/src/core2/code_B9090.c.o(.data);
        build/us.v10/src/core2/code_B9770.c.o(.data);
        build/us.v10/src/core2/code_BD100.c.o(.data);
        build/us.v10/src/core2/code_BDCC0.c.o(.data);
        build/us.v10/src/core2/code_BE2C0.c.o(.data);
        build/us.v10/src/core2/code_BEF20.c.o(.data);
        build/us.v10/src/core2/code_C0B80.c.o(.data);
        build/us.v10/src/core2/code_C0CF0.c.o(.data);
        build/us.v10/src/core2/code_C0E60.c.o(.data);
        build/us.v10/src/core2/animtexturecache.c.o(.data);
        build/us.v10/bin/core2/data_EAF40.bin.o(.data);
        build/us.v10/src/core2/demo.c.o(.data);
        build/us.v10/src/core2/code_C31A0.c.o(.data);
        build/us.v10/src/core2/rand.c.o(.data);
        build/us.v10/src/core2/code_C3A40.c.o(.data);
        build/us.v10/src/core2/file.c.o(.data);
        build/us.v10/src/core2/code_C4320.c.o(.data);
        build/us.v10/src/core2/code_C4F40.c.o(.data);
        build/us.v10/src/core2/code_C5440.c.o(.data);
        build/us.v10/src/core2/code_C5AF0.c.o(.data);
        build/us.v10/src/core2/code_C5CC0.c.o(.data);
        build/us.v10/src/core2/code_C5F00.c.o(.data);
        build/us.v10/src/core2/code_C61C0.c.o(.data);
        build/us.v10/src/core2/code_C62B0.c.o(.data);
        build/us.v10/src/core2/code_C76D0.c.o(.data);
        build/us.v10/src/core2/code_C7CC0.c.o(.data);
        build/us.v10/src/core2/code_C8230.c.o(.data);
        build/us.v10/src/core2/code_C8360.c.o(.data);
        build/us.v10/src/core2/code_C8490.c.o(.data);
        build/us.v10/src/core2/code_C8760.c.o(.data);
        build/us.v10/src/core2/code_C89C0.c.o(.data);
        build/us.v10/src/core2/lensflare.c.o(.data);
        build/us.v10/src/core2/code_C9E70.c.o(.data);
        build/us.v10/src/core2/code_C9F00.c.o(.data);
        build/us.v10/src/core2/code_CB050.c.o(.data);
        build/us.v10/src/core2/code_CB610.c.o(.data);
        build/us.v10/src/core2/commonParticleTypeMap.c.o(.data);
        build/us.v10/src/core2/code_CBBF0.c.o(.data);
        build/us.v10/src/core2/code_CBD10.c.o(.data);
        build/us.v10/src/core2/code_CC1E0.c.o(.data);
        build/us.v10/src/core2/code_CD0A0.c.o(.data);
        build/us.v10/src/core2/code_CD3F0.c.o(.data);
        build/us.v10/src/core2/code_CD6E0.c.o(.data);
        build/us.v10/src/core2/code_CECD0.c.o(.data);
        build/us.v10/src/core2/code_CF090.c.o(.data);
        build/us.v10/src/core2/progressDialog.c.o(.data);
        build/us.v10/src/core2/code_CF5F0.c.o(.data);
        build/us.v10/src/core2/ch/clankerwhipcrack.c.o(.data);
        build/us.v10/src/core2/ch/grillechompa.c.o(.data);
        build/us.v10/src/core2/ch/clucker.c.o(.data);
        build/us.v10/src/core2/ch/scarabbeetle.c.o(.data);
        build/us.v10/src/core2/code_D2180.c.o(.data);
        build/us.v10/src/core2/ch/firefx.c.o(.data);
        build/us.v10/src/core2/ch/drips.c.o(.data);
        build/us.v10/src/core2/ch/icecube.c.o(.data);
        build/us.v10/src/core2/ch/ghost.c.o(.data);
        build/us.v10/src/core2/ch/flotsam.c.o(.data);
        build/us.v10/src/core2/ch/skeleton.c.o(.data);
        build/us.v10/src/core2/ch/seamangrublin.c.o(.data);
        build/us.v10/src/core2/ch/mummum.c.o(.data);
        build/us.v10/src/core2/ch/chumpfish.c.o(.data);
        build/us.v10/src/core2/ch/termite.c.o(.data);
        build/us.v10/src/core2/ch/gravestone.c.o(.data);
        build/us.v10/src/core2/ch/bat.c.o(.data);
        build/us.v10/src/core2/ch/whipcrack.c.o(.data);
        build/us.v10/src/core2/ch/betavent.c.o(.data);
        build/us.v10/src/core2/code_DA760.c.o(.data);
        build/us.v10/src/core2/code_DAAA0.c.o(.data);
        build/us.v10/src/core2/code_DB010.c.o(.data);
        build/us.v10/src/core2/code_DC4B0.c.o(.data);
        . = ALIGN(., 16);
        core2_DATA_END = .;
        core2_DATA_SIZE = ABSOLUTE(core2_DATA_END - core2_DATA_START);
        core2_RODATA_START = .;
        build/us.v10/src/core2/anctrl.c.o(.rodata);
        build/us.v10/src/core2/anim/sprite.c.o(.rodata);
        build/us.v10/src/core2/animcache.c.o(.rodata);
        build/us.v10/src/core2/code_1550.c.o(.rodata);
        build/us.v10/src/core2/anseq.c.o(.rodata);
        build/us.v10/src/core2/code_2240.c.o(.rodata);
        build/us.v10/src/core2/ba/anim.c.o(.rodata);
        build/us.v10/src/core2/snackerctl.c.o(.rodata);
        build/us.v10/src/core2/playerutils.c.o(.rodata);
        build/us.v10/src/core2/ba/marker.c.o(.rodata);
        build/us.v10/src/core2/code_6B30.c.o(.rodata);
        build/us.v10/src/core2/ba/carriedobj.c.o(.rodata);
        build/us.v10/src/core2/code_7060.c.o(.rodata);
        build/us.v10/src/core2/ba/flap.c.o(.rodata);
        build/us.v10/src/core2/code_90E0.c.o(.rodata);
        build/us.v10/src/core2/code_9290.c.o(.rodata);
        build/us.v10/src/core2/code_9450.c.o(.rodata);
        build/us.v10/src/core2/babuzz.c.o(.rodata);
        build/us.v10/src/core2/code_9BD0.c.o(.rodata);
        build/us.v10/src/core2/code_A600.c.o(.rodata);
        build/us.v10/src/core2/statetimer.c.o(.rodata);
        build/us.v10/src/core2/code_A960.c.o(.rodata);
        build/us.v10/src/core2/ba/model.c.o(.rodata);
        build/us.v10/src/core2/ba/drone.c.o(.rodata);
        build/us.v10/src/core2/code_B850.c.o(.rodata);
        build/us.v10/src/core2/eggshatter.c.o(.rodata);
        build/us.v10/src/core2/baeyes.c.o(.rodata);
        build/us.v10/src/core2/ba/falldamage.c.o(.rodata);
        build/us.v10/src/core2/baflag.c.o(.rodata);
        build/us.v10/src/core2/code_C4B0.c.o(.rodata);
        build/us.v10/src/core2/ba/carry.c.o(.rodata);
        build/us.v10/src/core2/code_D9B0.c.o(.rodata);
        build/us.v10/src/core2/bainput.c.o(.rodata);
        build/us.v10/src/core2/bakey.c.o(.rodata);
        build/us.v10/src/core2/abilityprogress.c.o(.rodata);
        build/us.v10/src/core2/bsmethods.c.o(.rodata);
        build/us.v10/src/core2/babounds.c.o(.rodata);
        build/us.v10/src/core2/code_EF50.c.o(.rodata);
        build/us.v10/src/core2/ba/physics.c.o(.rodata);
        build/us.v10/src/core2/ba/iFrame.c.o(.rodata);
        build/us.v10/src/core2/pitch.c.o(.rodata);
        build/us.v10/src/core2/code_11040.c.o(.rodata);
        build/us.v10/src/core2/climb.c.o(.rodata);
        build/us.v10/src/core2/playerposition.c.o(.rodata);
        build/us.v10/src/core2/playermodel.c.o(.rodata);
        build/us.v10/src/core2/code_117D0.c.o(.rodata);
        build/us.v10/src/core2/balookat.c.o(.rodata);
        build/us.v10/src/core2/roll.c.o(.rodata);
        build/us.v10/src/core2/yaw.c.o(.rodata);
        build/us.v10/src/core2/code_12360.c.o(.rodata);
        build/us.v10/src/core2/basfx.c.o(.rodata);
        build/us.v10/src/core2/code_12F30.c.o(.rodata);
        build/us.v10/src/core2/bsList.c.o(.rodata);
        build/us.v10/src/core2/code_13780.c.o(.rodata);
        build/us.v10/src/core2/bsStoredState.c.o(.rodata);
        build/us.v10/src/core2/code_13A00.c.o(.rodata);
        build/us.v10/src/core2/bastick.c.o(.rodata);
        build/us.v10/src/core2/code_14420.c.o(.rodata);
        build/us.v10/src/core2/code_15F20.c.o(.rodata);
        build/us.v10/src/core2/hazards.c.o(.rodata);
        build/us.v10/src/core2/modelappendages.c.o(.rodata);
        build/us.v10/src/core2/batimer.c.o(.rodata);
        build/us.v10/src/core2/bs/ant.c.o(.rodata);
        build/us.v10/src/core2/bs/bBarge.c.o(.rodata);
        build/us.v10/src/core2/bs/bbuster.c.o(.rodata);
        build/us.v10/src/core2/bs/bee.c.o(.rodata);
        build/us.v10/src/core2/bs/beeFly.c.o(.rodata);
        build/us.v10/src/core2/bs/beeMain.c.o(.rodata);
        build/us.v10/src/core2/bs/bEggAss.c.o(.rodata);
        build/us.v10/src/core2/bs/bEggHead.c.o(.rodata);
        build/us.v10/src/core2/bs/bFlap.c.o(.rodata);
        build/us.v10/src/core2/bs/bFlip.c.o(.rodata);
        build/us.v10/src/core2/bs/bFly.c.o(.rodata);
        build/us.v10/src/core2/bs/bLongLeg.c.o(.rodata);
        build/us.v10/src/core2/bs/bPeck.c.o(.rodata);
        build/us.v10/src/core2/bs/bShock.c.o(.rodata);
        build/us.v10/src/core2/bs/bSwim.c.o(.rodata);
        build/us.v10/src/core2/bs/bTrot.c.o(.rodata);
        build/us.v10/src/core2/bs/bWhirl.c.o(.rodata);
        build/us.v10/src/core2/bs/carry.c.o(.rodata);
        build/us.v10/src/core2/bs/claw.c.o(.rodata);
        build/us.v10/src/core2/bs/climb.c.o(.rodata);
        build/us.v10/src/core2/bs/croc.c.o(.rodata);
        build/us.v10/src/core2/bs/crouch.c.o(.rodata);
        build/us.v10/src/core2/bs/die.c.o(.rodata);
        build/us.v10/src/core2/bs/drone.c.o(.rodata);
        build/us.v10/src/core2/bs/droneenter.c.o(.rodata);
        build/us.v10/src/core2/bs/dronegoto.c.o(.rodata);
        build/us.v10/src/core2/bs/dronelook.c.o(.rodata);
        build/us.v10/src/core2/bs/dronevanish.c.o(.rodata);
        build/us.v10/src/core2/bs/dronexform.c.o(.rodata);
        build/us.v10/src/core2/bs/jig.c.o(.rodata);
        build/us.v10/src/core2/bs/jump.c.o(.rodata);
        build/us.v10/src/core2/bs/ow.c.o(.rodata);
        build/us.v10/src/core2/bs/pumpkin.c.o(.rodata);
        build/us.v10/src/core2/bs/rebound.c.o(.rodata);
        build/us.v10/src/core2/bs/rest.c.o(.rodata);
        build/us.v10/src/core2/bs/sled.c.o(.rodata);
        build/us.v10/src/core2/bs/slide.c.o(.rodata);
        build/us.v10/src/core2/bs/splat.c.o(.rodata);
        build/us.v10/src/core2/bs/stand.c.o(.rodata);
        build/us.v10/src/core2/bs/swim.c.o(.rodata);
        build/us.v10/src/core2/bs/surf.c.o(.rodata);
        build/us.v10/src/core2/bs/talk.c.o(.rodata);
        build/us.v10/src/core2/bs/timeout.c.o(.rodata);
        build/us.v10/src/core2/bs/throw.c.o(.rodata);
        build/us.v10/src/core2/bs/turn.c.o(.rodata);
        build/us.v10/src/core2/bs/twirl.c.o(.rodata);
        build/us.v10/src/core2/bs/walk.c.o(.rodata);
        build/us.v10/src/core2/bs/walrus.c.o(.rodata);
        build/us.v10/src/core2/bs/washy.c.o(.rodata);
        build/us.v10/src/core2/nc/cameranodelist.c.o(.rodata);
        build/us.v10/src/core2/code_33250.c.o(.rodata);
        build/us.v10/src/core2/code_33310.c.o(.rodata);
        build/us.v10/src/core2/code_336F0.c.o(.rodata);
        build/us.v10/src/core2/code_33AB0.c.o(.rodata);
        build/us.v10/src/core2/code_33C30.c.o(.rodata);
        build/us.v10/src/core2/nc/staticCamera.c.o(.rodata);
        build/us.v10/src/core2/code_33F90.c.o(.rodata);
        build/us.v10/src/core2/code_34310.c.o(.rodata);
        build/us.v10/src/core2/code_34790.c.o(.rodata);
        build/us.v10/src/core2/code_35520.c.o(.rodata);
        build/us.v10/src/core2/nc/dynamicCamera.c.o(.rodata);
        build/us.v10/src/core2/code_379B0.c.o(.rodata);
        build/us.v10/src/core2/nc/randomCamera.c.o(.rodata);
        build/us.v10/src/core2/code_37E50.c.o(.rodata);
        build/us.v10/src/core2/nc/dynamicCam10.c.o(.rodata);
        build/us.v10/src/core2/nc/ba/die.c.o(.rodata);
        build/us.v10/src/core2/nc/dynamicCam5.c.o(.rodata);
        build/us.v10/src/core2/nc/dynamicCam11.c.o(.rodata);
        build/us.v10/src/core2/nc/dynamicCam8.c.o(.rodata);
        build/us.v10/src/core2/nc/ba/fly.c.o(.rodata);
        build/us.v10/src/core2/nc/dynamicCamC.c.o(.rodata);
        build/us.v10/src/core2/code_F8EAF0.c.o(.rodata);
        build/us.v10/src/core2/nc/dynamicCamB.c.o(.rodata);
        build/us.v10/src/core2/nc/dynamicCam13.c.o(.rodata);
        build/us.v10/src/core2/nc/dynamicCam9.c.o(.rodata);
        build/us.v10/src/core2/nc/dynamicCam12.c.o(.rodata);
        build/us.v10/src/core2/nc/dynamicCam1.c.o(.rodata);
        build/us.v10/src/core2/nc/dynamicCam3.c.o(.rodata);
        build/us.v10/src/core2/nc/dynamicCamA.c.o(.rodata);
        build/us.v10/src/core2/code_3B2C0.c.o(.rodata);
        build/us.v10/src/core2/nc/dynamicCamF.c.o(.rodata);
        build/us.v10/src/core2/nc/ba/1p.c.o(.rodata);
        build/us.v10/src/core2/spawnqueue.c.o(.rodata);
        build/us.v10/src/core2/ch/gameSelect.c.o(.rodata);
        build/us.v10/src/core2/fx/shoesparkle.c.o(.rodata);
        build/us.v10/src/core2/ch/explosionripple.c.o(.rodata);
        build/us.v10/src/core2/ch/bubble.c.o(.rodata);
        build/us.v10/src/core2/ch/bigbutt.c.o(.rodata);
        build/us.v10/src/core2/code_400F0.c.o(.rodata);
        build/us.v10/src/core2/ch/jiggy.c.o(.rodata);
        build/us.v10/src/core2/ch/jigsawdance.c.o(.rodata);
        build/us.v10/src/core2/code_41460.c.o(.rodata);
        build/us.v10/src/core2/code_41F30.c.o(.rodata);
        build/us.v10/src/core2/code_41FB0.c.o(.rodata);
        build/us.v10/src/core2/ch/musicnote.c.o(.rodata);
        build/us.v10/src/core2/code_42CB0.c.o(.rodata);
        build/us.v10/src/core2/code_43250.c.o(.rodata);
        build/us.v10/src/core2/ch/trainers.c.o(.rodata);
        build/us.v10/src/core2/code_43800.c.o(.rodata);
        build/us.v10/src/core2/code_43A40.c.o(.rodata);
        build/us.v10/src/core2/mapspecificflags.c.o(.rodata);
        build/us.v10/src/core2/ch/crab.c.o(.rodata);
        build/us.v10/src/core2/code_45310.c.o(.rodata);
        build/us.v10/src/core2/ch/code_468E0.c.o(.rodata);
        build/us.v10/src/core2/ch/jinjo.c.o(.rodata);
        build/us.v10/src/core2/ch/beehive.c.o(.rodata);
        build/us.v10/src/core2/ch/beeswarm.c.o(.rodata);
        build/us.v10/src/core2/ch/soundsource.c.o(.rodata);
        build/us.v10/src/core2/ch/shrapnel.c.o(.rodata);
        build/us.v10/src/core2/ch/gloop.c.o(.rodata);
        build/us.v10/src/core2/ch/mumbo.c.o(.rodata);
        build/us.v10/src/core2/mumbosign.c.o(.rodata);
        build/us.v10/src/core2/code_4BE10.c.o(.rodata);
        build/us.v10/src/core2/code_4C020.c.o(.rodata);
        build/us.v10/src/core2/ch/wadingboots.c.o(.rodata);
        build/us.v10/src/core2/ch/badShad.c.o(.rodata);
        build/us.v10/src/core2/code_50490.c.o(.rodata);
        build/us.v10/src/core2/ch/climbBase.c.o(.rodata);
        build/us.v10/src/core2/levelcollectible.c.o(.rodata);
        build/us.v10/src/core2/ch/piranhaWaterParticles.c.o(.rodata);
        build/us.v10/src/core2/code_51950.c.o(.rodata);
        build/us.v10/src/core2/ch/collectible.c.o(.rodata);
        build/us.v10/src/core2/ch/mole.c.o(.rodata);
        build/us.v10/src/core2/ch/molehill.c.o(.rodata);
        build/us.v10/src/core2/code_53A10.c.o(.rodata);
        build/us.v10/src/core2/code_53C10.c.o(.rodata);
        build/us.v10/src/core2/code_54D50.c.o(.rodata);
        build/us.v10/src/core2/code_55180.c.o(.rodata);
        build/us.v10/src/core2/gc/gameoversign.c.o(.rodata);
        build/us.v10/src/core2/gc/theendsign.c.o(.rodata);
        build/us.v10/src/core2/gc/banjokazooiesign.c.o(.rodata);
        build/us.v10/src/core2/ch/overlaycopyright.c.o(.rodata);
        build/us.v10/src/core2/ch/overlaypressstart.c.o(.rodata);
        build/us.v10/src/core2/ch/overlaynocontroller.c.o(.rodata);
        build/us.v10/src/core2/ch/bottlesbonus.c.o(.rodata);
        build/us.v10/src/core2/ch/mumboshandwithpicture.c.o(.rodata);
        build/us.v10/src/core2/code_581D0.c.o(.rodata);
        build/us.v10/src/core2/ch/bottlesbonuscursor.c.o(.rodata);
        build/us.v10/src/core2/code_59780.c.o(.rodata);
        build/us.v10/src/core2/code_599E0.c.o(.rodata);
        build/us.v10/src/core2/ch/mumbotoken.c.o(.rodata);
        build/us.v10/src/core2/ch/snacker.c.o(.rodata);
        build/us.v10/src/core2/ch/snowman.c.o(.rodata);
        build/us.v10/src/core2/ch/snowball.c.o(.rodata);
        build/us.v10/src/core2/ch/snowmanhat.c.o(.rodata);
        build/us.v10/src/core2/mapsavestate.c.o(.rodata);
        build/us.v10/src/core2/code_5C240.c.o(.rodata);
        build/us.v10/src/core2/code_5C870.c.o(.rodata);
        build/us.v10/src/core2/code_5DBC0.c.o(.rodata);
        build/us.v10/src/core2/code_5FB00.c.o(.rodata);
        build/us.v10/src/core2/code_5FD80.c.o(.rodata);
        build/us.v10/src/core2/code_5FD90.c.o(.rodata);
        build/us.v10/src/core2/code_62FD0.c.o(.rodata);
        build/us.v10/src/core2/code_630D0.c.o(.rodata);
        build/us.v10/src/core2/code_63410.c.o(.rodata);
        build/us.v10/src/core2/code_63690.c.o(.rodata);
        build/us.v10/src/core2/code_637D0.c.o(.rodata);
        build/us.v10/src/core2/code_654C0.c.o(.rodata);
        build/us.v10/src/core2/code_66490.c.o(.rodata);
        build/us.v10/src/core2/vla.c.o(.rodata);
        build/us.v10/src/core2/fla.c.o(.rodata);
        build/us.v10/src/core2/code_66D90.c.o(.rodata);
        build/us.v10/src/core2/code_66FB0.c.o(.rodata);
        build/us.v10/src/core2/gc/bound.c.o(.rodata);
        build/us.v10/src/core2/dustemitter.c.o(.rodata);
        build/us.v10/src/core2/particle.c.o(.rodata);
        build/us.v10/src/core2/particleemittermanager.c.o(.rodata);
        build/us.v10/src/core2/code_6A4B0.c.o(.rodata);
        build/us.v10/src/core2/code_6AEF0.c.o(.rodata);
        build/us.v10/src/core2/code_6B030.c.o(.rodata);
        build/us.v10/src/core2/fx/ripple.c.o(.rodata);
        build/us.v10/src/core2/fx/sparkle.c.o(.rodata);
        build/us.v10/src/core2/code_6CD20.c.o(.rodata);
        build/us.v10/src/core2/code_6CEC0.c.o(.rodata);
        build/us.v10/src/core2/code_6D030.c.o(.rodata);
        build/us.v10/src/core2/code_6D270.c.o(.rodata);
        build/us.v10/src/core2/code_6D490.c.o(.rodata);
        build/us.v10/src/core2/print.c.o(.rodata);
        build/us.v10/src/core2/code_70C30.c.o(.rodata);
        build/us.v10/src/core2/code_70F20.c.o(.rodata);
        build/us.v10/src/core2/code_71820.c.o(.rodata);
        build/us.v10/src/core2/code_72060.c.o(.rodata);
        build/us.v10/src/core2/code_72B10.c.o(.rodata);
        build/us.v10/src/core2/code_73640.c.o(.rodata);
        build/us.v10/src/core2/code_74090.c.o(.rodata);
        build/us.v10/src/core2/code_74290.c.o(.rodata);
        build/us.v10/src/core2/code_74420.c.o(.rodata);
        build/us.v10/src/core2/code_74910.c.o(.rodata);
        build/us.v10/src/core2/code_74ED0.c.o(.rodata);
        build/us.v10/src/core2/code_75480.c.o(.rodata);
        build/us.v10/src/core2/code_75930.c.o(.rodata);
        build/us.v10/src/core2/code_75E90.c.o(.rodata);
        build/us.v10/src/core2/fx/common1score.c.o(.rodata);
        build/us.v10/src/core2/fx/common2score.c.o(.rodata);
        build/us.v10/src/core2/fx/honeycarrierscore.c.o(.rodata);
        build/us.v10/src/core2/code_77E50.c.o(.rodata);
        build/us.v10/src/core2/fx/jinjoscore.c.o(.rodata);
        build/us.v10/src/core2/fx/jinjoscore.c.o(.rodata);
        build/us.v10/src/core2/fx/lifescore.c.o(.rodata);
        build/us.v10/src/core2/fx/common3score.c.o(.rodata);
        build/us.v10/src/core2/fx/healthscore.c.o(.rodata);
        build/us.v10/src/core2/fx/airscore.c.o(.rodata);
        build/us.v10/src/core2/gccube.c.o(.rodata);
        build/us.v10/src/core2/mapModel.c.o(.rodata);
        build/us.v10/src/core2/propModelList.c.o(.rodata);
        build/us.v10/src/core2/gc/section.c.o(.rodata);
        build/us.v10/src/core2/gc/sky.c.o(.rodata);
        build/us.v10/src/core2/gc/transition.c.o(.rodata);
        build/us.v10/src/core2/code_851D0.c.o(.rodata);
        build/us.v10/src/core2/code_857B0.c.o(.rodata);
        build/us.v10/src/core2/code_85800.c.o(.rodata);
        build/us.v10/src/core2/gc/dialog.c.o(.rodata);
        build/us.v10/src/core2/gc/pauseMenu.c.o(.rodata);
        build/us.v10/src/core2/code_8DC20.c.o(.rodata);
        build/us.v10/src/core2/gc/zoombox.c.o(.rodata);
        build/us.v10/src/core2/code_91E10.c.o(.rodata);
        build/us.v10/src/core2/minigame.c.o(.rodata);
        build/us.v10/src/core2/gc/parade.c.o(.rodata);
        build/us.v10/src/core2/code_94620.c.o(.rodata);
        build/us.v10/src/core2/code_94780.c.o(.rodata);
        build/us.v10/src/core2/code_94A20.c.o(.rodata);
        build/us.v10/src/core2/code_956B0.c.o(.rodata);
        build/us.v10/src/core2/code_98CB0.c.o(.rodata);
        build/us.v10/src/core2/quizquestionaskedbitfield.c.o(.rodata);
        build/us.v10/src/core2/code_999A0.c.o(.rodata);
        build/us.v10/src/core2/jiggyscore.c.o(.rodata);
        build/us.v10/src/core2/honeycombscore.c.o(.rodata);
        build/us.v10/src/core2/mumboscore.c.o(.rodata);
        build/us.v10/src/core2/code_9A740.c.o(.rodata);
        build/us.v10/src/core2/code_9A9D0.c.o(.rodata);
        build/us.v10/src/core2/levelspecificflags.c.o(.rodata);
        build/us.v10/src/core2/code_9B180.c.o(.rodata);
        build/us.v10/src/core2/code_9B650.c.o(.rodata);
        build/us.v10/src/core2/code_9B990.c.o(.rodata);
        build/us.v10/src/core2/code_9C170.c.o(.rodata);
        build/us.v10/src/core2/code_9D640.c.o(.rodata);
        build/us.v10/src/core2/code_9D760.c.o(.rodata);
        build/us.v10/src/core2/timedfuncqueue.c.o(.rodata);
        build/us.v10/src/core2/code_9E370.c.o(.rodata);
        build/us.v10/src/core2/code_A4D00.c.o(.rodata);
        build/us.v10/src/core2/code_A5BC0.c.o(.rodata);
        build/us.v10/src/core2/code_ABC00.c.o(.rodata);
        build/us.v10/src/core2/gclights.c.o(.rodata);
        build/us.v10/src/core2/code_AD110.c.o(.rodata);
        build/us.v10/src/core2/gsworld.c.o(.rodata);
        build/us.v10/src/core2/code_AE290.c.o(.rodata);
        build/us.v10/src/core2/skeletalanim.c.o(.rodata);
        build/us.v10/src/core2/code_AEDA0.c.o(.rodata);
        build/us.v10/src/core2/modelRender.c.o(.rodata);
        build/us.v10/src/core2/code_B3580.c.o(.rodata);
        build/us.v10/src/core2/animationfile.c.o(.rodata);
        build/us.v10/src/core2/code_B3A80.c.o(.rodata);
        build/us.v10/src/core2/code_B5040.c.o(.rodata);
        build/us.v10/src/core2/code_B5E00.c.o(.rodata);
        build/us.v10/src/core2/code_B62B0.c.o(.rodata);
        build/us.v10/src/core2/code_B6640.c.o(.rodata);
        build/us.v10/src/core2/string.c.o(.rodata);
        build/us.v10/src/core2/code_B6C60.c.o(.rodata);
        build/us.v10/src/core2/time.c.o(.rodata);
        build/us.v10/src/core2/commonParticle.c.o(.rodata);
        build/us.v10/src/core2/coords.c.o(.rodata);
        build/us.v10/src/core2/code_B7F40.c.o(.rodata);
        build/us.v10/src/core2/code_B8020.c.o(.rodata);
        build/us.v10/src/core2/ultra/debug/assert.c.o(.rodata);
        build/us.v10/src/core2/code_B8080.c.o(.rodata);
        build/us.v10/src/core2/code_B8860.c.o(.rodata);
        build/us.v10/src/core2/code_B9090.c.o(.rodata);
        build/us.v10/src/core2/code_B9770.c.o(.rodata);
        build/us.v10/src/core2/code_BD100.c.o(.rodata);
        build/us.v10/src/core2/code_BDCC0.c.o(.rodata);
        build/us.v10/src/core2/code_BE2C0.c.o(.rodata);
        build/us.v10/src/core2/code_BEF20.c.o(.rodata);
        build/us.v10/src/core2/code_C0B80.c.o(.rodata);
        build/us.v10/src/core2/code_C0CF0.c.o(.rodata);
        build/us.v10/src/core2/code_C0E60.c.o(.rodata);
        build/us.v10/src/core2/animtexturecache.c.o(.rodata);
        build/us.v10/src/core2/demo.c.o(.rodata);
        build/us.v10/src/core2/code_C31A0.c.o(.rodata);
        build/us.v10/src/core2/rand.c.o(.rodata);
        build/us.v10/src/core2/code_C3A40.c.o(.rodata);
        build/us.v10/src/core2/file.c.o(.rodata);
        build/us.v10/src/core2/code_C4320.c.o(.rodata);
        build/us.v10/src/core2/code_C4F40.c.o(.rodata);
        build/us.v10/src/core2/code_C5440.c.o(.rodata);
        build/us.v10/src/core2/code_C5AF0.c.o(.rodata);
        build/us.v10/src/core2/code_C5CC0.c.o(.rodata);
        build/us.v10/src/core2/code_C5F00.c.o(.rodata);
        build/us.v10/src/core2/code_C61C0.c.o(.rodata);
        build/us.v10/src/core2/code_C62B0.c.o(.rodata);
        build/us.v10/src/core2/code_C76D0.c.o(.rodata);
        build/us.v10/src/core2/code_C7CC0.c.o(.rodata);
        build/us.v10/src/core2/code_C8230.c.o(.rodata);
        build/us.v10/src/core2/code_C8360.c.o(.rodata);
        build/us.v10/src/core2/code_C8490.c.o(.rodata);
        build/us.v10/src/core2/code_C8760.c.o(.rodata);
        build/us.v10/src/core2/code_C89C0.c.o(.rodata);
        build/us.v10/src/core2/lensflare.c.o(.rodata);
        build/us.v10/src/core2/code_C9E70.c.o(.rodata);
        build/us.v10/src/core2/code_C9F00.c.o(.rodata);
        build/us.v10/src/core2/code_CB050.c.o(.rodata);
        build/us.v10/src/core2/code_CB610.c.o(.rodata);
        build/us.v10/src/core2/commonParticleTypeMap.c.o(.rodata);
        build/us.v10/src/core2/code_CBBF0.c.o(.rodata);
        build/us.v10/src/core2/code_CBD10.c.o(.rodata);
        build/us.v10/src/core2/code_CC1E0.c.o(.rodata);
        build/us.v10/src/core2/code_CD0A0.c.o(.rodata);
        build/us.v10/src/core2/code_CD3F0.c.o(.rodata);
        build/us.v10/src/core2/code_CD6E0.c.o(.rodata);
        build/us.v10/src/core2/code_CECD0.c.o(.rodata);
        build/us.v10/src/core2/code_CF090.c.o(.rodata);
        build/us.v10/src/core2/progressDialog.c.o(.rodata);
        build/us.v10/src/core2/code_CF5F0.c.o(.rodata);
        build/us.v10/src/core2/ch/clankerwhipcrack.c.o(.rodata);
        build/us.v10/src/core2/ch/grillechompa.c.o(.rodata);
        build/us.v10/src/core2/ch/clucker.c.o(.rodata);
        build/us.v10/src/core2/ch/scarabbeetle.c.o(.rodata);
        build/us.v10/src/core2/code_D2180.c.o(.rodata);
        build/us.v10/src/core2/ch/firefx.c.o(.rodata);
        build/us.v10/src/core2/ch/drips.c.o(.rodata);
        build/us.v10/src/core2/ch/icecube.c.o(.rodata);
        build/us.v10/src/core2/ch/ghost.c.o(.rodata);
        build/us.v10/src/core2/ch/flotsam.c.o(.rodata);
        build/us.v10/src/core2/ch/skeleton.c.o(.rodata);
        build/us.v10/src/core2/ch/seamangrublin.c.o(.rodata);
        build/us.v10/src/core2/ch/mummum.c.o(.rodata);
        build/us.v10/src/core2/ch/chumpfish.c.o(.rodata);
        build/us.v10/src/core2/ch/termite.c.o(.rodata);
        build/us.v10/src/core2/ch/gravestone.c.o(.rodata);
        build/us.v10/src/core2/ch/bat.c.o(.rodata);
        build/us.v10/src/core2/ch/bat.c.o(.rodata);
        build/us.v10/src/core2/ch/whipcrack.c.o(.rodata);
        build/us.v10/src/core2/ch/betavent.c.o(.rodata);
        build/us.v10/src/core2/code_DA760.c.o(.rodata);
        build/us.v10/src/core2/code_DAAA0.c.o(.rodata);
        build/us.v10/src/core2/code_DB010.c.o(.rodata);
        build/us.v10/src/core2/code_DC4B0.c.o(.rodata);
        . = ALIGN(., 16);
        core2_RODATA_END = .;
        core2_RODATA_SIZE = ABSOLUTE(core2_RODATA_END - core2_RODATA_START);
    }
    core2_bss_VRAM = ADDR(.core2_bss);
    .core2_bss (NOLOAD) : SUBALIGN(16)
    {
        FILL(0x00000000);
        core2_BSS_START = .;
        build/us.v10/src/core2/anctrl.c.o(.bss);
        build/us.v10/src/core2/checksums.c.o(.bss);
        build/us.v10/src/core2/anim/sprite.c.o(.bss);
        build/us.v10/src/core2/animcache.c.o(.bss);
        build/us.v10/src/core2/code_1550.c.o(.bss);
        build/us.v10/src/core2/anseq.c.o(.bss);
        build/us.v10/src/core2/code_2240.c.o(.bss);
        build/us.v10/src/core2/ba/anim.c.o(.bss);
        build/us.v10/src/core2/snackerctl.c.o(.bss);
        build/us.v10/src/core2/playerutils.c.o(.bss);
        build/us.v10/src/core2/ba/marker.c.o(.bss);
        build/us.v10/src/core2/code_6B30.c.o(.bss);
        build/us.v10/src/core2/ba/carriedobj.c.o(.bss);
        build/us.v10/src/core2/code_7060.c.o(.bss);
        build/us.v10/src/core2/ba/flap.c.o(.bss);
        build/us.v10/src/core2/code_90E0.c.o(.bss);
        build/us.v10/src/core2/code_9290.c.o(.bss);
        build/us.v10/src/core2/code_9450.c.o(.bss);
        build/us.v10/src/core2/babuzz.c.o(.bss);
        build/us.v10/src/core2/code_9BD0.c.o(.bss);
        build/us.v10/src/core2/code_A600.c.o(.bss);
        build/us.v10/src/core2/statetimer.c.o(.bss);
        build/us.v10/src/core2/code_A960.c.o(.bss);
        build/us.v10/src/core2/ba/model.c.o(.bss);
        build/us.v10/src/core2/ba/drone.c.o(.bss);
        build/us.v10/src/core2/code_B850.c.o(.bss);
        build/us.v10/src/core2/eggshatter.c.o(.bss);
        build/us.v10/src/core2/baeyes.c.o(.bss);
        build/us.v10/src/core2/ba/falldamage.c.o(.bss);
        build/us.v10/src/core2/baflag.c.o(.bss);
        build/us.v10/src/core2/code_C4B0.c.o(.bss);
        build/us.v10/src/core2/ba/carry.c.o(.bss);
        build/us.v10/src/core2/code_D9B0.c.o(.bss);
        build/us.v10/src/core2/bainput.c.o(.bss);
        build/us.v10/src/core2/bakey.c.o(.bss);
        build/us.v10/src/core2/abilityprogress.c.o(.bss);
        build/us.v10/src/core2/bsmethods.c.o(.bss);
        build/us.v10/src/core2/babounds.c.o(.bss);
        build/us.v10/src/core2/code_EF50.c.o(.bss);
        build/us.v10/src/core2/ba/physics.c.o(.bss);
        build/us.v10/src/core2/ba/iFrame.c.o(.bss);
        build/us.v10/src/core2/pitch.c.o(.bss);
        build/us.v10/src/core2/code_11040.c.o(.bss);
        build/us.v10/src/core2/climb.c.o(.bss);
        build/us.v10/src/core2/playerposition.c.o(.bss);
        build/us.v10/src/core2/playermodel.c.o(.bss);
        build/us.v10/src/core2/code_117D0.c.o(.bss);
        build/us.v10/src/core2/balookat.c.o(.bss);
        build/us.v10/src/core2/roll.c.o(.bss);
        build/us.v10/src/core2/yaw.c.o(.bss);
        build/us.v10/src/core2/code_12360.c.o(.bss);
        build/us.v10/src/core2/basfx.c.o(.bss);
        build/us.v10/src/core2/code_12F30.c.o(.bss);
        build/us.v10/src/core2/bsList.c.o(.bss);
        build/us.v10/src/core2/code_13780.c.o(.bss);
        build/us.v10/src/core2/bsStoredState.c.o(.bss);
        build/us.v10/src/core2/code_13A00.c.o(.bss);
        build/us.v10/src/core2/bastick.c.o(.bss);
        build/us.v10/src/core2/code_14420.c.o(.bss);
        build/us.v10/src/core2/code_15F20.c.o(.bss);
        build/us.v10/src/core2/hazards.c.o(.bss);
        build/us.v10/src/core2/modelappendages.c.o(.bss);
        build/us.v10/src/core2/batimer.c.o(.bss);
        build/us.v10/src/core2/bs/ant.c.o(.bss);
        build/us.v10/src/core2/bs/bBarge.c.o(.bss);
        build/us.v10/src/core2/bs/bbuster.c.o(.bss);
        build/us.v10/src/core2/bs/bee.c.o(.bss);
        build/us.v10/src/core2/bs/beeFly.c.o(.bss);
        build/us.v10/src/core2/bs/beeMain.c.o(.bss);
        build/us.v10/src/core2/bs/bEggAss.c.o(.bss);
        build/us.v10/src/core2/bs/bEggHead.c.o(.bss);
        build/us.v10/src/core2/bs/bFlap.c.o(.bss);
        build/us.v10/src/core2/bs/bFlip.c.o(.bss);
        build/us.v10/src/core2/bs/bFly.c.o(.bss);
        build/us.v10/src/core2/bs/bLongLeg.c.o(.bss);
        build/us.v10/src/core2/bs/bPeck.c.o(.bss);
        build/us.v10/src/core2/bs/bShock.c.o(.bss);
        build/us.v10/src/core2/bs/bSwim.c.o(.bss);
        build/us.v10/src/core2/bs/bTrot.c.o(.bss);
        build/us.v10/src/core2/bs/bWhirl.c.o(.bss);
        build/us.v10/src/core2/bs/carry.c.o(.bss);
        build/us.v10/src/core2/bs/claw.c.o(.bss);
        build/us.v10/src/core2/bs/climb.c.o(.bss);
        build/us.v10/src/core2/bs/croc.c.o(.bss);
        build/us.v10/src/core2/bs/crouch.c.o(.bss);
        build/us.v10/src/core2/bs/die.c.o(.bss);
        build/us.v10/src/core2/bs/drone.c.o(.bss);
        build/us.v10/src/core2/bs/droneenter.c.o(.bss);
        build/us.v10/src/core2/bs/dronegoto.c.o(.bss);
        build/us.v10/src/core2/bs/dronelook.c.o(.bss);
        build/us.v10/src/core2/bs/dronevanish.c.o(.bss);
        build/us.v10/src/core2/bs/dronexform.c.o(.bss);
        build/us.v10/src/core2/bs/jig.c.o(.bss);
        build/us.v10/src/core2/bs/jump.c.o(.bss);
        build/us.v10/src/core2/bs/ow.c.o(.bss);
        build/us.v10/src/core2/bs/pumpkin.c.o(.bss);
        build/us.v10/src/core2/bs/rebound.c.o(.bss);
        build/us.v10/src/core2/bs/rest.c.o(.bss);
        build/us.v10/src/core2/bs/sled.c.o(.bss);
        build/us.v10/src/core2/bs/slide.c.o(.bss);
        build/us.v10/src/core2/bs/splat.c.o(.bss);
        build/us.v10/src/core2/bs/stand.c.o(.bss);
        build/us.v10/src/core2/bs/swim.c.o(.bss);
        build/us.v10/src/core2/bs/surf.c.o(.bss);
        build/us.v10/src/core2/bs/talk.c.o(.bss);
        build/us.v10/src/core2/bs/timeout.c.o(.bss);
        build/us.v10/src/core2/bs/throw.c.o(.bss);
        build/us.v10/src/core2/bs/turn.c.o(.bss);
        build/us.v10/src/core2/bs/twirl.c.o(.bss);
        build/us.v10/src/core2/bs/walk.c.o(.bss);
        build/us.v10/src/core2/bs/walrus.c.o(.bss);
        build/us.v10/src/core2/bs/washy.c.o(.bss);
        build/us.v10/src/core2/nc/cameranodelist.c.o(.bss);
        build/us.v10/src/core2/code_33250.c.o(.bss);
        build/us.v10/src/core2/code_33310.c.o(.bss);
        build/us.v10/src/core2/code_336F0.c.o(.bss);
        build/us.v10/src/core2/code_33AB0.c.o(.bss);
        build/us.v10/src/core2/code_33C30.c.o(.bss);
        build/us.v10/src/core2/nc/staticCamera.c.o(.bss);
        build/us.v10/src/core2/code_33F90.c.o(.bss);
        build/us.v10/src/core2/code_34310.c.o(.bss);
        build/us.v10/src/core2/code_34790.c.o(.bss);
        build/us.v10/src/core2/code_35520.c.o(.bss);
        build/us.v10/src/core2/nc/dynamicCamera.c.o(.bss);
        build/us.v10/src/core2/code_379B0.c.o(.bss);
        build/us.v10/src/core2/nc/randomCamera.c.o(.bss);
        build/us.v10/src/core2/code_37E50.c.o(.bss);
        build/us.v10/src/core2/nc/dynamicCam10.c.o(.bss);
        build/us.v10/src/core2/nc/ba/die.c.o(.bss);
        build/us.v10/src/core2/nc/dynamicCam5.c.o(.bss);
        build/us.v10/src/core2/nc/dynamicCam11.c.o(.bss);
        build/us.v10/src/core2/nc/dynamicCam8.c.o(.bss);
        build/us.v10/src/core2/nc/ba/fly.c.o(.bss);
        build/us.v10/src/core2/nc/dynamicCamC.c.o(.bss);
        build/us.v10/src/core2/code_F8EAF0.c.o(.bss);
        build/us.v10/src/core2/nc/dynamicCamB.c.o(.bss);
        build/us.v10/src/core2/nc/dynamicCam13.c.o(.bss);
        build/us.v10/src/core2/nc/dynamicCam9.c.o(.bss);
        build/us.v10/src/core2/nc/dynamicCam12.c.o(.bss);
        build/us.v10/src/core2/nc/dynamicCam1.c.o(.bss);
        build/us.v10/src/core2/nc/dynamicCam3.c.o(.bss);
        build/us.v10/src/core2/nc/dynamicCamA.c.o(.bss);
        build/us.v10/src/core2/code_3B2C0.c.o(.bss);
        build/us.v10/src/core2/nc/dynamicCamF.c.o(.bss);
        build/us.v10/src/core2/nc/ba/1p.c.o(.bss);
        build/us.v10/src/core2/spawnqueue.c.o(.bss);
        build/us.v10/src/core2/ch/gameSelect.c.o(.bss);
        build/us.v10/src/core2/fx/shoesparkle.c.o(.bss);
        build/us.v10/src/core2/ch/explosionripple.c.o(.bss);
        build/us.v10/src/core2/ch/bubble.c.o(.bss);
        build/us.v10/src/core2/ch/bigbutt.c.o(.bss);
        build/us.v10/src/core2/code_400F0.c.o(.bss);
        build/us.v10/src/core2/ch/jiggy.c.o(.bss);
        build/us.v10/src/core2/ch/jigsawdance.c.o(.bss);
        build/us.v10/src/core2/code_41460.c.o(.bss);
        build/us.v10/src/core2/code_41F30.c.o(.bss);
        build/us.v10/src/core2/code_41FB0.c.o(.bss);
        build/us.v10/src/core2/ch/musicnote.c.o(.bss);
        build/us.v10/src/core2/code_42CB0.c.o(.bss);
        build/us.v10/src/core2/code_43250.c.o(.bss);
        build/us.v10/src/core2/ch/trainers.c.o(.bss);
        build/us.v10/src/core2/code_43800.c.o(.bss);
        build/us.v10/src/core2/code_43A40.c.o(.bss);
        build/us.v10/src/core2/mapspecificflags.c.o(.bss);
        build/us.v10/src/core2/ch/crab.c.o(.bss);
        build/us.v10/src/core2/code_45310.c.o(.bss);
        build/us.v10/src/core2/ch/code_468E0.c.o(.bss);
        build/us.v10/src/core2/ch/jinjo.c.o(.bss);
        build/us.v10/src/core2/ch/beehive.c.o(.bss);
        build/us.v10/src/core2/ch/beeswarm.c.o(.bss);
        build/us.v10/src/core2/ch/soundsource.c.o(.bss);
        build/us.v10/src/core2/ch/shrapnel.c.o(.bss);
        build/us.v10/src/core2/ch/gloop.c.o(.bss);
        build/us.v10/src/core2/ch/mumbo.c.o(.bss);
        build/us.v10/src/core2/mumbosign.c.o(.bss);
        build/us.v10/src/core2/code_4BE10.c.o(.bss);
        build/us.v10/src/core2/code_4C020.c.o(.bss);
        build/us.v10/src/core2/ch/wadingboots.c.o(.bss);
        build/us.v10/src/core2/ch/badShad.c.o(.bss);
        build/us.v10/src/core2/code_50490.c.o(.bss);
        build/us.v10/src/core2/ch/climbBase.c.o(.bss);
        build/us.v10/src/core2/levelcollectible.c.o(.bss);
        build/us.v10/src/core2/ch/piranhaWaterParticles.c.o(.bss);
        build/us.v10/src/core2/code_51950.c.o(.bss);
        build/us.v10/src/core2/ch/collectible.c.o(.bss);
        build/us.v10/src/core2/ch/mole.c.o(.bss);
        build/us.v10/src/core2/ch/molehill.c.o(.bss);
        build/us.v10/src/core2/code_53A10.c.o(.bss);
        build/us.v10/src/core2/code_53C10.c.o(.bss);
        build/us.v10/src/core2/code_54D50.c.o(.bss);
        build/us.v10/src/core2/code_55180.c.o(.bss);
        build/us.v10/src/core2/gc/gameoversign.c.o(.bss);
        build/us.v10/src/core2/gc/theendsign.c.o(.bss);
        build/us.v10/src/core2/gc/banjokazooiesign.c.o(.bss);
        build/us.v10/src/core2/ch/overlaycopyright.c.o(.bss);
        build/us.v10/src/core2/ch/overlaypressstart.c.o(.bss);
        build/us.v10/src/core2/ch/overlaynocontroller.c.o(.bss);
        build/us.v10/src/core2/ch/bottlesbonus.c.o(.bss);
        build/us.v10/src/core2/ch/mumboshandwithpicture.c.o(.bss);
        build/us.v10/src/core2/code_581D0.c.o(.bss);
        build/us.v10/src/core2/ch/bottlesbonuscursor.c.o(.bss);
        build/us.v10/src/core2/code_59780.c.o(.bss);
        build/us.v10/src/core2/code_599E0.c.o(.bss);
        build/us.v10/src/core2/ch/mumbotoken.c.o(.bss);
        build/us.v10/src/core2/ch/snacker.c.o(.bss);
        build/us.v10/src/core2/ch/snowman.c.o(.bss);
        build/us.v10/src/core2/ch/snowball.c.o(.bss);
        build/us.v10/src/core2/ch/snowmanhat.c.o(.bss);
        build/us.v10/src/core2/mapsavestate.c.o(.bss);
        build/us.v10/src/core2/code_5C240.c.o(.bss);
        build/us.v10/src/core2/code_5C870.c.o(.bss);
        build/us.v10/src/core2/code_5DBC0.c.o(.bss);
        build/us.v10/src/core2/code_5FB00.c.o(.bss);
        build/us.v10/src/core2/code_5FD80.c.o(.bss);
        build/us.v10/src/core2/code_5FD90.c.o(.bss);
        build/us.v10/src/core2/code_62FD0.c.o(.bss);
        build/us.v10/src/core2/code_630D0.c.o(.bss);
        build/us.v10/src/core2/code_63410.c.o(.bss);
        build/us.v10/src/core2/code_63690.c.o(.bss);
        build/us.v10/src/core2/code_637D0.c.o(.bss);
        build/us.v10/src/core2/code_654C0.c.o(.bss);
        build/us.v10/src/core2/code_66490.c.o(.bss);
        build/us.v10/src/core2/vla.c.o(.bss);
        build/us.v10/src/core2/fla.c.o(.bss);
        build/us.v10/src/core2/code_66D90.c.o(.bss);
        build/us.v10/src/core2/code_66FB0.c.o(.bss);
        build/us.v10/src/core2/gc/bound.c.o(.bss);
        build/us.v10/src/core2/dustemitter.c.o(.bss);
        build/us.v10/src/core2/particle.c.o(.bss);
        build/us.v10/src/core2/particleemittermanager.c.o(.bss);
        build/us.v10/src/core2/code_6A4B0.c.o(.bss);
        build/us.v10/src/core2/code_6AEF0.c.o(.bss);
        build/us.v10/src/core2/code_6B030.c.o(.bss);
        build/us.v10/src/core2/fx/ripple.c.o(.bss);
        build/us.v10/src/core2/fx/sparkle.c.o(.bss);
        build/us.v10/src/core2/code_6CD20.c.o(.bss);
        build/us.v10/src/core2/code_6CEC0.c.o(.bss);
        build/us.v10/src/core2/code_6D030.c.o(.bss);
        build/us.v10/src/core2/code_6D270.c.o(.bss);
        build/us.v10/src/core2/code_6D490.c.o(.bss);
        build/us.v10/src/core2/print.c.o(.bss);
        build/us.v10/src/core2/print.c.o(.bss);
        build/us.v10/src/core2/code_70C30.c.o(.bss);
        build/us.v10/src/core2/code_70F20.c.o(.bss);
        build/us.v10/src/core2/code_71820.c.o(.bss);
        build/us.v10/src/core2/code_72060.c.o(.bss);
        build/us.v10/src/core2/code_72B10.c.o(.bss);
        build/us.v10/src/core2/code_73640.c.o(.bss);
        build/us.v10/src/core2/code_74090.c.o(.bss);
        build/us.v10/src/core2/code_74290.c.o(.bss);
        build/us.v10/src/core2/code_74420.c.o(.bss);
        build/us.v10/src/core2/code_74910.c.o(.bss);
        build/us.v10/src/core2/code_74ED0.c.o(.bss);
        build/us.v10/src/core2/code_75480.c.o(.bss);
        build/us.v10/src/core2/code_75930.c.o(.bss);
        build/us.v10/src/core2/code_75E90.c.o(.bss);
        build/us.v10/src/core2/fx/common1score.c.o(.bss);
        build/us.v10/src/core2/fx/common2score.c.o(.bss);
        build/us.v10/src/core2/fx/honeycarrierscore.c.o(.bss);
        build/us.v10/src/core2/code_77E50.c.o(.bss);
        build/us.v10/src/core2/fx/jinjoscore.c.o(.bss);
        build/us.v10/src/core2/fx/lifescore.c.o(.bss);
        build/us.v10/src/core2/fx/common3score.c.o(.bss);
        build/us.v10/src/core2/fx/healthscore.c.o(.bss);
        build/us.v10/src/core2/fx/airscore.c.o(.bss);
        build/us.v10/src/core2/gccube.c.o(.bss);
        build/us.v10/src/core2/mapModel.c.o(.bss);
        build/us.v10/src/core2/propModelList.c.o(.bss);
        build/us.v10/src/core2/gc/section.c.o(.bss);
        build/us.v10/src/core2/gc/sky.c.o(.bss);
        build/us.v10/src/core2/gc/transition.c.o(.bss);
        build/us.v10/src/core2/code_851D0.c.o(.bss);
        build/us.v10/src/core2/code_857B0.c.o(.bss);
        build/us.v10/src/core2/code_85800.c.o(.bss);
        build/us.v10/src/core2/gc/dialog.c.o(.bss);
        build/us.v10/src/core2/gc/pauseMenu.c.o(.bss);
        build/us.v10/src/core2/code_8DC20.c.o(.bss);
        build/us.v10/src/core2/gc/zoombox.c.o(.bss);
        build/us.v10/src/core2/code_91E10.c.o(.bss);
        build/us.v10/src/core2/minigame.c.o(.bss);
        build/us.v10/src/core2/gc/parade.c.o(.bss);
        build/us.v10/src/core2/code_94620.c.o(.bss);
        build/us.v10/src/core2/code_94780.c.o(.bss);
        build/us.v10/src/core2/code_94A20.c.o(.bss);
        build/us.v10/src/core2/code_956B0.c.o(.bss);
        build/us.v10/src/core2/code_98CB0.c.o(.bss);
        build/us.v10/src/core2/quizquestionaskedbitfield.c.o(.bss);
        build/us.v10/src/core2/code_999A0.c.o(.bss);
        build/us.v10/src/core2/jiggyscore.c.o(.bss);
        build/us.v10/src/core2/honeycombscore.c.o(.bss);
        build/us.v10/src/core2/mumboscore.c.o(.bss);
        build/us.v10/src/core2/code_9A740.c.o(.bss);
        build/us.v10/src/core2/code_9A9D0.c.o(.bss);
        build/us.v10/src/core2/levelspecificflags.c.o(.bss);
        build/us.v10/src/core2/code_9B180.c.o(.bss);
        build/us.v10/src/core2/code_9B650.c.o(.bss);
        build/us.v10/src/core2/code_9B990.c.o(.bss);
        build/us.v10/src/core2/code_9C170.c.o(.bss);
        build/us.v10/src/core2/code_9D640.c.o(.bss);
        build/us.v10/src/core2/code_9D760.c.o(.bss);
        build/us.v10/src/core2/timedfuncqueue.c.o(.bss);
        build/us.v10/src/core2/code_9E370.c.o(.bss);
        build/us.v10/src/core2/code_A4D00.c.o(.bss);
        build/us.v10/src/core2/code_A5BC0.c.o(.bss);
        build/us.v10/src/core2/code_ABC00.c.o(.bss);
        build/us.v10/src/core2/gclights.c.o(.bss);
        build/us.v10/src/core2/code_AD110.c.o(.bss);
        build/us.v10/src/core2/gsworld.c.o(.bss);
        build/us.v10/src/core2/code_AE290.c.o(.bss);
        build/us.v10/src/core2/skeletalanim.c.o(.bss);
        build/us.v10/src/core2/code_AEDA0.c.o(.bss);
        build/us.v10/src/core2/modelRender.c.o(.bss);
        build/us.v10/src/core2/code_B3580.c.o(.bss);
        build/us.v10/src/core2/animationfile.c.o(.bss);
        build/us.v10/src/core2/code_B3A80.c.o(.bss);
        build/us.v10/src/core2/code_B5040.c.o(.bss);
        build/us.v10/src/core2/code_B5E00.c.o(.bss);
        build/us.v10/src/core2/code_B62B0.c.o(.bss);
        build/us.v10/src/core2/code_B6640.c.o(.bss);
        build/us.v10/src/core2/string.c.o(.bss);
        build/us.v10/src/core2/code_B6C60.c.o(.bss);
        build/us.v10/src/core2/time.c.o(.bss);
        build/us.v10/src/core2/commonParticle.c.o(.bss);
        build/us.v10/src/core2/coords.c.o(.bss);
        build/us.v10/src/core2/code_B7F40.c.o(.bss);
        build/us.v10/src/core2/code_B8020.c.o(.bss);
        build/us.v10/src/core2/ultra/debug/assert.c.o(.bss);
        build/us.v10/src/core2/code_B8080.c.o(.bss);
        build/us.v10/src/core2/code_B8860.c.o(.bss);
        build/us.v10/src/core2/code_B9090.c.o(.bss);
        build/us.v10/src/core2/code_B9770.c.o(.bss);
        build/us.v10/src/core2/code_BD100.c.o(.bss);
        build/us.v10/src/core2/code_BDCC0.c.o(.bss);
        build/us.v10/src/core2/code_BE2C0.c.o(.bss);
        build/us.v10/src/core2/code_BEF20.c.o(.bss);
        build/us.v10/src/core2/code_C0B80.c.o(.bss);
        build/us.v10/src/core2/code_C0CF0.c.o(.bss);
        build/us.v10/src/core2/code_C0E60.c.o(.bss);
        build/us.v10/src/core2/animtexturecache.c.o(.bss);
        build/us.v10/src/core2/demo.c.o(.bss);
        build/us.v10/src/core2/code_C31A0.c.o(.bss);
        build/us.v10/src/core2/rand.c.o(.bss);
        build/us.v10/src/core2/code_C3A40.c.o(.bss);
        build/us.v10/src/core2/file.c.o(.bss);
        build/us.v10/src/core2/code_C4320.c.o(.bss);
        build/us.v10/src/core2/code_C4F40.c.o(.bss);
        build/us.v10/src/core2/code_C5440.c.o(.bss);
        build/us.v10/src/core2/code_C5AF0.c.o(.bss);
        build/us.v10/src/core2/code_C5CC0.c.o(.bss);
        build/us.v10/src/core2/code_C5F00.c.o(.bss);
        build/us.v10/src/core2/code_C61C0.c.o(.bss);
        build/us.v10/src/core2/code_C62B0.c.o(.bss);
        build/us.v10/src/core2/code_C76D0.c.o(.bss);
        build/us.v10/src/core2/code_C7CC0.c.o(.bss);
        build/us.v10/src/core2/code_C8230.c.o(.bss);
        build/us.v10/src/core2/code_C8360.c.o(.bss);
        build/us.v10/src/core2/code_C8490.c.o(.bss);
        build/us.v10/src/core2/code_C8760.c.o(.bss);
        build/us.v10/src/core2/code_C89C0.c.o(.bss);
        build/us.v10/src/core2/lensflare.c.o(.bss);
        build/us.v10/src/core2/code_C9E70.c.o(.bss);
        build/us.v10/src/core2/code_C9F00.c.o(.bss);
        build/us.v10/src/core2/code_CB050.c.o(.bss);
        build/us.v10/src/core2/code_CB610.c.o(.bss);
        build/us.v10/src/core2/commonParticleTypeMap.c.o(.bss);
        build/us.v10/src/core2/code_CBBF0.c.o(.bss);
        build/us.v10/src/core2/code_CBD10.c.o(.bss);
        build/us.v10/src/core2/code_CC1E0.c.o(.bss);
        build/us.v10/src/core2/code_CD0A0.c.o(.bss);
        build/us.v10/src/core2/code_CD3F0.c.o(.bss);
        build/us.v10/src/core2/code_CD6E0.c.o(.bss);
        build/us.v10/src/core2/code_CECD0.c.o(.bss);
        build/us.v10/src/core2/code_CF090.c.o(.bss);
        build/us.v10/src/core2/progressDialog.c.o(.bss);
        build/us.v10/src/core2/code_CF5F0.c.o(.bss);
        build/us.v10/src/core2/ch/clankerwhipcrack.c.o(.bss);
        build/us.v10/src/core2/ch/grillechompa.c.o(.bss);
        build/us.v10/src/core2/ch/clucker.c.o(.bss);
        build/us.v10/src/core2/ch/scarabbeetle.c.o(.bss);
        build/us.v10/src/core2/code_D2180.c.o(.bss);
        build/us.v10/src/core2/ch/firefx.c.o(.bss);
        build/us.v10/src/core2/ch/drips.c.o(.bss);
        build/us.v10/src/core2/ch/icecube.c.o(.bss);
        build/us.v10/src/core2/ch/ghost.c.o(.bss);
        build/us.v10/src/core2/ch/flotsam.c.o(.bss);
        build/us.v10/src/core2/ch/skeleton.c.o(.bss);
        build/us.v10/src/core2/ch/seamangrublin.c.o(.bss);
        build/us.v10/src/core2/ch/mummum.c.o(.bss);
        build/us.v10/src/core2/ch/chumpfish.c.o(.bss);
        build/us.v10/src/core2/ch/termite.c.o(.bss);
        build/us.v10/src/core2/ch/gravestone.c.o(.bss);
        build/us.v10/src/core2/ch/bat.c.o(.bss);
        build/us.v10/src/core2/ch/whipcrack.c.o(.bss);
        build/us.v10/src/core2/ch/betavent.c.o(.bss);
        build/us.v10/src/core2/code_DA760.c.o(.bss);
        build/us.v10/src/core2/code_DAAA0.c.o(.bss);
        build/us.v10/src/core2/code_DB010.c.o(.bss);
        build/us.v10/src/core2/code_DC4B0.c.o(.bss);
        . = ALIGN(., 16);
        core2_BSS_END = .;
        core2_BSS_SIZE = ABSOLUTE(core2_BSS_END - core2_BSS_START);
    }
    __romPos += SIZEOF(.core2);
    __romPos = ALIGN(__romPos, 16);
    . = ALIGN(., 16);
    core2_ROM_END = __romPos;
    core2_VRAM_END = .;

    CC_ROM_START = __romPos;
    CC_VRAM = ADDR(.CC);
    .CC core2_VRAM_END : AT(CC_ROM_START) SUBALIGN(16)
    {
        FILL(0x00000000);
        CC_TEXT_START = .;
        build/us.v10/src/CC/ch/clankerscrew.c.o(.text);
        build/us.v10/src/CC/ch/clankerkey.c.o(.text);
        build/us.v10/src/CC/ch/clankertoothext.c.o(.text);
        build/us.v10/src/CC/ch/tooth.c.o(.text);
        build/us.v10/src/CC/code_13C0.c.o(.text);
        build/us.v10/src/CC/ccspawnqueue.c.o(.text);
        build/us.v10/src/CC/ma/clankerrings.c.o(.text);
        build/us.v10/src/CC/ma/clanker.c.o(.text);
        build/us.v10/src/CC/ch/sawblade.c.o(.text);
        build/us.v10/src/CC/ch/ccgrates.c.o(.text);
        . = ALIGN(., 16);
        CC_TEXT_END = .;
        CC_TEXT_SIZE = ABSOLUTE(CC_TEXT_END - CC_TEXT_START);
        CC_DATA_START = .;
        build/us.v10/src/CC/ch/clankerscrew.c.o(.data);
        build/us.v10/src/CC/ch/clankerkey.c.o(.data);
        build/us.v10/src/CC/ch/clankertoothext.c.o(.data);
        build/us.v10/src/CC/ch/tooth.c.o(.data);
        build/us.v10/src/CC/code_13C0.c.o(.data);
        build/us.v10/src/CC/ccspawnqueue.c.o(.data);
        build/us.v10/src/CC/crc.c.o(.data);
        build/us.v10/src/CC/ma/clankerrings.c.o(.data);
        build/us.v10/src/CC/ma/clanker.c.o(.data);
        build/us.v10/src/CC/ch/sawblade.c.o(.data);
        build/us.v10/src/CC/ch/ccgrates.c.o(.data);
        . = ALIGN(., 16);
        CC_DATA_END = .;
        CC_DATA_SIZE = ABSOLUTE(CC_DATA_END - CC_DATA_START);
        CC_RODATA_START = .;
        build/us.v10/src/CC/ch/clankerscrew.c.o(.rodata);
        build/us.v10/src/CC/ch/clankerkey.c.o(.rodata);
        build/us.v10/src/CC/ch/clankertoothext.c.o(.rodata);
        build/us.v10/src/CC/ch/tooth.c.o(.rodata);
        build/us.v10/src/CC/code_13C0.c.o(.rodata);
        build/us.v10/src/CC/ccspawnqueue.c.o(.rodata);
        build/us.v10/src/CC/ma/clankerrings.c.o(.rodata);
        build/us.v10/src/CC/ma/clanker.c.o(.rodata);
        build/us.v10/src/CC/ch/sawblade.c.o(.rodata);
        build/us.v10/src/CC/ch/ccgrates.c.o(.rodata);
        . = ALIGN(., 16);
        CC_RODATA_END = .;
        CC_RODATA_SIZE = ABSOLUTE(CC_RODATA_END - CC_RODATA_START);
    }
    CC_bss_VRAM = ADDR(.CC_bss);
    .CC_bss (NOLOAD) : SUBALIGN(16)
    {
        FILL(0x00000000);
        CC_BSS_START = .;
        build/us.v10/src/CC/ch/clankerscrew.c.o(.bss);
        build/us.v10/src/CC/ch/clankerkey.c.o(.bss);
        build/us.v10/src/CC/checksums.c.o(.bss);
        build/us.v10/src/CC/ch/clankertoothext.c.o(.bss);
        build/us.v10/src/CC/ch/tooth.c.o(.bss);
        build/us.v10/src/CC/code_13C0.c.o(.bss);
        build/us.v10/src/CC/ccspawnqueue.c.o(.bss);
        build/us.v10/src/CC/ma/clankerrings.c.o(.bss);
        build/us.v10/src/CC/ma/clanker.c.o(.bss);
        build/us.v10/src/CC/ch/sawblade.c.o(.bss);
        build/us.v10/src/CC/ch/ccgrates.c.o(.bss);
        . = ALIGN(., 16);
        CC_BSS_END = .;
        CC_BSS_SIZE = ABSOLUTE(CC_BSS_END - CC_BSS_START);
    }
    __romPos += SIZEOF(.CC);
    __romPos = ALIGN(__romPos, 16);
    . = ALIGN(., 16);
    CC_ROM_END = __romPos;
    CC_VRAM_END = .;

    GV_ROM_START = __romPos;
    GV_VRAM = ADDR(.GV);
    .GV core2_VRAM_END : AT(GV_ROM_START) SUBALIGN(16)
    {
        FILL(0x00000000);
        GV_TEXT_START = .;
        build/us.v10/src/GV/ch/toots.c.o(.text);
        build/us.v10/src/GV/ch/ancientone.c.o(.text);
        build/us.v10/src/GV/ch/gobi1.c.o(.text);
        build/us.v10/src/GV/ch/gobi2.c.o(.text);
        build/us.v10/src/GV/ch/gobi3.c.o(.text);
        build/us.v10/src/GV/ch/gobirope.c.o(.text);
        build/us.v10/src/GV/ch/gobirock.c.o(.text);
        build/us.v10/src/GV/ch/trunker.c.o(.text);
        build/us.v10/src/GV/magiccarpetshadow.c.o(.text);
        build/us.v10/src/GV/ch/sarcophagus.c.o(.text);
        build/us.v10/src/GV/code_3630.c.o(.text);
        build/us.v10/src/GV/ch/eggpot.c.o(.text);
        build/us.v10/src/GV/crc.c.o(.text);
        build/us.v10/src/GV/code_3BB0.c.o(.text);
        build/us.v10/src/GV/magiccarpet2.c.o(.text);
        build/us.v10/src/GV/code_43B0.c.o(.text);
        build/us.v10/src/GV/ch/slappa.c.o(.text);
        build/us.v10/src/GV/ch/grabba.c.o(.text);
        build/us.v10/src/GV/code_61E0.c.o(.text);
        build/us.v10/src/GV/code_6370.c.o(.text);
        build/us.v10/src/GV/sandybutteggtoll.c.o(.text);
        build/us.v10/src/GV/code_7060.c.o(.text);
        build/us.v10/src/GV/ch/histup.c.o(.text);
        build/us.v10/src/GV/code_7D50.c.o(.text);
        build/us.v10/src/GV/code_7DB0.c.o(.text);
        build/us.v10/src/GV/code_7FC0.c.o(.text);
        build/us.v10/src/GV/gvspawnqueue.c.o(.text);
        build/us.v10/src/GV/ch/mazectrl.c.o(.text);
        build/us.v10/src/GV/ch/buriedpyramid.c.o(.text);
        build/us.v10/src/GV/code_9B70.c.o(.text);
        build/us.v10/src/GV/code_9C10.c.o(.text);
        build/us.v10/src/GV/matchinggame.c.o(.text);
        build/us.v10/src/GV/waterctrl.c.o(.text);
        . = ALIGN(., 16);
        GV_TEXT_END = .;
        GV_TEXT_SIZE = ABSOLUTE(GV_TEXT_END - GV_TEXT_START);
        GV_DATA_START = .;
        build/us.v10/src/GV/ch/toots.c.o(.data);
        build/us.v10/src/GV/ch/ancientone.c.o(.data);
        build/us.v10/src/GV/ch/gobi1.c.o(.data);
        build/us.v10/src/GV/ch/gobi2.c.o(.data);
        build/us.v10/src/GV/ch/gobi3.c.o(.data);
        build/us.v10/src/GV/ch/gobirope.c.o(.data);
        build/us.v10/src/GV/ch/gobirock.c.o(.data);
        build/us.v10/src/GV/ch/trunker.c.o(.data);
        build/us.v10/src/GV/magiccarpetshadow.c.o(.data);
        build/us.v10/src/GV/ch/sarcophagus.c.o(.data);
        build/us.v10/src/GV/code_3630.c.o(.data);
        build/us.v10/src/GV/ch/eggpot.c.o(.data);
        build/us.v10/src/GV/crc.c.o(.data);
        build/us.v10/src/GV/code_3BB0.c.o(.data);
        build/us.v10/src/GV/magiccarpet2.c.o(.data);
        build/us.v10/src/GV/code_43B0.c.o(.data);
        build/us.v10/src/GV/ch/slappa.c.o(.data);
        build/us.v10/src/GV/ch/grabba.c.o(.data);
        build/us.v10/src/GV/code_61E0.c.o(.data);
        build/us.v10/src/GV/code_6370.c.o(.data);
        build/us.v10/src/GV/sandybutteggtoll.c.o(.data);
        build/us.v10/src/GV/code_7060.c.o(.data);
        build/us.v10/src/GV/ch/histup.c.o(.data);
        build/us.v10/src/GV/code_7D50.c.o(.data);
        build/us.v10/src/GV/code_7DB0.c.o(.data);
        build/us.v10/src/GV/code_7FC0.c.o(.data);
        build/us.v10/src/GV/gvspawnqueue.c.o(.data);
        build/us.v10/src/GV/ch/mazectrl.c.o(.data);
        build/us.v10/src/GV/ch/buriedpyramid.c.o(.data);
        build/us.v10/src/GV/code_9B70.c.o(.data);
        build/us.v10/src/GV/code_9C10.c.o(.data);
        build/us.v10/src/GV/matchinggame.c.o(.data);
        build/us.v10/src/GV/waterctrl.c.o(.data);
        . = ALIGN(., 16);
        GV_DATA_END = .;
        GV_DATA_SIZE = ABSOLUTE(GV_DATA_END - GV_DATA_START);
        GV_RODATA_START = .;
        build/us.v10/src/GV/ch/toots.c.o(.rodata);
        build/us.v10/src/GV/ch/ancientone.c.o(.rodata);
        build/us.v10/src/GV/ch/gobi1.c.o(.rodata);
        build/us.v10/src/GV/ch/gobi2.c.o(.rodata);
        build/us.v10/src/GV/ch/gobi3.c.o(.rodata);
        build/us.v10/src/GV/ch/gobirope.c.o(.rodata);
        build/us.v10/src/GV/ch/gobirock.c.o(.rodata);
        build/us.v10/src/GV/ch/trunker.c.o(.rodata);
        build/us.v10/src/GV/magiccarpetshadow.c.o(.rodata);
        build/us.v10/src/GV/ch/sarcophagus.c.o(.rodata);
        build/us.v10/src/GV/code_3630.c.o(.rodata);
        build/us.v10/src/GV/ch/eggpot.c.o(.rodata);
        build/us.v10/src/GV/crc.c.o(.rodata);
        build/us.v10/src/GV/code_3BB0.c.o(.rodata);
        build/us.v10/src/GV/magiccarpet2.c.o(.rodata);
        build/us.v10/src/GV/code_43B0.c.o(.rodata);
        build/us.v10/src/GV/ch/slappa.c.o(.rodata);
        build/us.v10/src/GV/ch/grabba.c.o(.rodata);
        build/us.v10/src/GV/code_61E0.c.o(.rodata);
        build/us.v10/src/GV/code_6370.c.o(.rodata);
        build/us.v10/src/GV/sandybutteggtoll.c.o(.rodata);
        build/us.v10/src/GV/code_7060.c.o(.rodata);
        build/us.v10/src/GV/ch/histup.c.o(.rodata);
        build/us.v10/src/GV/code_7D50.c.o(.rodata);
        build/us.v10/src/GV/code_7DB0.c.o(.rodata);
        build/us.v10/src/GV/code_7FC0.c.o(.rodata);
        build/us.v10/src/GV/gvspawnqueue.c.o(.rodata);
        build/us.v10/src/GV/ch/mazectrl.c.o(.rodata);
        build/us.v10/src/GV/ch/buriedpyramid.c.o(.rodata);
        build/us.v10/src/GV/code_9B70.c.o(.rodata);
        build/us.v10/src/GV/code_9C10.c.o(.rodata);
        build/us.v10/src/GV/matchinggame.c.o(.rodata);
        build/us.v10/src/GV/waterctrl.c.o(.rodata);
        . = ALIGN(., 16);
        GV_RODATA_END = .;
        GV_RODATA_SIZE = ABSOLUTE(GV_RODATA_END - GV_RODATA_START);
    }
    GV_bss_VRAM = ADDR(.GV_bss);
    .GV_bss (NOLOAD) : SUBALIGN(16)
    {
        FILL(0x00000000);
        GV_BSS_START = .;
        build/us.v10/src/GV/checksums.c.o(.bss);
        build/us.v10/src/GV/ch/toots.c.o(.bss);
        build/us.v10/src/GV/ch/ancientone.c.o(.bss);
        build/us.v10/src/GV/ch/gobi1.c.o(.bss);
        build/us.v10/src/GV/ch/gobi2.c.o(.bss);
        build/us.v10/src/GV/ch/gobi3.c.o(.bss);
        build/us.v10/src/GV/ch/gobirope.c.o(.bss);
        build/us.v10/src/GV/ch/gobirock.c.o(.bss);
        build/us.v10/src/GV/ch/trunker.c.o(.bss);
        build/us.v10/src/GV/magiccarpetshadow.c.o(.bss);
        build/us.v10/src/GV/ch/sarcophagus.c.o(.bss);
        build/us.v10/src/GV/code_3630.c.o(.bss);
        build/us.v10/src/GV/ch/eggpot.c.o(.bss);
        build/us.v10/src/GV/crc.c.o(.bss);
        build/us.v10/src/GV/code_3BB0.c.o(.bss);
        build/us.v10/src/GV/magiccarpet2.c.o(.bss);
        build/us.v10/src/GV/code_43B0.c.o(.bss);
        build/us.v10/src/GV/ch/slappa.c.o(.bss);
        build/us.v10/src/GV/ch/grabba.c.o(.bss);
        build/us.v10/src/GV/code_61E0.c.o(.bss);
        build/us.v10/src/GV/code_6370.c.o(.bss);
        build/us.v10/src/GV/sandybutteggtoll.c.o(.bss);
        build/us.v10/src/GV/code_7060.c.o(.bss);
        build/us.v10/src/GV/ch/histup.c.o(.bss);
        build/us.v10/src/GV/code_7D50.c.o(.bss);
        build/us.v10/src/GV/code_7DB0.c.o(.bss);
        build/us.v10/src/GV/code_7FC0.c.o(.bss);
        build/us.v10/src/GV/gvspawnqueue.c.o(.bss);
        build/us.v10/src/GV/ch/mazectrl.c.o(.bss);
        build/us.v10/src/GV/ch/buriedpyramid.c.o(.bss);
        build/us.v10/src/GV/code_9B70.c.o(.bss);
        build/us.v10/src/GV/code_9C10.c.o(.bss);
        build/us.v10/src/GV/matchinggame.c.o(.bss);
        build/us.v10/src/GV/waterctrl.c.o(.bss);
        . = ALIGN(., 16);
        GV_BSS_END = .;
        GV_BSS_SIZE = ABSOLUTE(GV_BSS_END - GV_BSS_START);
    }
    __romPos += SIZEOF(.GV);
    __romPos = ALIGN(__romPos, 16);
    . = ALIGN(., 16);
    GV_ROM_END = __romPos;
    GV_VRAM_END = .;

    MMM_ROM_START = __romPos;
    MMM_VRAM = ADDR(.MMM);
    .MMM core2_VRAM_END : AT(MMM_ROM_START) SUBALIGN(16)
    {
        FILL(0x00000000);
        MMM_TEXT_START = .;
        build/us.v10/src/MMM/ch/loggo.c.o(.text);
        build/us.v10/src/MMM/ch/napper.c.o(.text);
        build/us.v10/src/MMM/ch/cemetarypot.c.o(.text);
        build/us.v10/src/MMM/ch/motzhand.c.o(.text);
        build/us.v10/src/MMM/ch/portraitchompa.c.o(.text);
        build/us.v10/src/MMM/mmmspawnqueue.c.o(.text);
        build/us.v10/src/MMM/ch/portrait.c.o(.text);
        build/us.v10/src/MMM/code_3120.c.o(.text);
        build/us.v10/src/MMM/code_3420.c.o(.text);
        build/us.v10/src/MMM/crc.c.o(.text);
        build/us.v10/src/MMM/code_3D50.c.o(.text);
        build/us.v10/src/MMM/ch/tumblar.c.o(.text);
        build/us.v10/src/MMM/code_5000.c.o(.text);
        . = ALIGN(., 16);
        MMM_TEXT_END = .;
        MMM_TEXT_SIZE = ABSOLUTE(MMM_TEXT_END - MMM_TEXT_START);
        MMM_DATA_START = .;
        build/us.v10/src/MMM/ch/loggo.c.o(.data);
        build/us.v10/src/MMM/ch/napper.c.o(.data);
        build/us.v10/src/MMM/ch/cemetarypot.c.o(.data);
        build/us.v10/src/MMM/ch/motzhand.c.o(.data);
        build/us.v10/src/MMM/ch/portraitchompa.c.o(.data);
        build/us.v10/src/MMM/mmmspawnqueue.c.o(.data);
        build/us.v10/src/MMM/ch/portrait.c.o(.data);
        build/us.v10/src/MMM/code_3120.c.o(.data);
        build/us.v10/src/MMM/code_3420.c.o(.data);
        build/us.v10/src/MMM/code_3D50.c.o(.data);
        build/us.v10/src/MMM/ch/tumblar.c.o(.data);
        build/us.v10/src/MMM/crc.c.o(.data);
        build/us.v10/src/MMM/code_5000.c.o(.data);
        . = ALIGN(., 16);
        MMM_DATA_END = .;
        MMM_DATA_SIZE = ABSOLUTE(MMM_DATA_END - MMM_DATA_START);
        MMM_RODATA_START = .;
        build/us.v10/src/MMM/ch/loggo.c.o(.rodata);
        build/us.v10/src/MMM/ch/napper.c.o(.rodata);
        build/us.v10/src/MMM/ch/cemetarypot.c.o(.rodata);
        build/us.v10/src/MMM/ch/motzhand.c.o(.rodata);
        build/us.v10/src/MMM/ch/portraitchompa.c.o(.rodata);
        build/us.v10/src/MMM/mmmspawnqueue.c.o(.rodata);
        build/us.v10/src/MMM/ch/portrait.c.o(.rodata);
        build/us.v10/src/MMM/code_3120.c.o(.rodata);
        build/us.v10/src/MMM/code_3420.c.o(.rodata);
        build/us.v10/src/MMM/crc.c.o(.rodata);
        build/us.v10/src/MMM/code_3D50.c.o(.rodata);
        build/us.v10/src/MMM/ch/tumblar.c.o(.rodata);
        build/us.v10/src/MMM/code_5000.c.o(.rodata);
        . = ALIGN(., 16);
        MMM_RODATA_END = .;
        MMM_RODATA_SIZE = ABSOLUTE(MMM_RODATA_END - MMM_RODATA_START);
    }
    MMM_bss_VRAM = ADDR(.MMM_bss);
    .MMM_bss (NOLOAD) : SUBALIGN(16)
    {
        FILL(0x00000000);
        MMM_BSS_START = .;
        build/us.v10/src/MMM/ch/loggo.c.o(.bss);
        build/us.v10/src/MMM/ch/napper.c.o(.bss);
        build/us.v10/src/MMM/ch/cemetarypot.c.o(.bss);
        build/us.v10/src/MMM/ch/motzhand.c.o(.bss);
        build/us.v10/src/MMM/ch/portraitchompa.c.o(.bss);
        build/us.v10/src/MMM/checksums.c.o(.bss);
        build/us.v10/src/MMM/mmmspawnqueue.c.o(.bss);
        build/us.v10/src/MMM/ch/portrait.c.o(.bss);
        build/us.v10/src/MMM/code_3120.c.o(.bss);
        build/us.v10/src/MMM/code_3420.c.o(.bss);
        build/us.v10/src/MMM/crc.c.o(.bss);
        build/us.v10/src/MMM/code_3D50.c.o(.bss);
        build/us.v10/src/MMM/ch/tumblar.c.o(.bss);
        build/us.v10/src/MMM/code_5000.c.o(.bss);
        . = ALIGN(., 16);
        MMM_BSS_END = .;
        MMM_BSS_SIZE = ABSOLUTE(MMM_BSS_END - MMM_BSS_START);
    }
    __romPos += SIZEOF(.MMM);
    __romPos = ALIGN(__romPos, 16);
    . = ALIGN(., 16);
    MMM_ROM_END = __romPos;
    MMM_VRAM_END = .;

    TTC_ROM_START = __romPos;
    TTC_VRAM = ADDR(.TTC);
    .TTC core2_VRAM_END : AT(TTC_ROM_START) SUBALIGN(16)
    {
        FILL(0x00000000);
        TTC_TEXT_START = .;
        build/us.v10/src/TTC/ch/clam.c.o(.text);
        build/us.v10/src/TTC/ch/blubber.c.o(.text);
        build/us.v10/src/TTC/ch/nipper.c.o(.text);
        build/us.v10/src/TTC/code_26D0.c.o(.text);
        build/us.v10/src/TTC/ch/leaky.c.o(.text);
        build/us.v10/src/TTC/code_3040.c.o(.text);
        build/us.v10/src/TTC/ch/lockup.c.o(.text);
        build/us.v10/src/TTC/ch/treasurehunt.c.o(.text);
        build/us.v10/src/TTC/ma/castle.c.o(.text);
        build/us.v10/src/TTC/ch/treasure.c.o(.text);
        . = ALIGN(., 16);
        TTC_TEXT_END = .;
        TTC_TEXT_SIZE = ABSOLUTE(TTC_TEXT_END - TTC_TEXT_START);
        TTC_DATA_START = .;
        build/us.v10/src/TTC/ch/clam.c.o(.data);
        build/us.v10/src/TTC/ch/blubber.c.o(.data);
        build/us.v10/src/TTC/ch/nipper.c.o(.data);
        build/us.v10/src/TTC/code_26D0.c.o(.data);
        build/us.v10/src/TTC/ch/leaky.c.o(.data);
        build/us.v10/src/TTC/code_3040.c.o(.data);
        build/us.v10/src/TTC/ch/lockup.c.o(.data);
        build/us.v10/src/TTC/ch/treasurehunt.c.o(.data);
        build/us.v10/src/TTC/ma/castle.c.o(.data);
        build/us.v10/src/TTC/ch/treasure.c.o(.data);
        . = ALIGN(., 16);
        TTC_DATA_END = .;
        TTC_DATA_SIZE = ABSOLUTE(TTC_DATA_END - TTC_DATA_START);
        TTC_RODATA_START = .;
        build/us.v10/src/TTC/ch/clam.c.o(.rodata);
        build/us.v10/src/TTC/ch/blubber.c.o(.rodata);
        build/us.v10/src/TTC/ch/nipper.c.o(.rodata);
        build/us.v10/src/TTC/code_26D0.c.o(.rodata);
        build/us.v10/src/TTC/ch/leaky.c.o(.rodata);
        build/us.v10/src/TTC/code_3040.c.o(.rodata);
        build/us.v10/src/TTC/ch/lockup.c.o(.rodata);
        build/us.v10/src/TTC/ch/treasurehunt.c.o(.rodata);
        build/us.v10/src/TTC/ma/castle.c.o(.rodata);
        build/us.v10/src/TTC/ch/treasure.c.o(.rodata);
        . = ALIGN(., 16);
        TTC_RODATA_END = .;
        TTC_RODATA_SIZE = ABSOLUTE(TTC_RODATA_END - TTC_RODATA_START);
    }
    TTC_bss_VRAM = ADDR(.TTC_bss);
    .TTC_bss (NOLOAD) : SUBALIGN(16)
    {
        FILL(0x00000000);
        TTC_BSS_START = .;
        build/us.v10/src/TTC/ch/clam.c.o(.bss);
        build/us.v10/src/TTC/ch/blubber.c.o(.bss);
        build/us.v10/src/TTC/ch/nipper.c.o(.bss);
        build/us.v10/src/TTC/code_26D0.c.o(.bss);
        build/us.v10/src/TTC/ch/leaky.c.o(.bss);
        build/us.v10/src/TTC/checksums.c.o(.bss);
        build/us.v10/src/TTC/code_3040.c.o(.bss);
        build/us.v10/src/TTC/ch/lockup.c.o(.bss);
        build/us.v10/src/TTC/ch/treasurehunt.c.o(.bss);
        build/us.v10/src/TTC/ma/castle.c.o(.bss);
        build/us.v10/src/TTC/ch/treasure.c.o(.bss);
        . = ALIGN(., 16);
        TTC_BSS_END = .;
        TTC_BSS_SIZE = ABSOLUTE(TTC_BSS_END - TTC_BSS_START);
    }
    __romPos += SIZEOF(.TTC);
    __romPos = ALIGN(__romPos, 16);
    . = ALIGN(., 16);
    TTC_ROM_END = __romPos;
    TTC_VRAM_END = .;

    MM_ROM_START = __romPos;
    MM_VRAM = ADDR(.MM);
    .MM core2_VRAM_END : AT(MM_ROM_START) SUBALIGN(16)
    {
        FILL(0x00000000);
        MM_TEXT_START = .;
        build/us.v10/src/MM/ch/orangepad.c.o(.text);
        build/us.v10/src/MM/ch/hut.c.o(.text);
        build/us.v10/src/MM/ch/chimpystump.c.o(.text);
        build/us.v10/src/MM/ch/conga.c.o(.text);
        build/us.v10/src/MM/crc.c.o(.text);
        build/us.v10/src/MM/ch/orange.c.o(.text);
        build/us.v10/src/MM/ch/lmonkey.c.o(.text);
        build/us.v10/src/MM/mmspawnqueue.c.o(.text);
        build/us.v10/src/MM/ch/grublin.c.o(.text);
        build/us.v10/src/MM/ch/jujuhitbox.c.o(.text);
        build/us.v10/src/MM/ch/juju.c.o(.text);
        . = ALIGN(., 16);
        MM_TEXT_END = .;
        MM_TEXT_SIZE = ABSOLUTE(MM_TEXT_END - MM_TEXT_START);
        MM_DATA_START = .;
        build/us.v10/src/MM/ch/orangepad.c.o(.data);
        build/us.v10/src/MM/ch/hut.c.o(.data);
        build/us.v10/src/MM/ch/chimpystump.c.o(.data);
        build/us.v10/src/MM/ch/conga.c.o(.data);
        build/us.v10/src/MM/crc.c.o(.data);
        build/us.v10/src/MM/ch/orange.c.o(.data);
        build/us.v10/src/MM/ch/lmonkey.c.o(.data);
        build/us.v10/src/MM/mmspawnqueue.c.o(.data);
        build/us.v10/src/MM/ch/grublin.c.o(.data);
        build/us.v10/src/MM/ch/jujuhitbox.c.o(.data);
        build/us.v10/src/MM/ch/juju.c.o(.data);
        . = ALIGN(., 16);
        MM_DATA_END = .;
        MM_DATA_SIZE = ABSOLUTE(MM_DATA_END - MM_DATA_START);
        MM_RODATA_START = .;
        build/us.v10/src/MM/ch/orangepad.c.o(.rodata);
        build/us.v10/src/MM/ch/hut.c.o(.rodata);
        build/us.v10/src/MM/ch/chimpystump.c.o(.rodata);
        build/us.v10/src/MM/ch/conga.c.o(.rodata);
        build/us.v10/src/MM/crc.c.o(.rodata);
        build/us.v10/src/MM/ch/orange.c.o(.rodata);
        build/us.v10/src/MM/ch/lmonkey.c.o(.rodata);
        build/us.v10/src/MM/mmspawnqueue.c.o(.rodata);
        build/us.v10/src/MM/ch/grublin.c.o(.rodata);
        build/us.v10/src/MM/ch/jujuhitbox.c.o(.rodata);
        build/us.v10/src/MM/ch/juju.c.o(.rodata);
        . = ALIGN(., 16);
        MM_RODATA_END = .;
        MM_RODATA_SIZE = ABSOLUTE(MM_RODATA_END - MM_RODATA_START);
    }
    MM_bss_VRAM = ADDR(.MM_bss);
    .MM_bss (NOLOAD) : SUBALIGN(16)
    {
        FILL(0x00000000);
        MM_BSS_START = .;
        build/us.v10/src/MM/ch/orangepad.c.o(.bss);
        build/us.v10/src/MM/checksums.c.o(.bss);
        build/us.v10/src/MM/ch/hut.c.o(.bss);
        build/us.v10/src/MM/ch/chimpystump.c.o(.bss);
        build/us.v10/src/MM/ch/conga.c.o(.bss);
        build/us.v10/src/MM/crc.c.o(.bss);
        build/us.v10/src/MM/ch/orange.c.o(.bss);
        build/us.v10/src/MM/ch/lmonkey.c.o(.bss);
        build/us.v10/src/MM/mmspawnqueue.c.o(.bss);
        build/us.v10/src/MM/ch/grublin.c.o(.bss);
        build/us.v10/src/MM/ch/jujuhitbox.c.o(.bss);
        build/us.v10/src/MM/ch/juju.c.o(.bss);
        . = ALIGN(., 16);
        MM_BSS_END = .;
        MM_BSS_SIZE = ABSOLUTE(MM_BSS_END - MM_BSS_START);
    }
    __romPos += SIZEOF(.MM);
    __romPos = ALIGN(__romPos, 16);
    . = ALIGN(., 16);
    MM_ROM_END = __romPos;
    MM_VRAM_END = .;

    BGS_ROM_START = __romPos;
    BGS_VRAM = ADDR(.BGS);
    .BGS core2_VRAM_END : AT(BGS_ROM_START) SUBALIGN(16)
    {
        FILL(0x00000000);
        BGS_TEXT_START = .;
        build/us.v10/src/BGS/ch/flibbit.c.o(.text);
        build/us.v10/src/BGS/ch/pinkegg.c.o(.text);
        build/us.v10/src/BGS/ch/croctus.c.o(.text);
        build/us.v10/src/BGS/ch/tiptup.c.o(.text);
        build/us.v10/src/BGS/ch/choirturtle.c.o(.text);
        build/us.v10/src/BGS/mrvileminigame.c.o(.text);
        build/us.v10/src/BGS/ch/yumblie.c.o(.text);
        build/us.v10/src/BGS/ch/mrvile.c.o(.text);
        build/us.v10/src/BGS/ch/frogminigame.c.o(.text);
        build/us.v10/src/BGS/ch/yellowflibbit.c.o(.text);
        build/us.v10/src/BGS/ch/mudhut.c.o(.text);
        build/us.v10/src/BGS/ch/swampswitch.c.o(.text);
        build/us.v10/src/BGS/bgsspawnqueue.c.o(.text);
        build/us.v10/src/BGS/ch/tanktup.c.o(.text);
        build/us.v10/src/BGS/ch/tanktuplegs.c.o(.text);
        build/us.v10/src/BGS/ch/bigalligator.c.o(.text);
        build/us.v10/src/BGS/ch/leafboat.c.o(.text);
        . = ALIGN(., 16);
        BGS_TEXT_END = .;
        BGS_TEXT_SIZE = ABSOLUTE(BGS_TEXT_END - BGS_TEXT_START);
        BGS_DATA_START = .;
        build/us.v10/src/BGS/ch/flibbit.c.o(.data);
        build/us.v10/src/BGS/ch/pinkegg.c.o(.data);
        build/us.v10/src/BGS/ch/croctus.c.o(.data);
        build/us.v10/src/BGS/ch/tiptup.c.o(.data);
        build/us.v10/src/BGS/ch/choirturtle.c.o(.data);
        build/us.v10/src/BGS/mrvileminigame.c.o(.data);
        build/us.v10/src/BGS/ch/yumblie.c.o(.data);
        build/us.v10/src/BGS/ch/mrvile.c.o(.data);
        build/us.v10/src/BGS/ch/frogminigame.c.o(.data);
        build/us.v10/src/BGS/ch/yellowflibbit.c.o(.data);
        build/us.v10/src/BGS/crc.c.o(.data);
        build/us.v10/src/BGS/ch/mudhut.c.o(.data);
        build/us.v10/src/BGS/ch/swampswitch.c.o(.data);
        build/us.v10/src/BGS/bgsspawnqueue.c.o(.data);
        build/us.v10/src/BGS/ch/tanktup.c.o(.data);
        build/us.v10/src/BGS/ch/tanktuplegs.c.o(.data);
        build/us.v10/src/BGS/ch/bigalligator.c.o(.data);
        build/us.v10/src/BGS/ch/leafboat.c.o(.data);
        . = ALIGN(., 16);
        BGS_DATA_END = .;
        BGS_DATA_SIZE = ABSOLUTE(BGS_DATA_END - BGS_DATA_START);
        BGS_RODATA_START = .;
        build/us.v10/src/BGS/ch/flibbit.c.o(.rodata);
        build/us.v10/src/BGS/ch/pinkegg.c.o(.rodata);
        build/us.v10/src/BGS/ch/croctus.c.o(.rodata);
        build/us.v10/src/BGS/ch/tiptup.c.o(.rodata);
        build/us.v10/src/BGS/ch/choirturtle.c.o(.rodata);
        build/us.v10/src/BGS/mrvileminigame.c.o(.rodata);
        build/us.v10/src/BGS/ch/yumblie.c.o(.rodata);
        build/us.v10/src/BGS/ch/mrvile.c.o(.rodata);
        build/us.v10/src/BGS/ch/frogminigame.c.o(.rodata);
        build/us.v10/src/BGS/ch/yellowflibbit.c.o(.rodata);
        build/us.v10/src/BGS/ch/mudhut.c.o(.rodata);
        build/us.v10/src/BGS/ch/swampswitch.c.o(.rodata);
        build/us.v10/src/BGS/bgsspawnqueue.c.o(.rodata);
        build/us.v10/src/BGS/ch/tanktup.c.o(.rodata);
        build/us.v10/src/BGS/ch/tanktuplegs.c.o(.rodata);
        build/us.v10/src/BGS/ch/bigalligator.c.o(.rodata);
        build/us.v10/src/BGS/ch/leafboat.c.o(.rodata);
        . = ALIGN(., 16);
        BGS_RODATA_END = .;
        BGS_RODATA_SIZE = ABSOLUTE(BGS_RODATA_END - BGS_RODATA_START);
    }
    BGS_bss_VRAM = ADDR(.BGS_bss);
    .BGS_bss (NOLOAD) : SUBALIGN(16)
    {
        FILL(0x00000000);
        BGS_BSS_START = .;
        build/us.v10/src/BGS/ch/flibbit.c.o(.bss);
        build/us.v10/src/BGS/ch/pinkegg.c.o(.bss);
        build/us.v10/src/BGS/ch/croctus.c.o(.bss);
        build/us.v10/src/BGS/ch/tiptup.c.o(.bss);
        build/us.v10/src/BGS/ch/choirturtle.c.o(.bss);
        build/us.v10/src/BGS/mrvileminigame.c.o(.bss);
        build/us.v10/src/BGS/ch/yumblie.c.o(.bss);
        build/us.v10/src/BGS/ch/mrvile.c.o(.bss);
        build/us.v10/src/BGS/checksums.c.o(.bss);
        build/us.v10/src/BGS/ch/frogminigame.c.o(.bss);
        build/us.v10/src/BGS/ch/yellowflibbit.c.o(.bss);
        build/us.v10/src/BGS/ch/mudhut.c.o(.bss);
        build/us.v10/src/BGS/ch/swampswitch.c.o(.bss);
        build/us.v10/src/BGS/bgsspawnqueue.c.o(.bss);
        build/us.v10/src/BGS/ch/tanktup.c.o(.bss);
        build/us.v10/src/BGS/ch/tanktuplegs.c.o(.bss);
        build/us.v10/src/BGS/ch/bigalligator.c.o(.bss);
        build/us.v10/src/BGS/ch/leafboat.c.o(.bss);
        . = ALIGN(., 16);
        BGS_BSS_END = .;
        BGS_BSS_SIZE = ABSOLUTE(BGS_BSS_END - BGS_BSS_START);
    }
    __romPos += SIZEOF(.BGS);
    __romPos = ALIGN(__romPos, 16);
    . = ALIGN(., 16);
    BGS_ROM_END = __romPos;
    BGS_VRAM_END = .;

    RBB_ROM_START = __romPos;
    RBB_VRAM = ADDR(.RBB);
    .RBB core2_VRAM_END : AT(RBB_ROM_START) SUBALIGN(16)
    {
        FILL(0x00000000);
        RBB_TEXT_START = .;
        build/us.v10/src/RBB/ch/eggtoll1.c.o(.text);
        build/us.v10/src/RBB/rbbspawnqueue.c.o(.text);
        build/us.v10/src/RBB/code_CA0.c.o(.text);
        build/us.v10/src/RBB/code_1570.c.o(.text);
        build/us.v10/src/RBB/ch/grimlet.c.o(.text);
        build/us.v10/src/RBB/ch/cog.c.o(.text);
        build/us.v10/src/RBB/ch/axle.c.o(.text);
        build/us.v10/src/RBB/ch/enginefan.c.o(.text);
        build/us.v10/src/RBB/ch/enginefanswitch.c.o(.text);
        build/us.v10/src/RBB/ch/propellor.c.o(.text);
        build/us.v10/src/RBB/ch/propellorswitch.c.o(.text);
        build/us.v10/src/RBB/ch/engineparts.c.o(.text);
        build/us.v10/src/RBB/ch/whistleswitch.c.o(.text);
        build/us.v10/src/RBB/ch/whistle.c.o(.text);
        build/us.v10/src/RBB/ch/whistlectrl.c.o(.text);
        build/us.v10/src/RBB/ch/anchorswitch.c.o(.text);
        build/us.v10/src/RBB/ch/dolphin.c.o(.text);
        build/us.v10/src/RBB/ch/anchor.c.o(.text);
        build/us.v10/src/RBB/ch/anchorctrl.c.o(.text);
        build/us.v10/src/RBB/ch/rarewareflag.c.o(.text);
        build/us.v10/src/RBB/ch/bossboombox.c.o(.text);
        build/us.v10/src/RBB/ch/bossboomboxctrl.c.o(.text);
        build/us.v10/src/RBB/ch/bellbuoy.c.o(.text);
        build/us.v10/src/RBB/ch/rowboat.c.o(.text);
        build/us.v10/src/RBB/ch/boombox.c.o(.text);
        build/us.v10/src/RBB/code_9670.c.o(.text);
        build/us.v10/src/RBB/code_9840.c.o(.text);
        build/us.v10/src/RBB/propellorctrl.c.o(.text);
        . = ALIGN(., 16);
        RBB_TEXT_END = .;
        RBB_TEXT_SIZE = ABSOLUTE(RBB_TEXT_END - RBB_TEXT_START);
        RBB_DATA_START = .;
        build/us.v10/src/RBB/ch/eggtoll1.c.o(.data);
        build/us.v10/src/RBB/rbbspawnqueue.c.o(.data);
        build/us.v10/src/RBB/code_CA0.c.o(.data);
        build/us.v10/src/RBB/code_1570.c.o(.data);
        build/us.v10/src/RBB/ch/grimlet.c.o(.data);
        build/us.v10/src/RBB/ch/cog.c.o(.data);
        build/us.v10/src/RBB/ch/axle.c.o(.data);
        build/us.v10/src/RBB/ch/enginefan.c.o(.data);
        build/us.v10/src/RBB/ch/enginefanswitch.c.o(.data);
        build/us.v10/src/RBB/ch/propellor.c.o(.data);
        build/us.v10/src/RBB/ch/propellorswitch.c.o(.data);
        build/us.v10/src/RBB/ch/engineparts.c.o(.data);
        build/us.v10/src/RBB/ch/whistleswitch.c.o(.data);
        build/us.v10/src/RBB/ch/whistle.c.o(.data);
        build/us.v10/src/RBB/ch/whistlectrl.c.o(.data);
        build/us.v10/src/RBB/ch/anchorswitch.c.o(.data);
        build/us.v10/src/RBB/ch/dolphin.c.o(.data);
        build/us.v10/src/RBB/ch/anchor.c.o(.data);
        build/us.v10/src/RBB/ch/anchorctrl.c.o(.data);
        build/us.v10/src/RBB/ch/rarewareflag.c.o(.data);
        build/us.v10/src/RBB/ch/bossboombox.c.o(.data);
        build/us.v10/src/RBB/ch/bossboomboxctrl.c.o(.data);
        build/us.v10/src/RBB/ch/bellbuoy.c.o(.data);
        build/us.v10/src/RBB/ch/rowboat.c.o(.data);
        build/us.v10/src/RBB/ch/boombox.c.o(.data);
        build/us.v10/src/RBB/code_9670.c.o(.data);
        build/us.v10/src/RBB/code_9840.c.o(.data);
        build/us.v10/src/RBB/propellorctrl.c.o(.data);
        . = ALIGN(., 16);
        RBB_DATA_END = .;
        RBB_DATA_SIZE = ABSOLUTE(RBB_DATA_END - RBB_DATA_START);
        RBB_RODATA_START = .;
        build/us.v10/src/RBB/ch/eggtoll1.c.o(.rodata);
        build/us.v10/src/RBB/rbbspawnqueue.c.o(.rodata);
        build/us.v10/src/RBB/code_CA0.c.o(.rodata);
        build/us.v10/src/RBB/code_1570.c.o(.rodata);
        build/us.v10/src/RBB/ch/grimlet.c.o(.rodata);
        build/us.v10/src/RBB/ch/cog.c.o(.rodata);
        build/us.v10/src/RBB/ch/axle.c.o(.rodata);
        build/us.v10/src/RBB/ch/enginefan.c.o(.rodata);
        build/us.v10/src/RBB/ch/enginefanswitch.c.o(.rodata);
        build/us.v10/src/RBB/ch/propellor.c.o(.rodata);
        build/us.v10/src/RBB/ch/propellorswitch.c.o(.rodata);
        build/us.v10/src/RBB/ch/engineparts.c.o(.rodata);
        build/us.v10/src/RBB/ch/whistleswitch.c.o(.rodata);
        build/us.v10/src/RBB/ch/whistle.c.o(.rodata);
        build/us.v10/src/RBB/ch/whistlectrl.c.o(.rodata);
        build/us.v10/src/RBB/ch/anchorswitch.c.o(.rodata);
        build/us.v10/src/RBB/ch/dolphin.c.o(.rodata);
        build/us.v10/src/RBB/ch/anchor.c.o(.rodata);
        build/us.v10/src/RBB/ch/anchorctrl.c.o(.rodata);
        build/us.v10/src/RBB/ch/rarewareflag.c.o(.rodata);
        build/us.v10/src/RBB/ch/bossboombox.c.o(.rodata);
        build/us.v10/src/RBB/ch/bossboomboxctrl.c.o(.rodata);
        build/us.v10/src/RBB/ch/bellbuoy.c.o(.rodata);
        build/us.v10/src/RBB/ch/rowboat.c.o(.rodata);
        build/us.v10/src/RBB/ch/boombox.c.o(.rodata);
        build/us.v10/src/RBB/code_9670.c.o(.rodata);
        build/us.v10/src/RBB/code_9840.c.o(.rodata);
        build/us.v10/src/RBB/propellorctrl.c.o(.rodata);
        . = ALIGN(., 16);
        RBB_RODATA_END = .;
        RBB_RODATA_SIZE = ABSOLUTE(RBB_RODATA_END - RBB_RODATA_START);
    }
    RBB_bss_VRAM = ADDR(.RBB_bss);
    .RBB_bss (NOLOAD) : SUBALIGN(16)
    {
        FILL(0x00000000);
        RBB_BSS_START = .;
        build/us.v10/src/RBB/ch/eggtoll1.c.o(.bss);
        build/us.v10/src/RBB/rbbspawnqueue.c.o(.bss);
        build/us.v10/src/RBB/code_CA0.c.o(.bss);
        build/us.v10/src/RBB/code_1570.c.o(.bss);
        build/us.v10/src/RBB/ch/grimlet.c.o(.bss);
        build/us.v10/src/RBB/ch/cog.c.o(.bss);
        build/us.v10/src/RBB/ch/axle.c.o(.bss);
        build/us.v10/src/RBB/ch/enginefan.c.o(.bss);
        build/us.v10/src/RBB/ch/enginefanswitch.c.o(.bss);
        build/us.v10/src/RBB/ch/propellor.c.o(.bss);
        build/us.v10/src/RBB/ch/propellorswitch.c.o(.bss);
        build/us.v10/src/RBB/ch/engineparts.c.o(.bss);
        build/us.v10/src/RBB/ch/whistleswitch.c.o(.bss);
        build/us.v10/src/RBB/ch/whistle.c.o(.bss);
        build/us.v10/src/RBB/ch/whistlectrl.c.o(.bss);
        build/us.v10/src/RBB/ch/anchorswitch.c.o(.bss);
        build/us.v10/src/RBB/ch/dolphin.c.o(.bss);
        build/us.v10/src/RBB/ch/anchor.c.o(.bss);
        build/us.v10/src/RBB/ch/anchorctrl.c.o(.bss);
        build/us.v10/src/RBB/ch/rarewareflag.c.o(.bss);
        build/us.v10/src/RBB/checksums.c.o(.bss);
        build/us.v10/src/RBB/ch/bossboombox.c.o(.bss);
        build/us.v10/src/RBB/ch/bossboomboxctrl.c.o(.bss);
        build/us.v10/src/RBB/ch/bellbuoy.c.o(.bss);
        build/us.v10/src/RBB/ch/rowboat.c.o(.bss);
        build/us.v10/src/RBB/ch/boombox.c.o(.bss);
        build/us.v10/src/RBB/ch/boombox.c.o(.bss);
        build/us.v10/src/RBB/code_9670.c.o(.bss);
        build/us.v10/src/RBB/code_9840.c.o(.bss);
        build/us.v10/src/RBB/propellorctrl.c.o(.bss);
        . = ALIGN(., 16);
        RBB_BSS_END = .;
        RBB_BSS_SIZE = ABSOLUTE(RBB_BSS_END - RBB_BSS_START);
    }
    __romPos += SIZEOF(.RBB);
    __romPos = ALIGN(__romPos, 16);
    . = ALIGN(., 16);
    RBB_ROM_END = __romPos;
    RBB_VRAM_END = .;

    FP_ROM_START = __romPos;
    FP_VRAM = ADDR(.FP);
    .FP core2_VRAM_END : AT(FP_ROM_START) SUBALIGN(16)
    {
        FILL(0x00000000);
        FP_TEXT_START = .;
        build/us.v10/src/FP/ch/scarfsled.c.o(.text);
        build/us.v10/src/FP/ch/racesled.c.o(.text);
        build/us.v10/src/FP/ch/snowmanbutton.c.o(.text);
        build/us.v10/src/FP/ch/xmastree.c.o(.text);
        build/us.v10/src/FP/ch/boggy1.c.o(.text);
        build/us.v10/src/FP/ch/boggyraceflag1.c.o(.text);
        build/us.v10/src/FP/ch/boggyraceflag2.c.o(.text);
        build/us.v10/src/FP/ch/boggy2.c.o(.text);
        build/us.v10/src/FP/ch/bearcub.c.o(.text);
        build/us.v10/src/FP/ma/snowy.c.o(.text);
        build/us.v10/src/FP/ma/snowbutton.c.o(.text);
        build/us.v10/src/FP/ma/slalom.c.o(.text);
        build/us.v10/src/FP/ch/twinkly.c.o(.text);
        build/us.v10/src/FP/ch/twinklybox.c.o(.text);
        build/us.v10/src/FP/ch/twinklymuncher.c.o(.text);
        build/us.v10/src/FP/ch/xmastreeswitch.c.o(.text);
        build/us.v10/src/FP/ch/xmastreestar.c.o(.text);
        build/us.v10/src/FP/ch/present.c.o(.text);
        build/us.v10/src/FP/ch/wozza.c.o(.text);
        build/us.v10/src/FP/ch/wozzasjig.c.o(.text);
        build/us.v10/src/FP/ch/boggy3.c.o(.text);
        build/us.v10/src/FP/code_A1C0.c.o(.text);
        build/us.v10/src/FP/ch/cavewozza.c.o(.text);
        build/us.v10/src/FP/ch/xmastreeice.c.o(.text);
        build/us.v10/src/FP/ch/xmastreeeggtoll.c.o(.text);
        build/us.v10/src/FP/fpspawnqueue.c.o(.text);
        build/us.v10/src/FP/code_B4D0.c.o(.text);
        . = ALIGN(., 16);
        FP_TEXT_END = .;
        FP_TEXT_SIZE = ABSOLUTE(FP_TEXT_END - FP_TEXT_START);
        FP_DATA_START = .;
        build/us.v10/src/FP/ch/scarfsled.c.o(.data);
        build/us.v10/src/FP/ch/racesled.c.o(.data);
        build/us.v10/src/FP/ch/snowmanbutton.c.o(.data);
        build/us.v10/src/FP/ch/xmastree.c.o(.data);
        build/us.v10/src/FP/ch/boggy1.c.o(.data);
        build/us.v10/src/FP/ch/boggyraceflag1.c.o(.data);
        build/us.v10/src/FP/ch/boggyraceflag2.c.o(.data);
        build/us.v10/src/FP/ch/boggy2.c.o(.data);
        build/us.v10/src/FP/ch/bearcub.c.o(.data);
        build/us.v10/src/FP/ma/snowy.c.o(.data);
        build/us.v10/src/FP/ma/snowbutton.c.o(.data);
        build/us.v10/src/FP/ma/slalom.c.o(.data);
        build/us.v10/src/FP/ch/twinkly.c.o(.data);
        build/us.v10/src/FP/ch/twinklybox.c.o(.data);
        build/us.v10/src/FP/ch/twinklymuncher.c.o(.data);
        build/us.v10/src/FP/ch/xmastreeswitch.c.o(.data);
        build/us.v10/src/FP/ch/xmastreestar.c.o(.data);
        build/us.v10/src/FP/ch/present.c.o(.data);
        build/us.v10/src/FP/ch/wozza.c.o(.data);
        build/us.v10/src/FP/ch/wozzasjig.c.o(.data);
        build/us.v10/src/FP/ch/boggy3.c.o(.data);
        build/us.v10/src/FP/code_A1C0.c.o(.data);
        build/us.v10/src/FP/ch/cavewozza.c.o(.data);
        build/us.v10/src/FP/ch/xmastreeice.c.o(.data);
        build/us.v10/src/FP/ch/xmastreeeggtoll.c.o(.data);
        build/us.v10/src/FP/fpspawnqueue.c.o(.data);
        build/us.v10/src/FP/code_B4D0.c.o(.data);
        . = ALIGN(., 16);
        FP_DATA_END = .;
        FP_DATA_SIZE = ABSOLUTE(FP_DATA_END - FP_DATA_START);
        FP_RODATA_START = .;
        build/us.v10/src/FP/ch/scarfsled.c.o(.rodata);
        build/us.v10/src/FP/ch/racesled.c.o(.rodata);
        build/us.v10/src/FP/ch/snowmanbutton.c.o(.rodata);
        build/us.v10/src/FP/ch/xmastree.c.o(.rodata);
        build/us.v10/src/FP/ch/boggy1.c.o(.rodata);
        build/us.v10/src/FP/ch/boggyraceflag1.c.o(.rodata);
        build/us.v10/src/FP/ch/boggyraceflag2.c.o(.rodata);
        build/us.v10/src/FP/ch/boggy2.c.o(.rodata);
        build/us.v10/src/FP/ch/bearcub.c.o(.rodata);
        build/us.v10/src/FP/ma/snowy.c.o(.rodata);
        build/us.v10/src/FP/ma/snowbutton.c.o(.rodata);
        build/us.v10/src/FP/ma/slalom.c.o(.rodata);
        build/us.v10/src/FP/ch/twinkly.c.o(.rodata);
        build/us.v10/src/FP/ch/twinklybox.c.o(.rodata);
        build/us.v10/src/FP/ch/twinklymuncher.c.o(.rodata);
        build/us.v10/src/FP/ch/xmastreeswitch.c.o(.rodata);
        build/us.v10/src/FP/ch/xmastreestar.c.o(.rodata);
        build/us.v10/src/FP/ch/present.c.o(.rodata);
        build/us.v10/src/FP/ch/wozza.c.o(.rodata);
        build/us.v10/src/FP/ch/wozzasjig.c.o(.rodata);
        build/us.v10/src/FP/ch/boggy3.c.o(.rodata);
        build/us.v10/src/FP/code_A1C0.c.o(.rodata);
        build/us.v10/src/FP/ch/cavewozza.c.o(.rodata);
        build/us.v10/src/FP/ch/xmastreeice.c.o(.rodata);
        build/us.v10/src/FP/ch/xmastreeeggtoll.c.o(.rodata);
        build/us.v10/src/FP/fpspawnqueue.c.o(.rodata);
        build/us.v10/src/FP/code_B4D0.c.o(.rodata);
        . = ALIGN(., 16);
        FP_RODATA_END = .;
        FP_RODATA_SIZE = ABSOLUTE(FP_RODATA_END - FP_RODATA_START);
    }
    FP_bss_VRAM = ADDR(.FP_bss);
    .FP_bss (NOLOAD) : SUBALIGN(16)
    {
        FILL(0x00000000);
        FP_BSS_START = .;
        build/us.v10/src/FP/ch/scarfsled.c.o(.bss);
        build/us.v10/src/FP/ch/racesled.c.o(.bss);
        build/us.v10/src/FP/ch/snowmanbutton.c.o(.bss);
        build/us.v10/src/FP/ch/xmastree.c.o(.bss);
        build/us.v10/src/FP/ch/boggy1.c.o(.bss);
        build/us.v10/src/FP/ch/boggyraceflag1.c.o(.bss);
        build/us.v10/src/FP/ch/boggyraceflag2.c.o(.bss);
        build/us.v10/src/FP/checksums.c.o(.bss);
        build/us.v10/src/FP/ch/boggy2.c.o(.bss);
        build/us.v10/src/FP/ch/bearcub.c.o(.bss);
        build/us.v10/src/FP/ma/snowy.c.o(.bss);
        build/us.v10/src/FP/ma/snowbutton.c.o(.bss);
        build/us.v10/src/FP/ma/slalom.c.o(.bss);
        build/us.v10/src/FP/ch/twinkly.c.o(.bss);
        build/us.v10/src/FP/ch/twinklybox.c.o(.bss);
        build/us.v10/src/FP/ch/twinklymuncher.c.o(.bss);
        build/us.v10/src/FP/ch/xmastreeswitch.c.o(.bss);
        build/us.v10/src/FP/ch/xmastreestar.c.o(.bss);
        build/us.v10/src/FP/ch/present.c.o(.bss);
        build/us.v10/src/FP/ch/wozza.c.o(.bss);
        build/us.v10/src/FP/ch/wozzasjig.c.o(.bss);
        build/us.v10/src/FP/ch/boggy3.c.o(.bss);
        build/us.v10/src/FP/code_A1C0.c.o(.bss);
        build/us.v10/src/FP/ch/cavewozza.c.o(.bss);
        build/us.v10/src/FP/ch/xmastreeice.c.o(.bss);
        build/us.v10/src/FP/ch/xmastreeeggtoll.c.o(.bss);
        build/us.v10/src/FP/fpspawnqueue.c.o(.bss);
        build/us.v10/src/FP/code_B4D0.c.o(.bss);
        . = ALIGN(., 16);
        FP_BSS_END = .;
        FP_BSS_SIZE = ABSOLUTE(FP_BSS_END - FP_BSS_START);
    }
    __romPos += SIZEOF(.FP);
    __romPos = ALIGN(__romPos, 16);
    . = ALIGN(., 16);
    FP_ROM_END = __romPos;
    FP_VRAM_END = .;

    SM_ROM_START = __romPos;
    SM_VRAM = ADDR(.SM);
    .SM core2_VRAM_END : AT(SM_ROM_START) SUBALIGN(16)
    {
        FILL(0x00000000);
        SM_TEXT_START = .;
        build/us.v10/src/SM/code_0.c.o(.text);
        build/us.v10/src/SM/smspawnqueue.c.o(.text);
        build/us.v10/src/SM/code_5B0.c.o(.text);
        build/us.v10/src/SM/code_BF0.c.o(.text);
        build/us.v10/src/SM/ch/attacktutorial.c.o(.text);
        build/us.v10/src/SM/ch/vegetables.c.o(.text);
        build/us.v10/src/SM/code_2900.c.o(.text);
        build/us.v10/src/SM/ch/smbottles.c.o(.text);
        build/us.v10/src/SM/code_3FC0.c.o(.text);
        build/us.v10/src/SM/ch/jumptutorial.c.o(.text);
        build/us.v10/src/SM/code_44D0.c.o(.text);
        build/us.v10/src/SM/code_46C0.c.o(.text);
        . = ALIGN(., 16);
        SM_TEXT_END = .;
        SM_TEXT_SIZE = ABSOLUTE(SM_TEXT_END - SM_TEXT_START);
        SM_DATA_START = .;
        build/us.v10/src/SM/code_0.c.o(.data);
        build/us.v10/src/SM/smspawnqueue.c.o(.data);
        build/us.v10/src/SM/code_5B0.c.o(.data);
        build/us.v10/src/SM/code_BF0.c.o(.data);
        build/us.v10/src/SM/ch/attacktutorial.c.o(.data);
        build/us.v10/src/SM/ch/vegetables.c.o(.data);
        build/us.v10/src/SM/code_2900.c.o(.data);
        build/us.v10/src/SM/ch/smbottles.c.o(.data);
        build/us.v10/src/SM/code_3FC0.c.o(.data);
        build/us.v10/src/SM/ch/jumptutorial.c.o(.data);
        build/us.v10/src/SM/code_44D0.c.o(.data);
        build/us.v10/src/SM/code_46C0.c.o(.data);
        . = ALIGN(., 16);
        SM_DATA_END = .;
        SM_DATA_SIZE = ABSOLUTE(SM_DATA_END - SM_DATA_START);
        SM_RODATA_START = .;
        build/us.v10/src/SM/code_0.c.o(.rodata);
        build/us.v10/src/SM/smspawnqueue.c.o(.rodata);
        build/us.v10/src/SM/code_5B0.c.o(.rodata);
        build/us.v10/src/SM/code_BF0.c.o(.rodata);
        build/us.v10/src/SM/ch/attacktutorial.c.o(.rodata);
        build/us.v10/src/SM/ch/vegetables.c.o(.rodata);
        build/us.v10/src/SM/code_2900.c.o(.rodata);
        build/us.v10/src/SM/ch/smbottles.c.o(.rodata);
        build/us.v10/src/SM/code_3FC0.c.o(.rodata);
        build/us.v10/src/SM/ch/jumptutorial.c.o(.rodata);
        build/us.v10/src/SM/code_44D0.c.o(.rodata);
        build/us.v10/src/SM/code_46C0.c.o(.rodata);
        . = ALIGN(., 16);
        SM_RODATA_END = .;
        SM_RODATA_SIZE = ABSOLUTE(SM_RODATA_END - SM_RODATA_START);
    }
    SM_bss_VRAM = ADDR(.SM_bss);
    .SM_bss (NOLOAD) : SUBALIGN(16)
    {
        FILL(0x00000000);
        SM_BSS_START = .;
        build/us.v10/src/SM/code_0.c.o(.bss);
        build/us.v10/src/SM/checksums.c.o(.bss);
        build/us.v10/src/SM/smspawnqueue.c.o(.bss);
        build/us.v10/src/SM/code_5B0.c.o(.bss);
        build/us.v10/src/SM/code_BF0.c.o(.bss);
        build/us.v10/src/SM/ch/attacktutorial.c.o(.bss);
        build/us.v10/src/SM/ch/vegetables.c.o(.bss);
        build/us.v10/src/SM/code_2900.c.o(.bss);
        build/us.v10/src/SM/ch/smbottles.c.o(.bss);
        build/us.v10/src/SM/code_3FC0.c.o(.bss);
        build/us.v10/src/SM/ch/jumptutorial.c.o(.bss);
        build/us.v10/src/SM/code_44D0.c.o(.bss);
        build/us.v10/src/SM/code_46C0.c.o(.bss);
        . = ALIGN(., 16);
        SM_BSS_END = .;
        SM_BSS_SIZE = ABSOLUTE(SM_BSS_END - SM_BSS_START);
    }
    __romPos += SIZEOF(.SM);
    __romPos = ALIGN(__romPos, 16);
    . = ALIGN(., 16);
    SM_ROM_END = __romPos;
    SM_VRAM_END = .;

    cutscenes_ROM_START = __romPos;
    cutscenes_VRAM = ADDR(.cutscenes);
    .cutscenes core2_VRAM_END : AT(cutscenes_ROM_START) SUBALIGN(16)
    {
        FILL(0x00000000);
        cutscenes_TEXT_START = .;
        build/us.v10/src/cutscenes/code_0.c.o(.text);
        build/us.v10/src/cutscenes/cutscenesspawnqueue.c.o(.text);
        build/us.v10/src/cutscenes/code_6730.c.o(.text);
        build/us.v10/src/cutscenes/code_69F0.c.o(.text);
        build/us.v10/src/cutscenes/code_6C90.c.o(.text);
        . = ALIGN(., 16);
        cutscenes_TEXT_END = .;
        cutscenes_TEXT_SIZE = ABSOLUTE(cutscenes_TEXT_END - cutscenes_TEXT_START);
        cutscenes_DATA_START = .;
        build/us.v10/src/cutscenes/code_0.c.o(.data);
        build/us.v10/src/cutscenes/cutscenesspawnqueue.c.o(.data);
        build/us.v10/src/cutscenes/code_6730.c.o(.data);
        build/us.v10/src/cutscenes/code_69F0.c.o(.data);
        build/us.v10/src/cutscenes/code_6C90.c.o(.data);
        . = ALIGN(., 16);
        cutscenes_DATA_END = .;
        cutscenes_DATA_SIZE = ABSOLUTE(cutscenes_DATA_END - cutscenes_DATA_START);
        cutscenes_RODATA_START = .;
        build/us.v10/src/cutscenes/code_0.c.o(.rodata);
        build/us.v10/src/cutscenes/cutscenesspawnqueue.c.o(.rodata);
        build/us.v10/src/cutscenes/code_6730.c.o(.rodata);
        build/us.v10/src/cutscenes/code_69F0.c.o(.rodata);
        build/us.v10/src/cutscenes/code_6C90.c.o(.rodata);
        . = ALIGN(., 16);
        cutscenes_RODATA_END = .;
        cutscenes_RODATA_SIZE = ABSOLUTE(cutscenes_RODATA_END - cutscenes_RODATA_START);
    }
    cutscenes_bss_VRAM = ADDR(.cutscenes_bss);
    .cutscenes_bss (NOLOAD) : SUBALIGN(16)
    {
        FILL(0x00000000);
        cutscenes_BSS_START = .;
        build/us.v10/src/cutscenes/code_0.c.o(.bss);
        build/us.v10/src/cutscenes/cutscenesspawnqueue.c.o(.bss);
        build/us.v10/src/cutscenes/code_6730.c.o(.bss);
        build/us.v10/src/cutscenes/code_69F0.c.o(.bss);
        build/us.v10/src/cutscenes/code_6C90.c.o(.bss);
        build/us.v10/src/cutscenes/checksums.c.o(.bss);
        . = ALIGN(., 16);
        cutscenes_BSS_END = .;
        cutscenes_BSS_SIZE = ABSOLUTE(cutscenes_BSS_END - cutscenes_BSS_START);
    }
    __romPos += SIZEOF(.cutscenes);
    __romPos = ALIGN(__romPos, 16);
    . = ALIGN(., 16);
    cutscenes_ROM_END = __romPos;
    cutscenes_VRAM_END = .;

    lair_ROM_START = __romPos;
    lair_VRAM = ADDR(.lair);
    .lair core2_VRAM_END : AT(lair_ROM_START) SUBALIGN(16)
    {
        FILL(0x00000000);
        lair_TEXT_START = .;
        build/us.v10/src/lair/lairspawnqueue.c.o(.text);
        build/us.v10/src/lair/ch/cauldron.c.o(.text);
        build/us.v10/src/lair/ch/brentilda.c.o(.text);
        build/us.v10/src/lair/code_5ED0.c.o(.text);
        build/us.v10/src/lair/jigsawpicture.c.o(.text);
        build/us.v10/src/lair/ch/cheato.c.o(.text);
        build/us.v10/src/lair/ch/refillpillow.c.o(.text);
        build/us.v10/src/lair/code_A430.c.o(.text);
        build/us.v10/src/lair/ch/gruntling.c.o(.text);
        build/us.v10/src/lair/code_A810.c.o(.text);
        build/us.v10/src/lair/code_AD70.c.o(.text);
        build/us.v10/src/lair/ch/furnacefunprizes.c.o(.text);
        build/us.v10/src/lair/ch/lairgruntilda.c.o(.text);
        build/us.v10/src/lair/code_C6C0.c.o(.text);
        . = ALIGN(., 16);
        lair_TEXT_END = .;
        lair_TEXT_SIZE = ABSOLUTE(lair_TEXT_END - lair_TEXT_START);
        lair_DATA_START = .;
        build/us.v10/src/lair/lairspawnqueue.c.o(.data);
        build/us.v10/src/lair/ch/cauldron.c.o(.data);
        build/us.v10/src/lair/ch/brentilda.c.o(.data);
        build/us.v10/src/lair/code_5ED0.c.o(.data);
        build/us.v10/src/lair/jigsawpicture.c.o(.data);
        build/us.v10/src/lair/ch/cheato.c.o(.data);
        build/us.v10/src/lair/ch/refillpillow.c.o(.data);
        build/us.v10/src/lair/code_A430.c.o(.data);
        build/us.v10/src/lair/ch/gruntling.c.o(.data);
        build/us.v10/src/lair/code_A810.c.o(.data);
        build/us.v10/src/lair/code_AD70.c.o(.data);
        build/us.v10/src/lair/ch/furnacefunprizes.c.o(.data);
        build/us.v10/src/lair/ch/lairgruntilda.c.o(.data);
        build/us.v10/src/lair/code_C6C0.c.o(.data);
        . = ALIGN(., 16);
        lair_DATA_END = .;
        lair_DATA_SIZE = ABSOLUTE(lair_DATA_END - lair_DATA_START);
        lair_RODATA_START = .;
        build/us.v10/src/lair/lairspawnqueue.c.o(.rodata);
        build/us.v10/src/lair/ch/cauldron.c.o(.rodata);
        build/us.v10/src/lair/ch/brentilda.c.o(.rodata);
        build/us.v10/src/lair/code_5ED0.c.o(.rodata);
        build/us.v10/src/lair/jigsawpicture.c.o(.rodata);
        build/us.v10/src/lair/ch/cheato.c.o(.rodata);
        build/us.v10/src/lair/ch/refillpillow.c.o(.rodata);
        build/us.v10/src/lair/code_A430.c.o(.rodata);
        build/us.v10/src/lair/ch/gruntling.c.o(.rodata);
        build/us.v10/src/lair/code_A810.c.o(.rodata);
        build/us.v10/src/lair/code_AD70.c.o(.rodata);
        build/us.v10/src/lair/ch/furnacefunprizes.c.o(.rodata);
        build/us.v10/src/lair/ch/lairgruntilda.c.o(.rodata);
        build/us.v10/src/lair/code_C6C0.c.o(.rodata);
        . = ALIGN(., 16);
        lair_RODATA_END = .;
        lair_RODATA_SIZE = ABSOLUTE(lair_RODATA_END - lair_RODATA_START);
    }
    lair_bss_VRAM = ADDR(.lair_bss);
    .lair_bss (NOLOAD) : SUBALIGN(16)
    {
        FILL(0x00000000);
        lair_BSS_START = .;
        build/us.v10/src/lair/checksums.c.o(.bss);
        build/us.v10/src/lair/lairspawnqueue.c.o(.bss);
        build/us.v10/src/lair/ch/cauldron.c.o(.bss);
        build/us.v10/src/lair/ch/brentilda.c.o(.bss);
        build/us.v10/src/lair/code_5ED0.c.o(.bss);
        build/us.v10/src/lair/jigsawpicture.c.o(.bss);
        build/us.v10/src/lair/ch/cheato.c.o(.bss);
        build/us.v10/src/lair/ch/refillpillow.c.o(.bss);
        build/us.v10/src/lair/code_A430.c.o(.bss);
        build/us.v10/src/lair/ch/gruntling.c.o(.bss);
        build/us.v10/src/lair/code_A810.c.o(.bss);
        build/us.v10/src/lair/code_AD70.c.o(.bss);
        build/us.v10/src/lair/ch/furnacefunprizes.c.o(.bss);
        build/us.v10/src/lair/ch/lairgruntilda.c.o(.bss);
        build/us.v10/src/lair/code_C6C0.c.o(.bss);
        . = ALIGN(., 16);
        lair_BSS_END = .;
        lair_BSS_SIZE = ABSOLUTE(lair_BSS_END - lair_BSS_START);
    }
    __romPos += SIZEOF(.lair);
    __romPos = ALIGN(__romPos, 16);
    . = ALIGN(., 16);
    lair_ROM_END = __romPos;
    lair_VRAM_END = .;

    fight_ROM_START = __romPos;
    fight_VRAM = ADDR(.fight);
    .fight core2_VRAM_END : AT(fight_ROM_START) SUBALIGN(16)
    {
        FILL(0x00000000);
        fight_TEXT_START = .;
        build/us.v10/src/fight/fight.c.o(.text);
        build/us.v10/src/fight/chfinalboss.c.o(.text);
        build/us.v10/src/fight/chbossjinjo.c.o(.text);
        build/us.v10/src/fight/chbossjinjobase.c.o(.text);
        build/us.v10/src/fight/chstonejinjo.c.o(.text);
        build/us.v10/src/fight/chjinjonatorbase.c.o(.text);
        build/us.v10/src/fight/chspellbarrier.c.o(.text);
        build/us.v10/src/fight/chspellfireball.c.o(.text);
        build/us.v10/src/fight/chgreenblast.c.o(.text);
        build/us.v10/src/fight/chjinjonator.c.o(.text);
        build/us.v10/src/fight/chbossshadow.c.o(.text);
        . = ALIGN(., 16);
        fight_TEXT_END = .;
        fight_TEXT_SIZE = ABSOLUTE(fight_TEXT_END - fight_TEXT_START);
        fight_DATA_START = .;
        build/us.v10/src/fight/fight.c.o(.data);
        build/us.v10/src/fight/chfinalboss.c.o(.data);
        build/us.v10/src/fight/chbossjinjo.c.o(.data);
        build/us.v10/src/fight/chbossjinjobase.c.o(.data);
        build/us.v10/src/fight/chstonejinjo.c.o(.data);
        build/us.v10/src/fight/chjinjonatorbase.c.o(.data);
        build/us.v10/src/fight/chspellbarrier.c.o(.data);
        build/us.v10/src/fight/chspellfireball.c.o(.data);
        build/us.v10/src/fight/chgreenblast.c.o(.data);
        build/us.v10/src/fight/chjinjonator.c.o(.data);
        build/us.v10/src/fight/chbossshadow.c.o(.data);
        . = ALIGN(., 16);
        fight_DATA_END = .;
        fight_DATA_SIZE = ABSOLUTE(fight_DATA_END - fight_DATA_START);
        fight_RODATA_START = .;
        build/us.v10/src/fight/fight.c.o(.rodata);
        build/us.v10/src/fight/chfinalboss.c.o(.rodata);
        build/us.v10/src/fight/chbossjinjo.c.o(.rodata);
        build/us.v10/src/fight/chbossjinjobase.c.o(.rodata);
        build/us.v10/src/fight/chstonejinjo.c.o(.rodata);
        build/us.v10/src/fight/chjinjonatorbase.c.o(.rodata);
        build/us.v10/src/fight/chspellbarrier.c.o(.rodata);
        build/us.v10/src/fight/chspellfireball.c.o(.rodata);
        build/us.v10/src/fight/chgreenblast.c.o(.rodata);
        build/us.v10/src/fight/chjinjonator.c.o(.rodata);
        build/us.v10/src/fight/chbossshadow.c.o(.rodata);
        . = ALIGN(., 16);
        fight_RODATA_END = .;
        fight_RODATA_SIZE = ABSOLUTE(fight_RODATA_END - fight_RODATA_START);
    }
    fight_bss_VRAM = ADDR(.fight_bss);
    .fight_bss (NOLOAD) : SUBALIGN(16)
    {
        FILL(0x00000000);
        fight_BSS_START = .;
        build/us.v10/src/fight/checksums.c.o(.bss);
        build/us.v10/src/fight/fight.c.o(.bss);
        build/us.v10/src/fight/chfinalboss.c.o(.bss);
        build/us.v10/src/fight/chbossjinjo.c.o(.bss);
        build/us.v10/src/fight/chbossjinjobase.c.o(.bss);
        build/us.v10/src/fight/chstonejinjo.c.o(.bss);
        build/us.v10/src/fight/chjinjonatorbase.c.o(.bss);
        build/us.v10/src/fight/chspellbarrier.c.o(.bss);
        build/us.v10/src/fight/chspellfireball.c.o(.bss);
        build/us.v10/src/fight/chgreenblast.c.o(.bss);
        build/us.v10/src/fight/chjinjonator.c.o(.bss);
        build/us.v10/src/fight/chbossshadow.c.o(.bss);
        . = ALIGN(., 16);
        fight_BSS_END = .;
        fight_BSS_SIZE = ABSOLUTE(fight_BSS_END - fight_BSS_START);
    }
    __romPos += SIZEOF(.fight);
    __romPos = ALIGN(__romPos, 16);
    . = ALIGN(., 16);
    fight_ROM_END = __romPos;
    fight_VRAM_END = .;

    CCW_ROM_START = __romPos;
    CCW_VRAM = ADDR(.CCW);
    .CCW core2_VRAM_END : AT(CCW_ROM_START) SUBALIGN(16)
    {
        FILL(0x00000000);
        CCW_TEXT_START = .;
        build/us.v10/src/CCW/ch/zubbadoor.c.o(.text);
        build/us.v10/src/CCW/ch/zubbahoneylump.c.o(.text);
        build/us.v10/src/CCW/code_950.c.o(.text);
        build/us.v10/src/CCW/code_14B0.c.o(.text);
        build/us.v10/src/CCW/ch/beanstalk.c.o(.text);
        build/us.v10/src/CCW/ch/deadbeanstalk.c.o(.text);
        build/us.v10/src/CCW/ch/ccwgobi.c.o(.text);
        build/us.v10/src/CCW/ch/seasonswitchdoors.c.o(.text);
        build/us.v10/src/CCW/ch/eyrieegg.c.o(.text);
        build/us.v10/src/CCW/code_3310.c.o(.text);
        build/us.v10/src/CCW/ch/caterpillar.c.o(.text);
        build/us.v10/src/CCW/ch/adulteyrie.c.o(.text);
        build/us.v10/src/CCW/ch/cutsceneadulteyrie.c.o(.text);
        build/us.v10/src/CCW/ch/springnabnut.c.o(.text);
        build/us.v10/src/CCW/ch/bellyfullnabnut.c.o(.text);
        build/us.v10/src/CCW/ch/outsideautumnnabnut.c.o(.text);
        build/us.v10/src/CCW/code_5BF0.c.o(.text);
        build/us.v10/src/CCW/ch/acorn.c.o(.text);
        build/us.v10/src/CCW/ch/swimminggnawty.c.o(.text);
        build/us.v10/src/CCW/ch/summeroutsidegnawty.c.o(.text);
        build/us.v10/src/CCW/ch/indoorsgnawty.c.o(.text);
        build/us.v10/src/CCW/ch/gnawtyboulder.c.o(.text);
        build/us.v10/src/CCW/ch/snore.c.o(.text);
        build/us.v10/src/CCW/ccwspawnqueue.c.o(.text);
        build/us.v10/src/CCW/ch/deadsnarebear.c.o(.text);
        build/us.v10/src/CCW/ch/snarebear.c.o(.text);
        build/us.v10/src/CCW/ch/grublinhood.c.o(.text);
        build/us.v10/src/CCW/ch/vacationtexttrigger.c.o(.text);
        . = ALIGN(., 16);
        CCW_TEXT_END = .;
        CCW_TEXT_SIZE = ABSOLUTE(CCW_TEXT_END - CCW_TEXT_START);
        CCW_DATA_START = .;
        build/us.v10/src/CCW/ch/zubbadoor.c.o(.data);
        build/us.v10/src/CCW/ch/zubbahoneylump.c.o(.data);
        build/us.v10/src/CCW/code_950.c.o(.data);
        build/us.v10/src/CCW/code_14B0.c.o(.data);
        build/us.v10/src/CCW/ch/beanstalk.c.o(.data);
        build/us.v10/src/CCW/ch/deadbeanstalk.c.o(.data);
        build/us.v10/src/CCW/ch/ccwgobi.c.o(.data);
        build/us.v10/src/CCW/ch/seasonswitchdoors.c.o(.data);
        build/us.v10/src/CCW/ch/eyrieegg.c.o(.data);
        build/us.v10/src/CCW/code_3310.c.o(.data);
        build/us.v10/src/CCW/ch/caterpillar.c.o(.data);
        build/us.v10/src/CCW/ch/adulteyrie.c.o(.data);
        build/us.v10/src/CCW/ch/cutsceneadulteyrie.c.o(.data);
        build/us.v10/src/CCW/ch/springnabnut.c.o(.data);
        build/us.v10/src/CCW/ch/bellyfullnabnut.c.o(.data);
        build/us.v10/src/CCW/ch/outsideautumnnabnut.c.o(.data);
        build/us.v10/src/CCW/code_5BF0.c.o(.data);
        build/us.v10/src/CCW/ch/acorn.c.o(.data);
        build/us.v10/src/CCW/ch/swimminggnawty.c.o(.data);
        build/us.v10/src/CCW/ch/summeroutsidegnawty.c.o(.data);
        build/us.v10/src/CCW/ch/indoorsgnawty.c.o(.data);
        build/us.v10/src/CCW/ch/gnawtyboulder.c.o(.data);
        build/us.v10/src/CCW/ch/snore.c.o(.data);
        build/us.v10/src/CCW/ccwspawnqueue.c.o(.data);
        build/us.v10/src/CCW/ch/deadsnarebear.c.o(.data);
        build/us.v10/src/CCW/ch/snarebear.c.o(.data);
        build/us.v10/src/CCW/ch/grublinhood.c.o(.data);
        build/us.v10/src/CCW/ch/vacationtexttrigger.c.o(.data);
        . = ALIGN(., 16);
        CCW_DATA_END = .;
        CCW_DATA_SIZE = ABSOLUTE(CCW_DATA_END - CCW_DATA_START);
        CCW_RODATA_START = .;
        build/us.v10/src/CCW/ch/zubbadoor.c.o(.rodata);
        build/us.v10/src/CCW/ch/zubbahoneylump.c.o(.rodata);
        build/us.v10/src/CCW/code_950.c.o(.rodata);
        build/us.v10/src/CCW/code_14B0.c.o(.rodata);
        build/us.v10/src/CCW/ch/beanstalk.c.o(.rodata);
        build/us.v10/src/CCW/ch/deadbeanstalk.c.o(.rodata);
        build/us.v10/src/CCW/ch/ccwgobi.c.o(.rodata);
        build/us.v10/src/CCW/ch/seasonswitchdoors.c.o(.rodata);
        build/us.v10/src/CCW/ch/eyrieegg.c.o(.rodata);
        build/us.v10/src/CCW/code_3310.c.o(.rodata);
        build/us.v10/src/CCW/ch/caterpillar.c.o(.rodata);
        build/us.v10/src/CCW/ch/adulteyrie.c.o(.rodata);
        build/us.v10/src/CCW/ch/cutsceneadulteyrie.c.o(.rodata);
        build/us.v10/src/CCW/ch/springnabnut.c.o(.rodata);
        build/us.v10/src/CCW/ch/bellyfullnabnut.c.o(.rodata);
        build/us.v10/src/CCW/ch/outsideautumnnabnut.c.o(.rodata);
        build/us.v10/src/CCW/code_5BF0.c.o(.rodata);
        build/us.v10/src/CCW/ch/acorn.c.o(.rodata);
        build/us.v10/src/CCW/ch/swimminggnawty.c.o(.rodata);
        build/us.v10/src/CCW/ch/summeroutsidegnawty.c.o(.rodata);
        build/us.v10/src/CCW/ch/indoorsgnawty.c.o(.rodata);
        build/us.v10/src/CCW/ch/gnawtyboulder.c.o(.rodata);
        build/us.v10/src/CCW/ch/snore.c.o(.rodata);
        build/us.v10/src/CCW/ccwspawnqueue.c.o(.rodata);
        build/us.v10/src/CCW/ch/deadsnarebear.c.o(.rodata);
        build/us.v10/src/CCW/ch/snarebear.c.o(.rodata);
        build/us.v10/src/CCW/ch/grublinhood.c.o(.rodata);
        build/us.v10/src/CCW/ch/vacationtexttrigger.c.o(.rodata);
        . = ALIGN(., 16);
        CCW_RODATA_END = .;
        CCW_RODATA_SIZE = ABSOLUTE(CCW_RODATA_END - CCW_RODATA_START);
    }
    CCW_bss_VRAM = ADDR(.CCW_bss);
    .CCW_bss (NOLOAD) : SUBALIGN(16)
    {
        FILL(0x00000000);
        CCW_BSS_START = .;
        build/us.v10/src/CCW/ch/zubbadoor.c.o(.bss);
        build/us.v10/src/CCW/ch/zubbahoneylump.c.o(.bss);
        build/us.v10/src/CCW/code_950.c.o(.bss);
        build/us.v10/src/CCW/code_14B0.c.o(.bss);
        build/us.v10/src/CCW/ch/beanstalk.c.o(.bss);
        build/us.v10/src/CCW/ch/deadbeanstalk.c.o(.bss);
        build/us.v10/src/CCW/ch/ccwgobi.c.o(.bss);
        build/us.v10/src/CCW/ch/seasonswitchdoors.c.o(.bss);
        build/us.v10/src/CCW/ch/eyrieegg.c.o(.bss);
        build/us.v10/src/CCW/checksums.c.o(.bss);
        build/us.v10/src/CCW/code_3310.c.o(.bss);
        build/us.v10/src/CCW/ch/caterpillar.c.o(.bss);
        build/us.v10/src/CCW/ch/adulteyrie.c.o(.bss);
        build/us.v10/src/CCW/ch/cutsceneadulteyrie.c.o(.bss);
        build/us.v10/src/CCW/ch/springnabnut.c.o(.bss);
        build/us.v10/src/CCW/ch/bellyfullnabnut.c.o(.bss);
        build/us.v10/src/CCW/ch/outsideautumnnabnut.c.o(.bss);
        build/us.v10/src/CCW/code_5BF0.c.o(.bss);
        build/us.v10/src/CCW/ch/acorn.c.o(.bss);
        build/us.v10/src/CCW/ch/swimminggnawty.c.o(.bss);
        build/us.v10/src/CCW/ch/summeroutsidegnawty.c.o(.bss);
        build/us.v10/src/CCW/ch/indoorsgnawty.c.o(.bss);
        build/us.v10/src/CCW/ch/gnawtyboulder.c.o(.bss);
        build/us.v10/src/CCW/ch/snore.c.o(.bss);
        build/us.v10/src/CCW/ccwspawnqueue.c.o(.bss);
        build/us.v10/src/CCW/ch/deadsnarebear.c.o(.bss);
        build/us.v10/src/CCW/ch/snarebear.c.o(.bss);
        build/us.v10/src/CCW/ch/grublinhood.c.o(.bss);
        build/us.v10/src/CCW/ch/vacationtexttrigger.c.o(.bss);
        . = ALIGN(., 16);
        CCW_BSS_END = .;
        CCW_BSS_SIZE = ABSOLUTE(CCW_BSS_END - CCW_BSS_START);
    }
    __romPos += SIZEOF(.CCW);
    __romPos = ALIGN(__romPos, 16);
    . = ALIGN(., 16);
    CCW_ROM_END = __romPos;
    CCW_VRAM_END = .;

    emptyLvl_ROM_START = __romPos;
    emptyLvl_VRAM = ADDR(.emptyLvl);
    .emptyLvl core2_VRAM_END : AT(emptyLvl_ROM_START) SUBALIGN(16)
    {
        FILL(0x00000000);
        emptyLvl_TEXT_START = .;
        build/us.v10/src/emptyLvl/code_0.c.o(.text);
        . = ALIGN(., 16);
        emptyLvl_TEXT_END = .;
        emptyLvl_TEXT_SIZE = ABSOLUTE(emptyLvl_TEXT_END - emptyLvl_TEXT_START);
        emptyLvl_DATA_START = .;
        build/us.v10/src/emptyLvl/code_0.c.o(.data);
        . = ALIGN(., 16);
        emptyLvl_DATA_END = .;
        emptyLvl_DATA_SIZE = ABSOLUTE(emptyLvl_DATA_END - emptyLvl_DATA_START);
        emptyLvl_RODATA_START = .;
        build/us.v10/src/emptyLvl/code_0.c.o(.rodata);
        . = ALIGN(., 16);
        emptyLvl_RODATA_END = .;
        emptyLvl_RODATA_SIZE = ABSOLUTE(emptyLvl_RODATA_END - emptyLvl_RODATA_START);
    }
    emptyLvl_bss_VRAM = ADDR(.emptyLvl_bss);
    .emptyLvl_bss (NOLOAD) : SUBALIGN(16)
    {
        FILL(0x00000000);
        emptyLvl_BSS_START = .;
        build/us.v10/src/emptyLvl/checksums.c.o(.bss);
        build/us.v10/src/emptyLvl/code_0.c.o(.bss);
        . = ALIGN(., 16);
        emptyLvl_BSS_END = .;
        emptyLvl_BSS_SIZE = ABSOLUTE(emptyLvl_BSS_END - emptyLvl_BSS_START);
    }
    __romPos += SIZEOF(.emptyLvl);
    __romPos = ALIGN(__romPos, 16);
    . = ALIGN(., 16);
    emptyLvl_ROM_END = __romPos;
    emptyLvl_VRAM_END = .;

    .shstrtab 0 :
    {
        *(.shstrtab);
    }
    .mdebug 0 :
    {
        *(.mdebug);
    }
    .mdebug.abi32 0 :
    {
        *(.mdebug.abi32);
    }

    /DISCARD/ :
    {
        *(*);
    }
}
